VERSION ""

NS_ :

BS_:

BU_: WSM VT

BO_ 3221225472 VECTOR__INDEPENDENT_SIG_MSG: 0 Vector__XXX
 SG_ ArbitraryAddressCapable : 0|1@1+ (1,0) [0|1] "" Vector__XXX
 SG_ VehicleSystemInstance : 0|4@1+ (1,0) [0|15] "" Vector__XXX
 SG_ VehicleSystem : 0|7@1+ (1,0) [0|127] "" Vector__XXX
 SG_ VehicleSystem5 : 0|7@1+ (1,0) [0|127] "" Vector__XXX
 SG_ VehicleSystem4 : 0|7@1+ (1,0) [0|127] "" Vector__XXX
 SG_ VehicleSystem3 : 0|7@1+ (1,0) [0|127] "" Vector__XXX
 SG_ VehicleSystem2 : 0|7@1+ (1,0) [0|127] "" Vector__XXX
 SG_ VehicleSystem1 : 0|7@1+ (1,0) [0|127] "" Vector__XXX
 SG_ AreaPerTimeCapacity : 0|32@1- (1,0) [0|2147483647] "mm²/s" Vector__XXX
 SG_ Valve5ValveState : 0|4@1+ (1,0) [0|15] "" Vector__XXX
 SG_ Valve6LimitStatus : 0|3@1+ (1,0) [0|7] "" Vector__XXX
 SG_ Valve6ExtendedPortEstimatedFlow : 0|8@1+ (1,-125) [-125|125] "%" Vector__XXX
 SG_ Valve6RetractPortEstimatedFlow : 0|8@1+ (1,-125) [-125|125] "%" Vector__XXX
 SG_ Valve6ValveState : 0|4@1+ (1,0) [0|15] "" Vector__XXX
 SG_ Valve6FailSafeMode : 0|2@1+ (1,0) [0|3] "" Vector__XXX
 SG_ Valve7LimitStatus : 0|3@1+ (1,0) [0|7] "" Vector__XXX
 SG_ Valve7ExtendedPortEstimatedFlow : 0|8@1+ (1,-125) [-125|125] "%" Vector__XXX
 SG_ Valve7RetractPortEstimatedFlow : 0|8@1+ (1,-125) [-125|125] "%" Vector__XXX
 SG_ Valve7ValveState : 0|4@1+ (1,0) [0|15] "" Vector__XXX
 SG_ Valve7FailSafeMode : 0|2@1+ (1,0) [0|3] "" Vector__XXX
 SG_ Valve8LimitStatus : 0|3@1+ (1,0) [0|7] "" Vector__XXX
 SG_ Valve8ExtendedPortEstimatedFlow : 0|8@1+ (1,-125) [-125|125] "%" Vector__XXX
 SG_ Valve8RetractPortEstimatedFlow : 0|8@1+ (1,-125) [-125|125] "%" Vector__XXX
 SG_ Valve8ValveState : 0|4@1+ (1,0) [0|15] "" Vector__XXX
 SG_ Valve8FailSafeMode : 0|2@1+ (1,0) [0|3] "" Vector__XXX
 SG_ Valve9LimitStatus : 0|3@1+ (1,0) [0|7] "" Vector__XXX
 SG_ Valve9ExtendedPortEstimatedFlow : 0|8@1+ (1,-125) [-125|125] "%" Vector__XXX
 SG_ Valve9RetractPortEstimatedFlow : 0|8@1+ (1,-125) [-125|125] "%" Vector__XXX
 SG_ Valve9ValveState : 0|4@1+ (1,0) [0|15] "" Vector__XXX
 SG_ Valve9FailSafeMode : 0|2@1+ (1,0) [0|3] "" Vector__XXX
 SG_ Valve5ReturnPortPressure : 0|8@1+ (16,0) [0|4000] "kPa" Vector__XXX
 SG_ Valve6LimitStatus : 0|3@1+ (1,0) [0|7] "" Vector__XXX
 SG_ Valve6ExtendedPortMeasuredFlow : 0|8@1+ (1,-125) [-125|125] "%" Vector__XXX
 SG_ Valve6RetractPortMeasuredFlow : 0|8@1+ (1,-125) [-125|125] "%" Vector__XXX
 SG_ Valve6ExtendedPortPressure : 0|16@1+ (5,0) [0|321275] "kPa" Vector__XXX
 SG_ Valve6RetractPortPressure : 0|16@1+ (5,0) [0|321275] "kPa" Vector__XXX
 SG_ Valve6ReturnPortPressure : 0|8@1+ (16,0) [0|4000] "kPa" Vector__XXX
 SG_ Valve7LimitStatus : 0|3@1+ (1,0) [0|7] "" Vector__XXX
 SG_ Valve7ExtendedPortMeasuredFlow : 0|8@1+ (1,-125) [-125|125] "%" Vector__XXX
 SG_ Valve7RetractPortMeasuredFlow : 0|8@1+ (1,-125) [-125|125] "%" Vector__XXX
 SG_ Valve7ExtendedPortPressure : 0|16@1+ (5,0) [0|321275] "kPa" Vector__XXX
 SG_ Valve7RetractPortPressure : 0|16@1+ (5,0) [0|321275] "kPa" Vector__XXX
 SG_ Valve7ReturnPortPressure : 0|8@1+ (16,0) [0|4000] "kPa" Vector__XXX
 SG_ Valve8LimitStatus : 0|3@1+ (1,0) [0|7] "" Vector__XXX
 SG_ Valve8ExtendedPortMeasuredFlow : 0|8@1+ (1,-125) [-125|125] "%" Vector__XXX
 SG_ Valve8RetractPortMeasuredFlow : 0|8@1+ (1,-125) [-125|125] "%" Vector__XXX
 SG_ Valve8ExtendedPortPressure : 0|16@1+ (5,0) [0|321275] "kPa" Vector__XXX
 SG_ Valve8RetractPortPressure : 0|16@1+ (5,0) [0|321275] "kPa" Vector__XXX
 SG_ Valve8ReturnPortPressure : 0|8@1+ (16,0) [0|4000] "kPa" Vector__XXX
 SG_ Valve9LimitStatus : 0|3@1+ (1,0) [0|7] "" Vector__XXX
 SG_ Valve9ExtendedPortMeasuredFlow : 0|8@1+ (1,-125) [-125|125] "%" Vector__XXX
 SG_ Valve9RetractPortMeasuredFlow : 0|8@1+ (1,-125) [-125|125] "%" Vector__XXX
 SG_ Valve9ExtendedPortPressure : 0|16@1+ (5,0) [0|321275] "kPa" Vector__XXX
 SG_ Valve9RetractPortPressure : 0|16@1+ (5,0) [0|321275] "kPa" Vector__XXX
 SG_ Valve9ReturnPortPressure : 0|8@1+ (16,0) [0|4000] "kPa" Vector__XXX
 SG_ Valve5StateCmd : 0|4@1+ (1,0) [0|15] "" Vector__XXX
 SG_ Valve6PortFlowCmd : 0|8@1+ (0.4,0) [0|100] "%" Vector__XXX
 SG_ Valve6StateCmd : 0|4@1+ (1,0) [0|15] "" Vector__XXX
 SG_ Valve6FailSaveModeCmd : 0|2@1+ (1,0) [0|3] "" Vector__XXX
 SG_ Valve7PortFlowCmd : 0|8@1+ (0.4,0) [0|100] "%" Vector__XXX
 SG_ Valve7StateCmd : 0|4@1+ (1,0) [0|15] "" Vector__XXX
 SG_ Valve7FailSaveModeCmd : 0|2@1+ (1,0) [0|3] "" Vector__XXX
 SG_ Valve8PortFlowCmd : 0|8@1+ (0.4,0) [0|100] "%" Vector__XXX
 SG_ Valve8StateCmd : 0|4@1+ (1,0) [0|15] "" Vector__XXX
 SG_ Valve8FailSaveModeCmd : 0|2@1+ (1,0) [0|3] "" Vector__XXX
 SG_ Valve9PortFlowCmd : 0|8@1+ (0.4,0) [0|100] "%" Vector__XXX
 SG_ Valve9StateCmd : 0|4@1+ (1,0) [0|15] "" Vector__XXX
 SG_ Valve9FailSaveModeCmd : 0|2@1+ (1,0) [0|3] "" Vector__XXX
 SG_ ATTR_Archive : 0|1@1+ (1,0) [0|1] "" Vector__XXX
 SG_ ATTR_Directory : 0|1@1+ (1,0) [0|1] "" Vector__XXX
 SG_ ATTR_Hidden : 0|1@1+ (1,0) [0|1] "" Vector__XXX
 SG_ ATTR_Directory : 0|1@1+ (1,0) [0|1] "" Vector__XXX
 SG_ ATTR_Archive : 0|1@1+ (1,0) [0|1] "" Vector__XXX
 SG_ ValveState : 0|4@1+ (1,0) [0|15] "" Vector__XXX
 SG_ VTFunctionECUtoVT : 0|8@1+ (1,0) [0|255] "" Vector__XXX
 SG_ KeyActivationCode : 0|8@1+ (1,0) [0|2] "" Vector__XXX
 SG_ KeyObjectParentID : 0|16@1+ (1,0) [0|65535] "" Vector__XXX
 SG_ KeyObjectID : 0|16@1+ (1,0) [0|65535] "" Vector__XXX
 SG_ SoftKeyCode : 0|8@1+ (1,0) [0|255] "" Vector__XXX
 SG_ ButtonActivationCode : 0|8@1+ (1,0) [0|2] "" Vector__XXX
 SG_ ButtonObjectID : 0|16@1+ (1,0) [0|65535] "" Vector__XXX
 SG_ ButtonObjectParentID : 0|16@1+ (1,0) [0|65535] "" Vector__XXX
 SG_ ButtonKeyCode : 0|8@1+ (1,0) [0|255] "" Vector__XXX
 SG_ XPosition : 0|16@1+ (1,0) [0|65535] "" Vector__XXX
 SG_ YPosition : 0|16@1+ (1,0) [0|65535] "" Vector__XXX
 SG_ TouchState : 0|8@1+ (1,0) [0|255] "" Vector__XXX
 SG_ VTSelectInputObjectID : 0|16@1+ (1,0) [0|65535] "" Vector__XXX
 SG_ VTSelectInputObjectStatus : 0|8@1+ (1,0) [0|1] "" Vector__XXX
 SG_ VTEscObjectID : 0|16@1+ (1,0) [0|65535] "" Vector__XXX
 SG_ VTChangeNumericValueObjectID : 0|16@1+ (1,0) [0|65535] "" Vector__XXX
 SG_ VTChangeNumericValueValue : 0|32@1+ (1,0) [0|4294967295] "" Vector__XXX
 SG_ VTChangeActiveMaskObjectID : 0|16@1+ (1,0) [0|65535] "" Vector__XXX
 SG_ VTChangeSoftKeyMaskParentID : 0|16@1+ (1,0) [0|65535] "" Vector__XXX
 SG_ VTChangeSoftKeyMaskObjectID : 0|16@1+ (1,0) [0|65535] "" Vector__XXX
 SG_ ParentObjectID : 0|16@1+ (1,0) [0|65535] "" Vector__XXX
 SG_ ObjectToChangeStringValueID : 0|16@1+ (1,0) [0|65535] "" Vector__XXX
 SG_ DisplayActivationStatus1 : 0|1@1+ (1,0) [0|1] "" Vector__XXX
 SG_ VisibleDataAlarmMaskID : 0|16@1+ (1,0) [0|65535] "" Vector__XXX
 SG_ VisibleSoftKeyMaskID : 0|16@1+ (1,0) [0|65535] "" Vector__XXX
 SG_ ObjectPoolRecord : 0|56@1+ (1,0) [0|3338120000] "" Vector__XXX
 SG_ AuxiliaryFunctionObjectID : 0|16@1+ (1,0) [0|65535] "" Vector__XXX
 SG_ AssignmentErrorNotAccepted : 0|1@1+ (1,0) [0|1] "" Vector__XXX
 SG_ NumberOfInpuUnits : 0|8@1+ (1,0) [0|255] "" Vector__XXX
 SG_ IsEnabled : 0|8@1+ (1,0) [0|255] "" Vector__XXX
 SG_ AuxModelIdentification : 0|16@1+ (1,0) [0|65535] "" Vector__XXX
 SG_ InputStatusObjectId : 0|16@1+ (1,0) [0|255] "" Vector__XXX
 SG_ AuxInputEnable : 0|8@1+ (1,0) [0|1] "" Vector__XXX
 SG_ AuxErrorInvalidInputID : 0|1@1+ (1,0) [0|1] "" Vector__XXX
 SG_ AuxErrorAnyOther : 0|1@1+ (1,0) [0|1] "" Vector__XXX
 SG_ ObjectToShowHideID : 0|16@1+ (1,0) [0|65535] "" Vector__XXX
 SG_ ShowOrHide : 0|8@1+ (1,0) [0|1] "" Vector__XXX
 SG_ ObjectoEnableDisbaleID : 0|16@1+ (1,0) [0|65535] "" Vector__XXX
 SG_ EnableOrDisable : 0|8@1+ (1,0) [0|1] "" Vector__XXX
 SG_ SelectInputObjectID : 0|16@1+ (1,0) [0|65535] "" Vector__XXX
 SG_ SetFocusOpenForEditing : 0|8@1+ (1,0) [0|255] "" Vector__XXX
 SG_ NumberOfRepetitions_Audio : 0|8@1+ (1,0) [0|255] "" Vector__XXX
 SG_ Frequency_Audio : 0|16@1+ (1,0) [0|65535] "hz" Vector__XXX
 SG_ OnTimeDuration_Audio : 0|16@1+ (1,0) [0|65535] "ms" Vector__XXX
 SG_ OffTimeDuration_Audio : 0|16@1+ (1,0) [0|65535] "ms" Vector__XXX
 SG_ AudioVolume : 0|8@1+ (1,0) [0|100] "%" Vector__XXX
 SG_ ParentObjectID : 0|16@1+ (1,0) [0|65535] "" Vector__XXX
 SG_ ObjectToMoveID : 0|16@1+ (1,0) [0|65535] "" Vector__XXX
 SG_ XPosChangeTopLeft : 0|8@1+ (1,-127) [-127|128] "" Vector__XXX
 SG_ YPosChangeTopLeft : 0|8@1+ (1,-127) [-127|128] "" Vector__XXX
 SG_ ObjectToSizeID : 0|16@1+ (1,0) [0|65535] "" Vector__XXX
 SG_ NewWidth : 0|16@1+ (1,0) [0|65535] "" Vector__XXX
 SG_ NewHeight : 0|16@1+ (1,0) [0|65535] "" Vector__XXX
 SG_ ObjectToChangeColourID : 0|16@1+ (1,0) [0|65535] "" Vector__XXX
 SG_ NewBackgroundColour : 0|8@1+ (1,0) [0|255] "" Vector__XXX
 SG_ ObjectToChangeNumValueID : 0|16@1+ (1,0) [0|65535] "" Vector__XXX
 SG_ NewValue : 0|32@1+ (1,0) [0|65535] "" Vector__XXX
 SG_ ObjectToChangeEndPointID : 0|16@1+ (1,0) [0|65535] "" Vector__XXX
 SG_ Width : 0|16@1+ (1,0) [0|65535] "" Vector__XXX
 SG_ Height : 0|16@1+ (1,0) [0|65535] "" Vector__XXX
 SG_ LineDirection : 0|8@1+ (1,0) [0|1] "" Vector__XXX
 SG_ ObjectToChangeFontID : 0|16@1+ (1,0) [0|65535] "" Vector__XXX
 SG_ FontColour : 0|8@1+ (1,0) [0|255] "" Vector__XXX
 SG_ FontSize : 0|8@1+ (1,0) [0|255] "" Vector__XXX
 SG_ FontType : 0|8@1+ (1,0) [0|255] "" Vector__XXX
 SG_ FontStyle : 0|8@1+ (1,0) [0|255] "" Vector__XXX
 SG_ ObjectToChangeLineAttributesID : 0|16@1+ (1,0) [0|65535] "" Vector__XXX
 SG_ LineColour : 0|8@1+ (1,0) [0|255] "" Vector__XXX
 SG_ LineWidth : 0|8@1+ (1,0) [0|255] "" Vector__XXX
 SG_ LineArt : 0|16@1+ (1,0) [0|65535] "" Vector__XXX
 SG_ ObjectToChangeFillAttributesID : 0|16@1+ (1,0) [0|65535] "" Vector__XXX
 SG_ FillType : 0|8@1+ (1,0) [0|255] "" Vector__XXX
 SG_ FillColour : 0|8@1+ (1,0) [0|255] "" Vector__XXX
 SG_ FillPatternObjectID : 0|16@1+ (1,0) [0|65535] "" Vector__XXX
 SG_ WorkingSetObjectID : 0|16@1+ (1,0) [0|65535] "" Vector__XXX
 SG_ NewActiveMaskObjectID : 0|16@1+ (1,0) [0|65535] "" Vector__XXX
 SG_ MaskType : 0|8@1+ (1,0) [0|255] "" Vector__XXX
 SG_ DataOrAlarmMaskObjectID : 0|16@1+ (1,0) [0|65535] "" Vector__XXX
 SG_ NewSoftKeyMaskObjectID : 0|16@1+ (1,0) [0|65535] "" Vector__XXX
 SG_ ObjectToChangeAttributeID : 0|16@1+ (1,0) [0|65535] "" Vector__XXX
 SG_ AttributeID : 0|8@1+ (1,0) [0|16777200] "" Vector__XXX
 SG_ NewAttributeValue : 0|32@1+ (1,0) [0|0] "" Vector__XXX
 SG_ AlarmMaskObjectID : 0|16@1+ (1,0) [0|65535] "" Vector__XXX
 SG_ NewPriority : 0|8@1+ (1,0) [0|255] "" Vector__XXX
 SG_ ListInputObjectID : 0|16@1+ (1,0) [0|65535] "" Vector__XXX
 SG_ ListIndex : 0|8@1+ (1,0) [0|255] "" Vector__XXX
 SG_ NewObjectID : 0|16@1+ (1,0) [0|65535] "" Vector__XXX
 SG_ ObjectToChangeStringValueID : 0|16@1+ (1,0) [0|65535] "" Vector__XXX
 SG_ NewStringValue : 0|16@1+ (1,0) [0|65535] "" Vector__XXX
 SG_ ParentObjectID : 0|16@1+ (1,0) [0|65535] "" Vector__XXX
 SG_ ObjectToMoveID : 0|16@1+ (1,0) [0|65535] "" Vector__XXX
 SG_ XPosChangeTopLeftLong : 0|16@1- (1,0) [-32768|32767] "" Vector__XXX
 SG_ YPosChangeTopLeftLong : 0|16@1- (1,0) [-32768|32767] "" Vector__XXX
 SG_ ObjectToAssociateLabelWithID : 0|16@1+ (1,0) [0|65535] "" Vector__XXX
 SG_ StringVariableObjectID : 0|16@1+ (1,0) [0|65535] "" Vector__XXX
 SG_ GraphicRepresentationObjectID : 0|16@1+ (1,0) [0|255] "" Vector__XXX
 SG_ FontType : 0|8@1+ (1,0) [0|255] "" Vector__XXX
 SG_ PolygonObjectToChangeID : 0|16@1+ (1,0) [0|65535] "" Vector__XXX
 SG_ IndexOfThePointToReplace : 0|8@1+ (1,0) [0|255] "" Vector__XXX
 SG_ NewValueX : 0|16@1+ (1,0) [0|65535] "" Vector__XXX
 SG_ NewValueY : 0|16@1+ (1,0) [0|65535] "" Vector__XXX
 SG_ PolygonObjectToScaleID : 0|16@1+ (1,0) [0|65535] "" Vector__XXX
 SG_ NewWidthAttribute : 0|16@1+ (1,0) [0|65535] "" Vector__XXX
 SG_ NewHeigthAttribute : 0|16@1+ (1,0) [0|0] "" Vector__XXX
 SG_ GraphicsContextObjectID : 0|16@1+ (1,0) [0|65535] "" Vector__XXX
 SG_ SubCommandID : 0|8@1+ (1,0) [0|0] "" Vector__XXX
 SG_ ObjectToGetAttributeID : 0|16@1+ (1,0) [0|65535] "" Vector__XXX
 SG_ AttributeID : 0|8@1+ (1,0) [0|0] "" Vector__XXX
 SG_ ColourMapObjectID : 0|16@1+ (1,0) [0|65535] "" Vector__XXX
 SG_ LockUnlockCommand : 0|8@1+ (1,0) [0|1] "" Vector__XXX
 SG_ ObjectIDOfDataMaskToLock : 0|16@1+ (1,0) [0|65535] "" Vector__XXX
 SG_ LockTimeout : 0|16@1+ (1,0) [0|65535] "" Vector__XXX
 SG_ MacroObjecID : 0|8@1+ (1,0) [0|255] "" Vector__XXX
 SG_ MemoryRequired : 0|24@1+ (1,0) [0|16777200] "" Vector__XXX
 SG_ CodePlane : 0|8@1+ (1,0) [0|16] "" Vector__XXX
 SG_ FirstWideChar : 0|16@1+ (1,0) [0|65535] "" Vector__XXX
 SG_ LastWideChar : 0|16@1+ (1,0) [0|65535] "" Vector__XXX
 SG_ VersionLabelToStore : 0|56@1+ (1,0) [0|3338120000] "" Vector__XXX
 SG_ VersionLabelToLoad : 0|56@1+ (1,0) [0|3338120000] "" Vector__XXX
 SG_ VersionLabelToDelete : 0|56@1+ (1,0) [0|3338120000] "" Vector__XXX
 SG_ WSMaintenanceInitiating : 0|1@1+ (1,0) [0|1] "" Vector__XXX
 SG_ WSMaintenanceBitmask : 0|1@1+ (1,0) [0|1] "" Vector__XXX

BO_ 2565340673 VT21_WSM: 8 WSM
 SG_ VTFunctionECUtoVT M : 0|8@1+ (1,0) [0|255] "" Vector__XXX
 SG_ KeyActivationCode m0 : 8|8@1+ (1,0) [0|2] "" Vector__XXX
 SG_ KeyObjectParentID m0 : 32|16@1+ (1,0) [0|65535] "" Vector__XXX
 SG_ KeyObjectID m0 : 16|16@1+ (1,0) [0|65535] "" Vector__XXX
 SG_ SoftKeyCode m0 : 48|8@1+ (1,0) [0|255] "" Vector__XXX
 SG_ ButtonActivationCode m1 : 8|8@1+ (1,0) [0|2] "" Vector__XXX
 SG_ ButtonObjectID m1 : 16|16@1+ (1,0) [0|65535] "" Vector__XXX
 SG_ ButtonObjectParentID m1 : 32|16@1+ (1,0) [0|65535] "" Vector__XXX
 SG_ ButtonKeyCode m1 : 48|8@1+ (1,0) [0|255] "" Vector__XXX
 SG_ XPosition m2 : 8|16@1+ (1,0) [0|65535] "" Vector__XXX
 SG_ YPosition m2 : 24|16@1+ (1,0) [0|65535] "" Vector__XXX
 SG_ TouchState m2 : 40|8@1+ (1,0) [0|255] "" Vector__XXX
 SG_ VTSelectInputObjectID m3 : 8|16@1+ (1,0) [0|65535] "" Vector__XXX
 SG_ VTSelectInputObjectStatus m3 : 24|8@1+ (1,0) [0|1] "" Vector__XXX
 SG_ VTEscObjectID m4 : 8|16@1+ (1,0) [0|65535] "" Vector__XXX
 SG_ VTChangeNumericValueObjectID m5 : 8|16@1+ (1,0) [0|65535] "" Vector__XXX
 SG_ VTChangeNumericValueValue m5 : 32|32@1+ (1,0) [0|4294967295] "" Vector__XXX
 SG_ VTChangeActiveMaskObjectID m6 : 8|16@1+ (1,0) [0|65535] "" Vector__XXX
 SG_ VTChangeSoftKeyMaskParentID m7 : 8|16@1+ (1,0) [0|65535] "" Vector__XXX
 SG_ VTChangeSoftKeyMaskObjectID m7 : 24|16@1+ (1,0) [0|65535] "" Vector__XXX
 SG_ ParentObjectID m8 : 8|16@1+ (1,0) [0|65535] "" Vector__XXX
 SG_ ObjectToChangeStringValueID_Resp m8 : 24|16@1+ (1,0) [0|65535] "" Vector__XXX
 SG_ DisplayActivationStatus1 m9 : 8|1@1+ (1,0) [0|1] "" Vector__XXX
 SG_ VisibleDataAlarmMaskID m9 : 16|16@1+ (1,0) [0|65535] "" Vector__XXX
 SG_ VisibleSoftKeyMaskID m9 : 32|16@1+ (1,0) [0|65535] "" Vector__XXX
 SG_ ObjectPoolRecord m17 : 8|56@1+ (1,0) [0|3338120000] "" Vector__XXX
 SG_ AuxiliaryFunctionObjectID m32 : 8|16@1+ (1,0) [0|65535] "" Vector__XXX
 SG_ AssignmentErrorNotAccepted m32 : 24|1@1+ (1,0) [0|1] "" Vector__XXX
 SG_ NumberOfInpuUnits m34 : 8|8@1+ (1,0) [0|255] "" Vector__XXX
 SG_ IsEnabled m33 : 48|8@1+ (1,0) [0|255] "" Vector__XXX
 SG_ AuxModelIdentification m35 : 8|16@1+ (1,0) [0|65535] "" Vector__XXX
 SG_ InputStatusObjectId m37 : 8|16@1+ (1,0) [0|255] "" Vector__XXX
 SG_ AuxInputEnable m37 : 24|8@1+ (1,0) [0|1] "" Vector__XXX
 SG_ AuxErrorInvalidInputID m37 : 32|1@1+ (1,0) [0|1] "" Vector__XXX
 SG_ AuxErrorAnyOther m37 : 33|1@1+ (1,0) [0|1] "" Vector__XXX
 SG_ ObjectToShowHideID m160 : 8|16@1+ (1,0) [0|65535] "" Vector__XXX
 SG_ ShowOrHide m160 : 24|8@1+ (1,0) [0|1] "" Vector__XXX
 SG_ ObjectoEnableDisbaleID m161 : 8|16@1+ (1,0) [0|65535] "" Vector__XXX
 SG_ EnableOrDisable m161 : 24|8@1+ (1,0) [0|1] "" Vector__XXX
 SG_ SelectInputObjectID m162 : 8|16@1+ (1,0) [0|65535] "" Vector__XXX
 SG_ SetFocusOpenForEditing m162 : 24|8@1+ (1,0) [0|255] "" Vector__XXX
 SG_ NumberOfRepetitions_Audio m163 : 8|8@1+ (1,0) [0|255] "" Vector__XXX
 SG_ Frequency_Audio m163 : 16|16@1+ (1,0) [0|65535] "hz" Vector__XXX
 SG_ OnTimeDuration_Audio m163 : 32|16@1+ (1,0) [0|65535] "ms" Vector__XXX
 SG_ OffTimeDuration_Audio m163 : 48|16@1+ (1,0) [0|65535] "ms" Vector__XXX
 SG_ AudioVolume m164 : 8|8@1+ (1,0) [0|100] "%" Vector__XXX
 SG_ ParentObjectID_Location m165 : 8|16@1+ (1,0) [0|65535] "" Vector__XXX
 SG_ ObjectToMoveID_Location m165 : 24|16@1+ (1,0) [0|65535] "" Vector__XXX
 SG_ XPosChangeTopLeft m165 : 40|8@1+ (1,-127) [-127|128] "" Vector__XXX
 SG_ YPosChangeTopLeft m165 : 48|8@1+ (1,-127) [-127|128] "" Vector__XXX
 SG_ ObjectToSizeID m166 : 8|16@1+ (1,0) [0|65535] "" Vector__XXX
 SG_ NewWidth m166 : 24|16@1+ (1,0) [0|65535] "" Vector__XXX
 SG_ NewHeight m166 : 40|16@1+ (1,0) [0|65535] "" Vector__XXX
 SG_ ObjectToChangeColourID m167 : 8|16@1+ (1,0) [0|65535] "" Vector__XXX
 SG_ NewBackgroundColour m167 : 24|8@1+ (1,0) [0|255] "" Vector__XXX
 SG_ ObjectToChangeNumValueID m168 : 8|16@1+ (1,0) [0|65535] "" Vector__XXX
 SG_ NewValue m168 : 32|32@1+ (1,0) [0|65535] "" Vector__XXX
 SG_ ObjectToChangeEndPointID m169 : 8|16@1+ (1,0) [0|65535] "" Vector__XXX
 SG_ Width m169 : 24|16@1+ (1,0) [0|65535] "" Vector__XXX
 SG_ Height m169 : 40|16@1+ (1,0) [0|65535] "" Vector__XXX
 SG_ LineDirection m169 : 56|8@1+ (1,0) [0|1] "" Vector__XXX
 SG_ ObjectToChangeFontID m170 : 8|16@1+ (1,0) [0|65535] "" Vector__XXX
 SG_ FontColour m170 : 24|8@1+ (1,0) [0|255] "" Vector__XXX
 SG_ FontSize m170 : 32|8@1+ (1,0) [0|255] "" Vector__XXX
 SG_ FontType m170 : 40|8@1+ (1,0) [0|255] "" Vector__XXX
 SG_ FontStyle m170 : 48|8@1+ (1,0) [0|255] "" Vector__XXX
 SG_ ObjectToChangeLineAttributesID m171 : 8|16@1+ (1,0) [0|65535] "" Vector__XXX
 SG_ LineColour m171 : 24|8@1+ (1,0) [0|255] "" Vector__XXX
 SG_ LineWidth m171 : 32|8@1+ (1,0) [0|255] "" Vector__XXX
 SG_ LineArt m171 : 40|16@1+ (1,0) [0|65535] "" Vector__XXX
 SG_ ObjectToChangeFillAttributesID m172 : 8|16@1+ (1,0) [0|65535] "" Vector__XXX
 SG_ FillType m172 : 24|8@1+ (1,0) [0|255] "" Vector__XXX
 SG_ FillColour m172 : 32|8@1+ (1,0) [0|255] "" Vector__XXX
 SG_ FillPatternObjectID m172 : 40|16@1+ (1,0) [0|65535] "" Vector__XXX
 SG_ WorkingSetObjectID m173 : 8|16@1+ (1,0) [0|65535] "" Vector__XXX
 SG_ NewActiveMaskObjectID m173 : 24|16@1+ (1,0) [0|65535] "" Vector__XXX
 SG_ MaskType m174 : 8|8@1+ (1,0) [0|255] "" Vector__XXX
 SG_ DataOrAlarmMaskObjectID m174 : 16|16@1+ (1,0) [0|65535] "" Vector__XXX
 SG_ NewSoftKeyMaskObjectID m174 : 32|16@1+ (1,0) [0|65535] "" Vector__XXX
 SG_ ObjectToChangeAttributeID m175 : 8|16@1+ (1,0) [0|65535] "" Vector__XXX
 SG_ AttributeID_Change m175 : 24|8@1+ (1,0) [0|16777200] "" Vector__XXX
 SG_ NewAttributeValue m175 : 32|32@1+ (1,0) [0|0] "" Vector__XXX
 SG_ AlarmMaskObjectID m176 : 8|16@1+ (1,0) [0|65535] "" Vector__XXX
 SG_ NewPriority m176 : 24|8@1+ (1,0) [0|255] "" Vector__XXX
 SG_ ListInputObjectID m177 : 8|16@1+ (1,0) [0|65535] "" Vector__XXX
 SG_ ListIndex m177 : 24|8@1+ (1,0) [0|255] "" Vector__XXX
 SG_ NewObjectID m177 : 32|16@1+ (1,0) [0|65535] "" Vector__XXX
 SG_ ObjectToChangeStringValueID m179 : 8|16@1+ (1,0) [0|65535] "" Vector__XXX
 SG_ NewStringValue m179 : 24|16@1+ (1,0) [0|65535] "" Vector__XXX
 SG_ ParentObjectID_Position m180 : 8|16@1+ (1,0) [0|65535] "" Vector__XXX
 SG_ ObjectToMoveID_Position m180 : 24|16@1+ (1,0) [0|65535] "" Vector__XXX
 SG_ XPosChangeTopLeftLong m180 : 40|16@1- (1,0) [-32768|32767] "" Vector__XXX
 SG_ YPosChangeTopLeftLong m180 : 56|16@1- (1,0) [-32768|32767] "" Vector__XXX
 SG_ ObjectToAssociateLabelWithID m181 : 8|16@1+ (1,0) [0|65535] "" Vector__XXX
 SG_ StringVariableObjectID m181 : 24|16@1+ (1,0) [0|65535] "" Vector__XXX
 SG_ GraphicRepresentationObjectID m181 : 48|16@1+ (1,0) [0|255] "" Vector__XXX
 SG_ LabelFontType m181 : 40|8@1+ (1,0) [0|255] "" Vector__XXX
 SG_ PolygonObjectToChangeID m182 : 8|16@1+ (1,0) [0|65535] "" Vector__XXX
 SG_ IndexOfThePointToReplace m182 : 24|8@1+ (1,0) [0|255] "" Vector__XXX
 SG_ NewValueX m182 : 32|16@1+ (1,0) [0|65535] "" Vector__XXX
 SG_ NewValueY m182 : 48|16@1+ (1,0) [0|65535] "" Vector__XXX
 SG_ PolygonObjectToScaleID m183 : 8|16@1+ (1,0) [0|65535] "" Vector__XXX
 SG_ NewWidthAttribute m183 : 24|16@1+ (1,0) [0|65535] "" Vector__XXX
 SG_ NewHeigthAttribute m183 : 40|16@1+ (1,0) [0|0] "" Vector__XXX
 SG_ GraphicsContextObjectID m184 : 8|16@1+ (1,0) [0|65535] "" Vector__XXX
 SG_ SubCommandID m184 : 24|8@1+ (1,0) [0|0] "" Vector__XXX
 SG_ ObjectToGetAttributeID m185 : 8|16@1+ (1,0) [0|65535] "" Vector__XXX
 SG_ AttributeID m185 : 24|8@1+ (1,0) [0|0] "" Vector__XXX
 SG_ ColourMapObjectID m186 : 8|16@1+ (1,0) [0|65535] "" Vector__XXX
 SG_ LockUnlockCommand m189 : 8|8@1+ (1,0) [0|1] "" Vector__XXX
 SG_ ObjectIDOfDataMaskToLock m189 : 16|16@1+ (1,0) [0|65535] "" Vector__XXX
 SG_ LockTimeout m189 : 32|16@1+ (1,0) [0|65535] "" Vector__XXX
 SG_ MacroObjecID m190 : 8|8@1+ (1,0) [0|255] "" Vector__XXX
 SG_ MemoryRequired m192 : 16|24@1+ (1,0) [0|16777200] "" Vector__XXX
 SG_ CodePlane m193 : 8|8@1+ (1,0) [0|16] "" Vector__XXX
 SG_ FirstWideChar m193 : 16|16@1+ (1,0) [0|65535] "" Vector__XXX
 SG_ LastWideChar m193 : 32|16@1+ (1,0) [0|65535] "" Vector__XXX
 SG_ VersionLabelToStore m208 : 8|56@1+ (1,0) [0|3338120000] "" Vector__XXX
 SG_ VersionLabelToLoad m209 : 8|56@1+ (1,0) [0|3338120000] "" Vector__XXX
 SG_ VersionLabelToDelete m210 : 8|56@1+ (1,0) [0|3338120000] "" Vector__XXX
 SG_ WSMaintenanceInitiating m255 : 8|1@1+ (1,0) [0|1] "" Vector__XXX
 SG_ WSMaintenanceBitmask m255 : 15|1@1+ (1,0) [0|1] "" Vector__XXX

BO_ 2633895169 WSMSTR_WSM: 8 WSM
 SG_ NumberOfMembersInWorkingSet : 0|8@1+ (1,0) [1|250] "" Vector__XXX

BO_ 2565799425 ACL_WSM: 8 WSM
 SG_ ArbitraryAddressCapable : 63|1@1+ (1,0) [0|1] "" Vector__XXX
 SG_ IndustryGroup M : 60|3@1+ (1,0) [0|7] "" Vector__XXX
 SG_ VehicleSystemInstance : 56|4@1+ (1,0) [0|15] "" Vector__XXX
 SG_ Function : 40|8@1+ (1,0) [0|255] "" Vector__XXX
 SG_ FunctionInstance : 35|5@1+ (1,0) [0|31] "" Vector__XXX
 SG_ ECUInstance : 32|3@1+ (1,0) [0|7] "" Vector__XXX
 SG_ ManufacturerCode : 21|11@1+ (1,0) [0|2047] "" Vector__XXX
 SG_ IdentityNumber : 0|21@1+ (1,0) [0|2097150] "" Vector__XXX
 SG_ VehicleSystem m0 : 49|7@1+ (1,0) [0|127] "" Vector__XXX
 SG_ VehicleSystem5 m5 : 49|7@1+ (1,0) [0|127] "" Vector__XXX
 SG_ VehicleSystem4 m4 : 49|7@1+ (1,0) [0|127] "" Vector__XXX
 SG_ VehicleSystem3 m3 : 49|7@1+ (1,0) [0|127] "" Vector__XXX
 SG_ VehicleSystem2 m2 : 49|7@1+ (1,0) [0|127] "" Vector__XXX
 SG_ VehicleSystem1 m1 : 49|7@1+ (1,0) [0|127] "" Vector__XXX

BO_ 2565799678 ACL: 8 Vector__XXX
 SG_ ArbitraryAddressCapable : 63|1@1+ (1,0) [0|1] "" Vector__XXX
 SG_ IndustryGroup M : 60|3@1+ (1,0) [0|7] "" Vector__XXX
 SG_ VehicleSystemInstance : 56|4@1+ (1,0) [0|15] "" Vector__XXX
 SG_ Function : 40|8@1+ (1,0) [0|255] "" Vector__XXX
 SG_ FunctionInstance : 35|5@1+ (1,0) [0|31] "" Vector__XXX
 SG_ ECUInstance : 32|3@1+ (1,0) [0|7] "" Vector__XXX
 SG_ ManufacturerCode : 21|11@1+ (1,0) [0|2047] "" Vector__XXX
 SG_ IdentityNumber : 0|21@1+ (1,0) [0|2097150] "" Vector__XXX
 SG_ VehicleSystem m0 : 49|7@1+ (1,0) [0|127] "" Vector__XXX
 SG_ VehicleSystem5 m5 : 49|7@1+ (1,0) [0|127] "" Vector__XXX
 SG_ VehicleSystem4 m4 : 49|7@1+ (1,0) [0|127] "" Vector__XXX
 SG_ VehicleSystem3 m3 : 49|7@1+ (1,0) [0|127] "" Vector__XXX
 SG_ VehicleSystem2 m2 : 49|7@1+ (1,0) [0|127] "" Vector__XXX
 SG_ VehicleSystem1 m1 : 49|7@1+ (1,0) [0|127] "" Vector__XXX

BO_ 2632384254 VT12: 14 Vector__XXX
 SG_ AttributeID m185 : 24|8@1+ (1,0) [0|0] "" Vector__XXX
 SG_ VTFunctionVTtoECU M : 0|8@1+ (1,0) [0|255] "" Vector__XXX
 SG_ KeyActivationCode m0 : 8|8@1+ (1,0) [0|2] "" Vector__XXX
 SG_ KeyObjectID m0 : 16|16@1+ (1,0) [0|65535] "" Vector__XXX
 SG_ KeyObjectParentID m0 : 32|16@1+ (1,0) [0|65535] "" Vector__XXX
 SG_ SoftKeyCode m0 : 48|8@1+ (1,0) [0|255] "" Vector__XXX
 SG_ ButtonActivationCode m1 : 8|8@1+ (1,0) [0|2] "" Vector__XXX
 SG_ ButtonObjectID m1 : 16|16@1+ (1,0) [0|65535] "" Vector__XXX
 SG_ ButtonObjectParentID m1 : 32|16@1+ (1,0) [0|65535] "" Vector__XXX
 SG_ ButtonKeyCode m1 : 48|8@1+ (1,0) [0|255] "" Vector__XXX
 SG_ XPosition m2 : 8|16@1+ (1,0) [0|65535] "" Vector__XXX
 SG_ YPosition m2 : 24|16@1+ (1,0) [0|65535] "" Vector__XXX
 SG_ TouchState m2 : 40|8@1+ (1,0) [0|255] "" Vector__XXX
 SG_ VTSelectInputObjectID m3 : 8|16@1+ (1,0) [0|65535] "" Vector__XXX
 SG_ VTSelectInputObjectStatus m3 : 24|8@1+ (1,0) [0|1] "" Vector__XXX
 SG_ VTSelectInputObjectIsEdited m3 : 32|1@1+ (1,0) [0|1] "" Vector__XXX
 SG_ VTEscObjectID m4 : 8|16@1+ (1,0) [0|65535] "" Vector__XXX
 SG_ ErrorCodeVTEsc1 m4 : 24|1@1+ (1,0) [0|1] "" Vector__XXX
 SG_ ErrorCodeVTEsc2 m4 : 28|1@1+ (1,0) [0|1] "" Vector__XXX
 SG_ VTChangeNumericValueObjectID m5 : 8|16@1+ (1,0) [0|65535] "" Vector__XXX
 SG_ VTChangeNumericValueValue m5 : 32|32@1+ (1,0) [0|4294967295] "" Vector__XXX
 SG_ VTChangeActiveMaskObjectID m6 : 8|16@1+ (1,0) [0|65535] "" Vector__XXX
 SG_ ErrorCodeMissingObjects m6 : 26|1@1+ (1,0) [0|1] "" Vector__XXX
 SG_ ErrorCodeMaskOrChildObjectError m6 : 27|1@1+ (1,0) [0|1] "" Vector__XXX
 SG_ ErrorCodeAnyOtherError m6 : 28|1@1+ (1,0) [0|1] "" Vector__XXX
 SG_ ErrorCodePoolDeleted m6 : 29|1@1+ (1,0) [0|1] "" Vector__XXX
 SG_ VTChangeActiveMaskErrorID m6 : 32|16@1+ (1,0) [0|65535] "" Vector__XXX
 SG_ VTChangeActiveMaskParentID m6 : 48|16@1+ (1,0) [0|65535] "" Vector__XXX
 SG_ VTChangeSoftKeyMaskParentID m7 : 8|16@1+ (1,0) [0|65535] "" Vector__XXX
 SG_ VTChangeSoftKeyMaskObjectID m7 : 24|16@1+ (1,0) [0|65535] "" Vector__XXX
 SG_ ErrorCodeVTChangeSoftKeyMask1 m7 : 40|1@1+ (1,0) [0|1] "" Vector__XXX
 SG_ ErrorCodeVTChangeSoftKeyMask2 m7 : 41|1@1+ (1,0) [0|1] "" Vector__XXX
 SG_ ErrorCodeVTChangeSoftKeyMask3 m7 : 42|1@1+ (1,0) [0|1] "" Vector__XXX
 SG_ ErrorCodeVTChangeSoftKeyMask4 m7 : 43|1@1+ (1,0) [0|1] "" Vector__XXX
 SG_ ErrorCodeVTChangeSoftKeyMask5 m7 : 44|1@1+ (1,0) [0|1] "" Vector__XXX
 SG_ ObjectToChangeStringID m8 : 8|16@1+ (1,0) [0|65535] "" Vector__XXX
 SG_ EnteredStringValue m8 : 24|8@1+ (1,0) [0|255] "" Vector__XXX
 SG_ DisplayActivationStatus1 m9 : 8|1@1+ (1,0) [0|1] "" Vector__XXX
 SG_ VisibleDataAlarmMaskID m9 : 16|16@1+ (1,0) [0|65535] "" Vector__XXX
 SG_ VisibleSoftKeyMaskID m9 : 32|16@1+ (1,0) [0|65535] "" Vector__XXX
 SG_ ErrorCodeEndOfObjectPool1 m18 : 8|1@1+ (1,0) [0|1] "" Vector__XXX
 SG_ ErrorCodeEndOfObjectPool2 m18 : 9|1@1+ (1,0) [0|1] "" Vector__XXX
 SG_ ErrorCodeEndOfObjectPool3 m18 : 12|1@1+ (1,0) [0|1] "" Vector__XXX
 SG_ ParentObjectIdOfFaultyObject m18 : 16|16@1+ (1,0) [0|65535] "" Vector__XXX
 SG_ ObjectIdOfFaultyObject m18 : 32|16@1+ (1,0) [0|65535] "" Vector__XXX
 SG_ ErrorCodeObjectPool1 m18 : 48|1@1+ (1,0) [0|1] "" Vector__XXX
 SG_ ErrorCodeObjectPool2 m18 : 49|1@1+ (1,0) [0|1] "" Vector__XXX
 SG_ ErrorCodeObjectPool3 m18 : 50|1@1+ (1,0) [0|1] "" Vector__XXX
 SG_ ErrorCodeObjectPool4 m18 : 51|1@1+ (1,0) [0|1] "" Vector__XXX
 SG_ IdentityNumber m32 : 8|21@1+ (1,0) [0|2097150] "" Vector__XXX
 SG_ ManufacturerCode m32 : 29|11@1+ (1,0) [0|2047] "" Vector__XXX
 SG_ ECUInstance m32 : 40|3@1+ (1,0) [0|7] "" Vector__XXX
 SG_ FunctionInstance m32 : 43|5@1+ (1,0) [0|31] "" Vector__XXX
 SG_ AuxiliaryInputObjectID m32 : 80|16@1+ (1,0) [0|65535] "" Vector__XXX
 SG_ InputObjectId m33 : 8|16@1+ (1,0) [0|255] "" Vector__XXX
 SG_ Value1 m33 : 24|16@1+ (1,0) [0|65535] "" Vector__XXX
 SG_ Function m32 : 48|8@1+ (1,0) [0|255] "" Vector__XXX
 SG_ DeviceClass m32 : 57|7@1+ (1,0) [0|127] "" Vector__XXX
 SG_ IndustryGroup m32 : 64|3@1+ (1,0) [0|7] "" Vector__XXX
 SG_ DeviceClassInstance m32 : 67|4@1+ (1,0) [0|15] "" Vector__XXX
 SG_ SelfConfigurableAddress m32 : 71|1@1+ (1,0) [0|1] "" Vector__XXX
 SG_ AuxiliaryFunctionType m32 : 72|4@1+ (1,0) [0|15] "" Vector__XXX
 SG_ AuxiliaryFunctionObjectID m32 : 96|16@1+ (1,0) [0|65535] "" Vector__XXX
 SG_ Value2 m33 : 40|16@1+ (1,0) [0|65535] "" Vector__XXX
 SG_ AuxPreferredAssignmentRespError1 m34 : 8|1@1+ (1,0) [0|1] "" Vector__XXX
 SG_ AuxPreferredAssignmentRespError2 m34 : 9|1@1+ (1,0) [0|1] "" Vector__XXX
 SG_ AuxPreferredAssignmentRespError3 m34 : 10|1@1+ (1,0) [0|1] "" Vector__XXX
 SG_ AuxPreferredAssignmentRespError4 m34 : 11|1@1+ (1,0) [0|1] "" Vector__XXX
 SG_ InputStatusObjectId m37 : 8|16@1+ (1,0) [0|255] "" Vector__XXX
 SG_ AuxInputEnable m37 : 24|8@1+ (1,0) [0|1] "" Vector__XXX
 SG_ ObjectEscapeID m146 : 8|16@1+ (1,0) [0|65535] "" Vector__XXX
 SG_ ErrorCodeEscapeObj1 m146 : 24|1@1+ (1,0) [0|1] "" Vector__XXX
 SG_ ErrorCodeEscapeObj2 m146 : 28|1@1+ (1,0) [0|1] "" Vector__XXX
 SG_ ObjectToHideShowID m160 : 8|16@1+ (1,0) [0|65535] "" Vector__XXX
 SG_ ObjectShowStatus m160 : 24|8@1+ (1,0) [0|1] "" Vector__XXX
 SG_ ErrorCodeHideShowObj1 m160 : 32|1@1+ (1,0) [0|1] "" Vector__XXX
 SG_ ErrorCodeHideShowObj2 m160 : 33|1@1+ (1,0) [0|1] "" Vector__XXX
 SG_ ErrorCodeHideShowObj3 m160 : 35|1@1+ (1,0) [0|1] "" Vector__XXX
 SG_ ObjectToEnableDisableID m161 : 8|16@1+ (1,0) [0|65535] "" Vector__XXX
 SG_ ObjectEnableStatus m161 : 24|8@1+ (1,0) [0|1] "" Vector__XXX
 SG_ ErrorCodeEnableDisableObj1 m161 : 33|1@1+ (1,0) [0|1] "" Vector__XXX
 SG_ ErrorCodeEnableDisableObj2 m161 : 34|1@1+ (1,0) [0|1] "" Vector__XXX
 SG_ ErrorCodeEnableDisableObj3 m161 : 35|1@1+ (1,0) [0|1] "" Vector__XXX
 SG_ ErrorCodeEnableDisableObj4 m161 : 36|1@1+ (1,0) [0|1] "" Vector__XXX
 SG_ SelectInputObjectID m162 : 8|16@1+ (1,0) [0|65535] "" Vector__XXX
 SG_ ObjectSelectStatus m162 : 24|8@1+ (1,0) [0|2] "" Vector__XXX
 SG_ ErrorCodeSelectObject1 m162 : 32|1@1+ (1,0) [0|1] "" Vector__XXX
 SG_ ErrorCodeSelectObject2 m162 : 33|1@1+ (1,0) [0|1] "" Vector__XXX
 SG_ ErrorCodeSelectObject3 m162 : 34|1@1+ (1,0) [0|1] "" Vector__XXX
 SG_ ErrorCodeSelectObject4 m162 : 35|1@1+ (1,0) [0|1] "" Vector__XXX
 SG_ ErrorCodeSelectObject5 m162 : 36|1@1+ (1,0) [0|1] "" Vector__XXX
 SG_ ErrorCodeControlAudioDevice1 m163 : 8|1@1+ (1,0) [0|1] "" Vector__XXX
 SG_ ErrorCodeControlAudioDevice2 m163 : 12|1@1+ (1,0) [0|1] "" Vector__XXX
 SG_ ErrorCodeAudioVolume1 m164 : 8|1@1+ (1,0) [0|1] "" Vector__XXX
 SG_ ErrorCodeAudioVolume2 m164 : 12|1@1+ (1,0) [0|1] "" Vector__XXX
 SG_ ParentObjectID_ChildLoc m165 : 8|16@1+ (1,0) [0|65535] "" Vector__XXX
 SG_ ObjectToMoveID_Location m165 : 24|16@1+ (1,0) [0|65535] "" Vector__XXX
 SG_ ErrorCodeChangeChildLocation1 m165 : 40|1@1+ (1,0) [0|1] "" Vector__XXX
 SG_ ErrorCodeChangeChildLocation2 m165 : 41|1@1+ (1,0) [0|1] "" Vector__XXX
 SG_ ErrorCodeChangeChildLocation5 m165 : 44|1@1+ (1,0) [0|1] "" Vector__XXX
 SG_ ObjectToSizeID m166 : 8|16@1+ (1,0) [0|65535] "" Vector__XXX
 SG_ ErrorCodeObjToSize1 m166 : 24|1@1+ (1,0) [0|1] "" Vector__XXX
 SG_ ErrorCodeObjToSize2 m166 : 25|1@1+ (1,0) [0|1] "" Vector__XXX
 SG_ ErrorCodeObjToSize3 m166 : 26|1@1+ (1,0) [0|1] "" Vector__XXX
 SG_ ErrorCodeObjToSize4 m166 : 28|1@1+ (1,0) [0|1] "" Vector__XXX
 SG_ ObjectToChangeColourID m167 : 8|16@1+ (1,0) [0|65535] "" Vector__XXX
 SG_ NewBackgroundColour m167 : 24|8@1+ (1,0) [0|255] "" Vector__XXX
 SG_ ErrorCodeChangeColour1 m167 : 32|1@1+ (1,0) [0|1] "" Vector__XXX
 SG_ ErrorCodeChangeColour2 m167 : 33|1@1+ (1,0) [0|1] "" Vector__XXX
 SG_ ErrorCodeChangeColour3 m167 : 36|1@1+ (1,0) [0|1] "" Vector__XXX
 SG_ ObjectToChangeNumValueID m168 : 8|16@1+ (1,0) [0|65535] "" Vector__XXX
 SG_ ErrorCodeChangeNumValue1 m168 : 24|1@1+ (1,0) [0|1] "" Vector__XXX
 SG_ ErrorCodeChangeNumValue2 m168 : 25|1@1+ (1,0) [0|1] "" Vector__XXX
 SG_ ErrorCodeChangeNumValue3 m168 : 28|1@1+ (1,0) [0|1] "" Vector__XXX
 SG_ ValueOfTheObject m168 : 32|32@1+ (1,0) [0|2704] "" Vector__XXX
 SG_ ObjectToChangeEndPointID m169 : 8|16@1+ (1,0) [0|65535] "" Vector__XXX
 SG_ ErrorCodeChangeEditPoint1 m169 : 24|1@1+ (1,0) [0|1] "" Vector__XXX
 SG_ ErrorCodeChangeEditPoint2 m169 : 25|1@1+ (1,0) [0|1] "" Vector__XXX
 SG_ ErrorCodeChangeEditPoint3 m169 : 28|1@1+ (1,0) [0|1] "" Vector__XXX
 SG_ ObjectToChangeFontID m170 : 8|16@1+ (1,0) [0|65535] "" Vector__XXX
 SG_ ErrorCodeChangeFont1 m170 : 24|1@1+ (1,0) [0|1] "" Vector__XXX
 SG_ ErrorCodeChangeFont2 m170 : 25|1@1+ (1,0) [0|1] "" Vector__XXX
 SG_ ErrorCodeChangeFont4 m170 : 27|1@1+ (1,0) [0|1] "" Vector__XXX
 SG_ ErrorCodeChangeFont3 m170 : 26|1@1+ (1,0) [0|1] "" Vector__XXX
 SG_ ErrorCodeChangeFont5 m170 : 28|1@1+ (1,0) [0|1] "" Vector__XXX
 SG_ ErrorCodeChangeFont6 m170 : 29|1@1+ (1,0) [0|1] "" Vector__XXX
 SG_ ObjectToChangeLineAttributeID m171 : 8|16@1+ (1,0) [0|65535] "" Vector__XXX
 SG_ ErrorCodeChangeLineAttribute1 m171 : 24|1@1+ (1,0) [0|1] "" Vector__XXX
 SG_ ErrorCodeChangeLineAttribute2 m171 : 25|1@1+ (1,0) [0|1] "" Vector__XXX
 SG_ ErrorCodeChangeLineAttribute3 m171 : 26|1@1+ (1,0) [0|1] "" Vector__XXX
 SG_ ErrorCodeChangeLineAttribute4 m171 : 28|1@1+ (1,0) [0|1] "" Vector__XXX
 SG_ ObjectToChangeFillAttributesID m172 : 8|16@1+ (1,0) [0|65535] "" Vector__XXX
 SG_ ErrorCodeChangeFillAttributes1 m172 : 24|1@1+ (1,0) [0|1] "" Vector__XXX
 SG_ ErrorCodeChangeFillAttributes2 m172 : 25|1@1+ (1,0) [0|1] "" Vector__XXX
 SG_ ErrorCodeChangeFillAttributes3 m172 : 26|1@1+ (1,0) [0|1] "" Vector__XXX
 SG_ ErrorCodeChangeFillAttributes4 m172 : 27|1@1+ (1,0) [0|1] "" Vector__XXX
 SG_ ErrorCodeChangeFillAttributes5 m172 : 28|1@1+ (1,0) [0|1] "" Vector__XXX
 SG_ ActiveMaskObjectID m173 : 8|16@1+ (1,0) [0|0] "" Vector__XXX
 SG_ ErrorCodeChangeActiveMask1 m173 : 24|1@1+ (1,0) [0|1] "" Vector__XXX
 SG_ ErrorCodeChangeActiveMask2 m173 : 25|1@1+ (1,0) [0|1] "" Vector__XXX
 SG_ ErrorCodeChangeActiveMask3 m173 : 26|1@1+ (1,0) [0|1] "" Vector__XXX
 SG_ ErrorCodeChangeActiveMask4 m173 : 27|1@1+ (1,0) [0|1] "" Vector__XXX
 SG_ ErrorCodeChangeActiveMask5 m173 : 28|1@1+ (1,0) [0|1] "" Vector__XXX
 SG_ DataOrAlarmMaskObjectID m174 : 8|16@1+ (1,0) [0|65535] "" Vector__XXX
 SG_ SoftKeyMaskObjectID m174 : 24|16@1+ (1,0) [0|65535] "" Vector__XXX
 SG_ ErrorCodeChangeSoftKeyMask1 m174 : 40|1@1+ (1,0) [0|1] "" Vector__XXX
 SG_ ErrorCodeChangeSoftKeyMask2 m174 : 41|1@1+ (1,0) [0|1] "" Vector__XXX
 SG_ ErrorCodeChangeSoftKeyMask3 m174 : 42|1@1+ (1,0) [0|1] "" Vector__XXX
 SG_ ErrorCodeChangeSoftKeyMask4 m174 : 43|1@1+ (1,0) [0|1] "" Vector__XXX
 SG_ ErrorCodeChangeSoftKeyMask5 m174 : 44|1@1+ (1,0) [0|1] "" Vector__XXX
 SG_ ObjectToChangeAttributeID m175 : 8|16@1+ (1,0) [0|65535] "" Vector__XXX
 SG_ AttributeID_Change m175 : 24|8@1+ (1,0) [0|65535] "" Vector__XXX
 SG_ ErrorCodeChangeAttribute1 m175 : 32|1@1+ (1,0) [0|1] "" Vector__XXX
 SG_ ErrorCodeChangeAttribute2 m175 : 33|1@1+ (1,0) [0|1] "" Vector__XXX
 SG_ ErrorCodeChangeAttribute3 m175 : 34|1@1+ (1,0) [0|1] "" Vector__XXX
 SG_ ErrorCodeChangeAttribute4 m175 : 36|1@1+ (1,0) [0|1] "" Vector__XXX
 SG_ AlarmMaskObjectID m176 : 8|16@1+ (1,0) [0|65535] "" Vector__XXX
 SG_ NewPriority m176 : 24|8@1+ (1,0) [0|255] "" Vector__XXX
 SG_ ErrorCodeChangePriority1 m176 : 32|1@1+ (1,0) [0|1] "" Vector__XXX
 SG_ ErrorCodeChangePriority2 m176 : 33|1@1+ (1,0) [0|1] "" Vector__XXX
 SG_ ErrorCodeChangePriority3 m176 : 36|1@1+ (1,0) [0|1] "" Vector__XXX
 SG_ ListInputObjectID m177 : 8|16@1+ (1,0) [0|65535] "" Vector__XXX
 SG_ ListIndex m177 : 24|8@1+ (1,0) [0|255] "" Vector__XXX
 SG_ NewObjectID m177 : 32|16@1+ (1,0) [0|65535] "" Vector__XXX
 SG_ ErrorCodeChangeListItem1 m177 : 48|1@1+ (1,0) [0|1] "" Vector__XXX
 SG_ ErrorCodeChangeListItem2 m177 : 49|1@1+ (1,0) [0|1] "" Vector__XXX
 SG_ ErrorCodeChangeListItem3 m177 : 50|1@1+ (1,0) [0|1] "" Vector__XXX
 SG_ ErrorCodeChangeListItem4 m177 : 52|1@1+ (1,0) [0|1] "" Vector__XXX
 SG_ ErrorCodeDeleteObjectPool1 m178 : 8|1@1+ (1,0) [0|1] "" Vector__XXX
 SG_ ErrorCodeDeleteObjectPool2 m178 : 12|1@1+ (1,0) [0|1] "" Vector__XXX
 SG_ ParentObjectID_String m179 : 8|16@1+ (1,0) [0|65535] "" Vector__XXX
 SG_ ObjectToChangeStringValueID m179 : 24|16@1+ (1,0) [0|65535] "" Vector__XXX
 SG_ ErrorCodeChangeStrObjectID m179 : 41|1@1+ (1,0) [0|1] "" Vector__XXX
 SG_ ErrorCodeChangeStrTooLong m179 : 42|1@1+ (1,0) [0|1] "" Vector__XXX
 SG_ ErrorCodeChangeStrError m179 : 43|1@1+ (1,0) [0|1] "" Vector__XXX
 SG_ ParentObjectID_ChildPos m180 : 8|16@1+ (1,0) [0|65535] "" Vector__XXX
 SG_ ObjectToMoveID_Position m180 : 24|16@1+ (1,0) [0|65535] "" Vector__XXX
 SG_ ErrorCodeChangePosInvalidParent m180 : 40|1@1+ (1,0) [0|1] "" Vector__XXX
 SG_ ErrorCodeChangePosInvalidObject m180 : 41|1@1+ (1,0) [0|1] "" Vector__XXX
 SG_ ErrorCodeChangePosInvalidError m180 : 44|1@1+ (1,0) [0|1] "" Vector__XXX
 SG_ ErrorCodeSetObjectLabel1 m181 : 8|1@1+ (1,0) [0|1] "" Vector__XXX
 SG_ ErrorCodeSetObjectLabel2 m181 : 9|1@1+ (1,0) [0|1] "" Vector__XXX
 SG_ ErrorCodeSetObjectLabel3 m181 : 10|1@1+ (1,0) [0|1] "" Vector__XXX
 SG_ ErrorCodeSetObjectLabel4 m181 : 11|1@1+ (1,0) [0|1] "" Vector__XXX
 SG_ ErrorCodeSetObjectLabel5 m181 : 12|1@1+ (1,0) [0|1] "" Vector__XXX
 SG_ ErrorCodeSetObjectLabel6 m181 : 13|1@1+ (1,0) [0|1] "" Vector__XXX
 SG_ PolygonObjectToChangeID m182 : 8|16@1+ (1,0) [0|65535] "" Vector__XXX
 SG_ ErrorCodeChangePoygonPoint1 m182 : 24|1@1+ (1,0) [0|1] "" Vector__XXX
 SG_ ErrorCodeChangePoygonPoint2 m182 : 25|1@1+ (1,0) [0|1] "" Vector__XXX
 SG_ ErrorCodeChangePoygonPoint3 m182 : 26|1@1+ (1,0) [0|1] "" Vector__XXX
 SG_ PolygonObjectToScaleID m183 : 8|16@1+ (1,0) [0|65535] "" Vector__XXX
 SG_ NewWidthAttribute m183 : 24|16@1+ (1,0) [0|65535] "" Vector__XXX
 SG_ NewHeigthAttribute m183 : 40|16@1+ (1,0) [0|0] "" Vector__XXX
 SG_ ErrorCodeChangePolygonScale1 m183 : 56|1@1+ (1,0) [0|1] "" Vector__XXX
 SG_ ErrorCodeChangePolygonScale5 m183 : 60|1@1+ (1,0) [0|1] "" Vector__XXX
 SG_ GraphicsContextObjectID m184 : 8|16@1+ (1,0) [0|65535] "" Vector__XXX
 SG_ SubCommandID m184 : 24|8@1+ (1,0) [0|0] "" Vector__XXX
 SG_ ErrorCodeGraphicsContextCmd1 m184 : 32|1@1+ (1,0) [0|1] "" Vector__XXX
 SG_ ErrorCodeGraphicsContextCmd2 m184 : 33|1@1+ (1,0) [0|1] "" Vector__XXX
 SG_ ErrorCodeGraphicsContextCmd3 m184 : 34|1@1+ (1,0) [0|1] "" Vector__XXX
 SG_ ErrorCodeGraphicsContextCmd4 m184 : 35|1@1+ (1,0) [0|1] "" Vector__XXX
 SG_ ErrorCodeGraphicsContextCmd5 m184 : 36|1@1+ (1,0) [0|1] "" Vector__XXX
 SG_ ObjectToGetAttributeID_Resp m185 : 8|16@1+ (1,0) [0|65535] "" Vector__XXX
 SG_ ColourMapObjectID m186 : 8|16@1+ (1,0) [0|65535] "" Vector__XXX
 SG_ ErrorCodeSelectColourMap2 m186 : 25|1@1+ (1,0) [0|1] "" Vector__XXX
 SG_ ErrorCodeSelectColourMap1 m186 : 24|1@1+ (1,0) [0|1] "" Vector__XXX
 SG_ ErrorCodeLockUnlockMask9 m189 : 24|1@1+ (1,0) [0|1] "" Vector__XXX
 SG_ ErrorCodeLockUnlockMask8 m189 : 23|1@1+ (1,0) [0|1] "" Vector__XXX
 SG_ ErrorCodeLockUnlockMask7 m189 : 22|1@1+ (1,0) [0|1] "" Vector__XXX
 SG_ ErrorCodeLockUnlockMask6 m189 : 21|1@1+ (1,0) [0|1] "" Vector__XXX
 SG_ ErrorCodeLockUnlockMask5 m189 : 20|1@1+ (1,0) [0|1] "" Vector__XXX
 SG_ ErrorCodeLockUnlockMask4 m189 : 19|1@1+ (1,0) [0|1] "" Vector__XXX
 SG_ ErrorCodeLockUnlockMask3 m189 : 18|1@1+ (1,0) [0|1] "" Vector__XXX
 SG_ ErrorCodeLockUnlockMask2 m189 : 17|1@1+ (1,0) [0|1] "" Vector__XXX
 SG_ ErrorCodeLockUnlockMask1 m189 : 16|1@1+ (1,0) [0|1] "" Vector__XXX
 SG_ LockUnlockCommand m189 : 8|8@1+ (1,0) [0|1] "" Vector__XXX
 SG_ MacroObjecID m190 : 8|8@1+ (1,0) [0|255] "" Vector__XXX
 SG_ ErrorCodeExecuteMacro1 m190 : 16|1@1+ (1,0) [0|1] "" Vector__XXX
 SG_ ErrorCodeExecuteMacro2 m190 : 17|1@1+ (1,0) [0|1] "" Vector__XXX
 SG_ ErrorCodeExecuteMacro3 m190 : 18|1@1+ (1,0) [0|1] "" Vector__XXX
 SG_ VersionNumberISO11783Part6 m192 : 8|8@1+ (1,0) [0|255] "" Vector__XXX
 SG_ MemoryStatus m192 : 16|8@1+ (1,0) [0|1] "" Vector__XXX
 SG_ FirstWideChar m193 : 16|16@1+ (1,0) [0|65535] "" Vector__XXX
 SG_ LastWideChar m193 : 32|16@1+ (1,0) [0|65535] "" Vector__XXX
 SG_ ErrorCodeGetSupportedWideChars2 m193 : 52|1@1+ (1,0) [0|1] "" Vector__XXX
 SG_ ErrorCodeGetSupportedWideChars1 m193 : 48|1@1+ (1,0) [0|1] "" Vector__XXX
 SG_ CodePlane m193 : 8|8@1+ (1,0) [0|16] "" Vector__XXX
 SG_ NumberOfRanges m193 : 56|8@1+ (1,0) [0|255] "" Vector__XXX
 SG_ NavigationSoftKeys m194 : 8|8@1+ (1,0) [0|254] "" Vector__XXX
 SG_ XDotsForSoftKeyDescriptor m194 : 32|8@1+ (1,0) [0|255] "" Vector__XXX
 SG_ YDotsForSoftKeyDescriptor m194 : 40|8@1+ (1,0) [0|255] "" Vector__XXX
 SG_ NumberOfPossibleVirtualSoftKeys m194 : 48|8@1+ (1,0) [0|255] "" Vector__XXX
 SG_ NumberOfPhysicalSoftKeys m194 : 56|8@1+ (1,0) [0|255] "" Vector__XXX
 SG_ FontSize_8x8 m195 : 40|1@1+ (1,0) [0|1] "" Vector__XXX
 SG_ FontSize_8x12 m195 : 41|1@1+ (1,0) [0|1] "" Vector__XXX
 SG_ FontSize_12x16 m195 : 42|1@1+ (1,0) [0|1] "" Vector__XXX
 SG_ FontSize_16x16 m195 : 43|1@1+ (1,0) [0|1] "" Vector__XXX
 SG_ FontSize_16x24 m195 : 44|1@1+ (1,0) [0|1] "" Vector__XXX
 SG_ FontSize_24x32 m195 : 45|1@1+ (1,0) [0|1] "" Vector__XXX
 SG_ FontSize_32x32 m195 : 46|1@1+ (1,0) [0|1] "" Vector__XXX
 SG_ FontSize_32x48 m195 : 48|1@1+ (1,0) [0|1] "" Vector__XXX
 SG_ FontSize_48x64 m195 : 49|1@1+ (1,0) [0|1] "" Vector__XXX
 SG_ FontSize_64x64 m195 : 50|1@1+ (1,0) [0|1] "" Vector__XXX
 SG_ FontSize_64x96 m195 : 51|1@1+ (1,0) [0|1] "" Vector__XXX
 SG_ FontSize_96x128 m195 : 52|1@1+ (1,0) [0|1] "" Vector__XXX
 SG_ FontSize_128x128 m195 : 53|1@1+ (1,0) [0|1] "" Vector__XXX
 SG_ FontSize_128x192 m195 : 54|1@1+ (1,0) [0|1] "" Vector__XXX
 SG_ FontType_BoldText m195 : 56|1@1+ (1,0) [0|1] "" Vector__XXX
 SG_ FontType_CrossedOutText m195 : 57|1@1+ (1,0) [0|1] "" Vector__XXX
 SG_ FontType_UnderlinedText m195 : 58|1@1+ (1,0) [0|1] "" Vector__XXX
 SG_ FontType_ItalicsText m195 : 59|1@1+ (1,0) [0|1] "" Vector__XXX
 SG_ FontType_InvertedText m195 : 60|1@1+ (1,0) [0|1] "" Vector__XXX
 SG_ FontType_FlashInverted m195 : 61|1@1+ (1,0) [0|1] "" Vector__XXX
 SG_ FontType_FlashHidden m195 : 62|1@1+ (1,0) [0|1] "" Vector__XXX
 SG_ FontType_ProportionalFont m195 : 63|1@1+ (1,0) [0|1] "" Vector__XXX
 SG_ MaxLineWidth m196 : 8|8@1+ (1,0) [0|255] "" Vector__XXX
 SG_ LineArts m196 : 16|8@1+ (1,0) [0|1] "" Vector__XXX
 SG_ FillTypes m196 : 24|8@1+ (1,0) [0|1] "" Vector__XXX
 SG_ ShapeFillTypes m196 : 32|8@1+ (1,0) [0|3] "" Vector__XXX
 SG_ SupportedGrapicMode m199 : 16|8@1+ (1,0) [0|2] "" Vector__XXX
 SG_ Hardware1 m199 : 24|1@1+ (1,0) [0|1] "" Vector__XXX
 SG_ Hardware2 m199 : 25|1@1+ (1,0) [0|1] "" Vector__XXX
 SG_ Hardware3 m199 : 26|1@1+ (1,0) [0|1] "" Vector__XXX
 SG_ Hardware4 m199 : 27|1@1+ (1,0) [0|1] "" Vector__XXX
 SG_ Hardware5 m199 : 28|1@1+ (1,0) [0|1] "" Vector__XXX
 SG_ Hardware6 m199 : 29|1@1+ (1,0) [0|1] "" Vector__XXX
 SG_ NrOfXPixelsInDataAreaMask m199 : 32|16@1+ (1,0) [0|65535] "" Vector__XXX
 SG_ NrOfYPixelsInDataAreaMask m199 : 48|16@1+ (1,0) [0|65535] "" Vector__XXX
 SG_ AcknowledgmentStoreVersion m208 : 40|4@1+ (1,0) [0|8] "" Vector__XXX
 SG_ AcknowledgmentLoadVersion m209 : 40|4@1+ (1,0) [0|8] "" Vector__XXX
 SG_ AcknowledgmentDeleteVersion m210 : 40|4@1+ (1,0) [0|8] "" Vector__XXX
 SG_ NrOfVersionStrings m224 : 8|8@1+ (1,0) [0|255] "" Vector__XXX
 SG_ VersionLables m224 : 16|56@1+ (1,0) [0|0] "" Vector__XXX
 SG_ VTParentObjectID m240 : 8|16@1+ (1,0) [0|65535] "" Vector__XXX
 SG_ ObjectIDOfFaultyObject m240 : 24|16@1+ (1,0) [0|65535] "" Vector__XXX
 SG_ ErrorCodeVtObjPoolError1 m240 : 40|1@1+ (1,0) [0|1] "" Vector__XXX
 SG_ ErrorCodeVtObjPoolError2 m240 : 41|1@1+ (1,0) [0|1] "" Vector__XXX
 SG_ ErrorCodeVtObjPoolError3 m240 : 42|1@1+ (1,0) [0|1] "" Vector__XXX
 SG_ ErrorCodeVtObjPoolError4 m240 : 43|1@1+ (1,0) [0|1] "" Vector__XXX
 SG_ SourceAdressOfActiveWSM m254 : 8|8@1+ (1,0) [0|255] "" Vector__XXX
 SG_ VisibleDataOrAlarmMaskObjectID m254 : 16|16@1+ (1,0) [0|65535] "" Vector__XXX
 SG_ VisibleSoftKeyMaskObjectID m254 : 32|16@1+ (1,0) [0|65535] "" Vector__XXX
 SG_ VTBusyCode1 m254 : 48|1@1+ (1,0) [0|1] "" Vector__XXX
 SG_ VTBusyCode2 m254 : 49|1@1+ (1,0) [0|1] "" Vector__XXX
 SG_ VTBusyCode3 m254 : 50|1@1+ (1,0) [0|1] "" Vector__XXX
 SG_ VTBusyCode4 m254 : 51|1@1+ (1,0) [0|1] "" Vector__XXX
 SG_ VTBusyCode5 m254 : 52|1@1+ (1,0) [0|1] "" Vector__XXX
 SG_ VTBusyCode8 m254 : 55|1@1+ (1,0) [0|1] "" Vector__XXX
 SG_ VTFunctionCode m254 : 56|8@1+ (1,0) [0|255] "" Vector__XXX

BO_ 2565340926 VT21: 8 Vector__XXX
 SG_ VTFunctionECUtoVT M : 0|8@1+ (1,0) [0|255] "" Vector__XXX
 SG_ KeyActivationCode m0 : 8|8@1+ (1,0) [0|2] "" Vector__XXX
 SG_ KeyObjectParentID m0 : 32|16@1+ (1,0) [0|65535] "" Vector__XXX
 SG_ KeyObjectID m0 : 16|16@1+ (1,0) [0|65535] "" Vector__XXX
 SG_ SoftKeyCode m0 : 48|8@1+ (1,0) [0|255] "" Vector__XXX
 SG_ ButtonActivationCode m1 : 8|8@1+ (1,0) [0|2] "" Vector__XXX
 SG_ ButtonObjectID m1 : 16|16@1+ (1,0) [0|65535] "" Vector__XXX
 SG_ ButtonObjectParentID m1 : 32|16@1+ (1,0) [0|65535] "" Vector__XXX
 SG_ ButtonKeyCode m1 : 48|8@1+ (1,0) [0|255] "" Vector__XXX
 SG_ XPosition m2 : 8|16@1+ (1,0) [0|65535] "" Vector__XXX
 SG_ YPosition m2 : 24|16@1+ (1,0) [0|65535] "" Vector__XXX
 SG_ TouchState m2 : 40|8@1+ (1,0) [0|255] "" Vector__XXX
 SG_ VTSelectInputObjectID m3 : 8|16@1+ (1,0) [0|65535] "" Vector__XXX
 SG_ VTSelectInputObjectStatus m3 : 24|8@1+ (1,0) [0|1] "" Vector__XXX
 SG_ VTEscObjectID m4 : 8|16@1+ (1,0) [0|65535] "" Vector__XXX
 SG_ VTChangeNumericValueObjectID m5 : 8|16@1+ (1,0) [0|65535] "" Vector__XXX
 SG_ VTChangeNumericValueValue m5 : 32|32@1+ (1,0) [0|4294967295] "" Vector__XXX
 SG_ VTChangeActiveMaskObjectID m6 : 8|16@1+ (1,0) [0|65535] "" Vector__XXX
 SG_ VTChangeSoftKeyMaskParentID m7 : 8|16@1+ (1,0) [0|65535] "" Vector__XXX
 SG_ VTChangeSoftKeyMaskObjectID m7 : 24|16@1+ (1,0) [0|65535] "" Vector__XXX
 SG_ ParentObjectID m8 : 8|16@1+ (1,0) [0|65535] "" Vector__XXX
 SG_ ObjectToChangeStringValueID_Resp m8 : 24|16@1+ (1,0) [0|65535] "" Vector__XXX
 SG_ DisplayActivationStatus1 m9 : 8|1@1+ (1,0) [0|1] "" Vector__XXX
 SG_ VisibleDataAlarmMaskID m9 : 16|16@1+ (1,0) [0|65535] "" Vector__XXX
 SG_ VisibleSoftKeyMaskID m9 : 32|16@1+ (1,0) [0|65535] "" Vector__XXX
 SG_ ObjectPoolRecord m17 : 8|56@1+ (1,0) [0|3338120000] "" Vector__XXX
 SG_ AuxiliaryFunctionObjectID m32 : 8|16@1+ (1,0) [0|65535] "" Vector__XXX
 SG_ AssignmentErrorNotAccepted m32 : 24|1@1+ (1,0) [0|1] "" Vector__XXX
 SG_ NumberOfInpuUnits m34 : 8|8@1+ (1,0) [0|255] "" Vector__XXX
 SG_ IsEnabled m33 : 48|8@1+ (1,0) [0|255] "" Vector__XXX
 SG_ AuxModelIdentification m35 : 8|16@1+ (1,0) [0|65535] "" Vector__XXX
 SG_ InputStatusObjectId m37 : 8|16@1+ (1,0) [0|255] "" Vector__XXX
 SG_ AuxInputEnable m37 : 24|8@1+ (1,0) [0|1] "" Vector__XXX
 SG_ AuxErrorInvalidInputID m37 : 32|1@1+ (1,0) [0|1] "" Vector__XXX
 SG_ AuxErrorAnyOther m37 : 33|1@1+ (1,0) [0|1] "" Vector__XXX
 SG_ ObjectToShowHideID m160 : 8|16@1+ (1,0) [0|65535] "" Vector__XXX
 SG_ ShowOrHide m160 : 24|8@1+ (1,0) [0|1] "" Vector__XXX
 SG_ ObjectoEnableDisbaleID m161 : 8|16@1+ (1,0) [0|65535] "" Vector__XXX
 SG_ EnableOrDisable m161 : 24|8@1+ (1,0) [0|1] "" Vector__XXX
 SG_ SelectInputObjectID m162 : 8|16@1+ (1,0) [0|65535] "" Vector__XXX
 SG_ SetFocusOpenForEditing m162 : 24|8@1+ (1,0) [0|255] "" Vector__XXX
 SG_ NumberOfRepetitions_Audio m163 : 8|8@1+ (1,0) [0|255] "" Vector__XXX
 SG_ Frequency_Audio m163 : 16|16@1+ (1,0) [0|65535] "hz" Vector__XXX
 SG_ OnTimeDuration_Audio m163 : 32|16@1+ (1,0) [0|65535] "ms" Vector__XXX
 SG_ OffTimeDuration_Audio m163 : 48|16@1+ (1,0) [0|65535] "ms" Vector__XXX
 SG_ AudioVolume m164 : 8|8@1+ (1,0) [0|100] "%" Vector__XXX
 SG_ ParentObjectID_Location m165 : 8|16@1+ (1,0) [0|65535] "" Vector__XXX
 SG_ ObjectToMoveID_Location m165 : 24|16@1+ (1,0) [0|65535] "" Vector__XXX
 SG_ XPosChangeTopLeft m165 : 40|8@1+ (1,-127) [-127|128] "" Vector__XXX
 SG_ YPosChangeTopLeft m165 : 48|8@1+ (1,-127) [-127|128] "" Vector__XXX
 SG_ ObjectToSizeID m166 : 8|16@1+ (1,0) [0|65535] "" Vector__XXX
 SG_ NewWidth m166 : 24|16@1+ (1,0) [0|65535] "" Vector__XXX
 SG_ NewHeight m166 : 40|16@1+ (1,0) [0|65535] "" Vector__XXX
 SG_ ObjectToChangeColourID m167 : 8|16@1+ (1,0) [0|65535] "" Vector__XXX
 SG_ NewBackgroundColour m167 : 24|8@1+ (1,0) [0|255] "" Vector__XXX
 SG_ ObjectToChangeNumValueID m168 : 8|16@1+ (1,0) [0|65535] "" Vector__XXX
 SG_ NewValue m168 : 32|32@1+ (1,0) [0|65535] "" Vector__XXX
 SG_ ObjectToChangeEndPointID m169 : 8|16@1+ (1,0) [0|65535] "" Vector__XXX
 SG_ Width m169 : 24|16@1+ (1,0) [0|65535] "" Vector__XXX
 SG_ Height m169 : 40|16@1+ (1,0) [0|65535] "" Vector__XXX
 SG_ LineDirection m169 : 56|8@1+ (1,0) [0|1] "" Vector__XXX
 SG_ ObjectToChangeFontID m170 : 8|16@1+ (1,0) [0|65535] "" Vector__XXX
 SG_ FontColour m170 : 24|8@1+ (1,0) [0|255] "" Vector__XXX
 SG_ FontSize m170 : 32|8@1+ (1,0) [0|255] "" Vector__XXX
 SG_ FontType m170 : 40|8@1+ (1,0) [0|255] "" Vector__XXX
 SG_ FontStyle m170 : 48|8@1+ (1,0) [0|255] "" Vector__XXX
 SG_ ObjectToChangeLineAttributesID m171 : 8|16@1+ (1,0) [0|65535] "" Vector__XXX
 SG_ LineColour m171 : 24|8@1+ (1,0) [0|255] "" Vector__XXX
 SG_ LineWidth m171 : 32|8@1+ (1,0) [0|255] "" Vector__XXX
 SG_ LineArt m171 : 40|16@1+ (1,0) [0|65535] "" Vector__XXX
 SG_ ObjectToChangeFillAttributesID m172 : 8|16@1+ (1,0) [0|65535] "" Vector__XXX
 SG_ FillType m172 : 24|8@1+ (1,0) [0|255] "" Vector__XXX
 SG_ FillColour m172 : 32|8@1+ (1,0) [0|255] "" Vector__XXX
 SG_ FillPatternObjectID m172 : 40|16@1+ (1,0) [0|65535] "" Vector__XXX
 SG_ WorkingSetObjectID m173 : 8|16@1+ (1,0) [0|65535] "" Vector__XXX
 SG_ NewActiveMaskObjectID m173 : 24|16@1+ (1,0) [0|65535] "" Vector__XXX
 SG_ MaskType m174 : 8|8@1+ (1,0) [0|255] "" Vector__XXX
 SG_ DataOrAlarmMaskObjectID m174 : 16|16@1+ (1,0) [0|65535] "" Vector__XXX
 SG_ NewSoftKeyMaskObjectID m174 : 32|16@1+ (1,0) [0|65535] "" Vector__XXX
 SG_ ObjectToChangeAttributeID m175 : 8|16@1+ (1,0) [0|65535] "" Vector__XXX
 SG_ AttributeID_Change m175 : 24|8@1+ (1,0) [0|16777200] "" Vector__XXX
 SG_ NewAttributeValue m175 : 32|32@1+ (1,0) [0|0] "" Vector__XXX
 SG_ AlarmMaskObjectID m176 : 8|16@1+ (1,0) [0|65535] "" Vector__XXX
 SG_ NewPriority m176 : 24|8@1+ (1,0) [0|255] "" Vector__XXX
 SG_ ListInputObjectID m177 : 8|16@1+ (1,0) [0|65535] "" Vector__XXX
 SG_ ListIndex m177 : 24|8@1+ (1,0) [0|255] "" Vector__XXX
 SG_ NewObjectID m177 : 32|16@1+ (1,0) [0|65535] "" Vector__XXX
 SG_ ObjectToChangeStringValueID m179 : 8|16@1+ (1,0) [0|65535] "" Vector__XXX
 SG_ NewStringValue m179 : 24|16@1+ (1,0) [0|65535] "" Vector__XXX
 SG_ ParentObjectID_Position m180 : 8|16@1+ (1,0) [0|65535] "" Vector__XXX
 SG_ ObjectToMoveID_Position m180 : 24|16@1+ (1,0) [0|65535] "" Vector__XXX
 SG_ XPosChangeTopLeftLong m180 : 40|16@1- (1,0) [-32768|32767] "" Vector__XXX
 SG_ YPosChangeTopLeftLong m180 : 56|16@1- (1,0) [-32768|32767] "" Vector__XXX
 SG_ ObjectToAssociateLabelWithID m181 : 8|16@1+ (1,0) [0|65535] "" Vector__XXX
 SG_ StringVariableObjectID m181 : 24|16@1+ (1,0) [0|65535] "" Vector__XXX
 SG_ GraphicRepresentationObjectID m181 : 48|16@1+ (1,0) [0|255] "" Vector__XXX
 SG_ LabelFontType m181 : 40|8@1+ (1,0) [0|255] "" Vector__XXX
 SG_ PolygonObjectToChangeID m182 : 8|16@1+ (1,0) [0|65535] "" Vector__XXX
 SG_ IndexOfThePointToReplace m182 : 24|8@1+ (1,0) [0|255] "" Vector__XXX
 SG_ NewValueX m182 : 32|16@1+ (1,0) [0|65535] "" Vector__XXX
 SG_ NewValueY m182 : 48|16@1+ (1,0) [0|65535] "" Vector__XXX
 SG_ PolygonObjectToScaleID m183 : 8|16@1+ (1,0) [0|65535] "" Vector__XXX
 SG_ NewWidthAttribute m183 : 24|16@1+ (1,0) [0|65535] "" Vector__XXX
 SG_ NewHeigthAttribute m183 : 40|16@1+ (1,0) [0|0] "" Vector__XXX
 SG_ GraphicsContextObjectID m184 : 8|16@1+ (1,0) [0|65535] "" Vector__XXX
 SG_ SubCommandID m184 : 24|8@1+ (1,0) [0|0] "" Vector__XXX
 SG_ ObjectToGetAttributeID m185 : 8|16@1+ (1,0) [0|65535] "" Vector__XXX
 SG_ AttributeID m185 : 24|8@1+ (1,0) [0|0] "" Vector__XXX
 SG_ ColourMapObjectID m186 : 8|16@1+ (1,0) [0|65535] "" Vector__XXX
 SG_ LockUnlockCommand m189 : 8|8@1+ (1,0) [0|1] "" Vector__XXX
 SG_ ObjectIDOfDataMaskToLock m189 : 16|16@1+ (1,0) [0|65535] "" Vector__XXX
 SG_ LockTimeout m189 : 32|16@1+ (1,0) [0|65535] "" Vector__XXX
 SG_ MacroObjecID m190 : 8|8@1+ (1,0) [0|255] "" Vector__XXX
 SG_ MemoryRequired m192 : 16|24@1+ (1,0) [0|16777200] "" Vector__XXX
 SG_ CodePlane m193 : 8|8@1+ (1,0) [0|16] "" Vector__XXX
 SG_ FirstWideChar m193 : 16|16@1+ (1,0) [0|65535] "" Vector__XXX
 SG_ LastWideChar m193 : 32|16@1+ (1,0) [0|65535] "" Vector__XXX
 SG_ VersionLabelToStore m208 : 8|56@1+ (1,0) [0|3338120000] "" Vector__XXX
 SG_ VersionLabelToLoad m209 : 8|56@1+ (1,0) [0|3338120000] "" Vector__XXX
 SG_ VersionLabelToDelete m210 : 8|56@1+ (1,0) [0|3338120000] "" Vector__XXX
 SG_ WSMaintenanceInitiating m255 : 8|1@1+ (1,0) [0|1] "" Vector__XXX
 SG_ WSMaintenanceBitmask m255 : 15|1@1+ (1,0) [0|1] "" Vector__XXX

BO_ 2565537534 RQST: 3 Vector__XXX
 SG_ RqstedPGN : 0|24@1+ (1,0) [0|16777200] "" Vector__XXX

BO_ 2633895422 WSMSTR: 8 Vector__XXX
 SG_ NumberOfMembersInWorkingSet : 0|8@1+ (1,0) [1|250] "" Vector__XXX

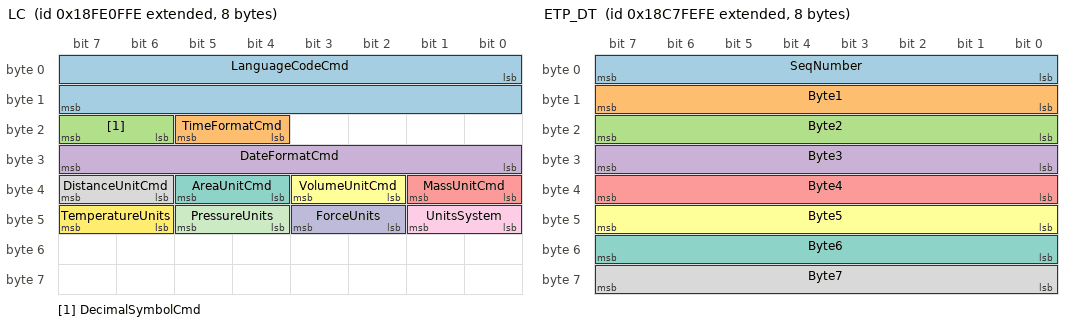
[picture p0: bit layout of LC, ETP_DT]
BO_ 2566787070 LC: 8 Vector__XXX
 SG_ LanguageCodeCmd : 0|16@1+ (1,0) [0|16383] "" Vector__XXX
 SG_ TimeFormatCmd : 20|2@1+ (1,0) [0|3] "" Vector__XXX
 SG_ DecimalSymbolCmd : 22|2@1+ (1,0) [0|3] "" Vector__XXX
 SG_ DateFormatCmd : 24|8@1+ (1,0) [0|255] "" Vector__XXX
 SG_ MassUnitCmd : 32|2@1+ (1,0) [0|3] "" Vector__XXX
 SG_ VolumeUnitCmd : 34|2@1+ (1,0) [0|3] "" Vector__XXX
 SG_ AreaUnitCmd : 36|2@1+ (1,0) [0|3] "" Vector__XXX
 SG_ DistanceUnitCmd : 38|2@1+ (1,0) [0|3] "" Vector__XXX
 SG_ UnitsSystem : 40|2@1+ (1,0) [0|3] "" Vector__XXX
 SG_ ForceUnits : 42|2@1+ (1,0) [0|3] "" Vector__XXX
 SG_ PressureUnits : 44|2@1+ (1,0) [0|3] "" Vector__XXX
 SG_ TemperatureUnits : 46|2@1+ (1,0) [0|3] "" Vector__XXX

BO_ 2563309310 ETP_CM: 8 Vector__XXX
 SG_ ConnectionAbortReason m255 : 8|8@1+ (1,0) [0|255] "" Vector__XXX
 SG_ ControlByte M : 0|8@1+ (1,0) [0|255] "" Vector__XXX
 SG_ ERtsMsgSize m20 : 8|32@1+ (1,0) [1786|117440505] "" Vector__XXX
 SG_ ECtsNoPackets m21 : 8|8@1+ (1,0) [1|255] "" Vector__XXX
 SG_ EDpoNoPackets m22 : 8|8@1+ (1,0) [1|255] "" Vector__XXX
 SG_ EAckMsgSize m23 : 8|32@1+ (1,0) [1786|117440505] "" Vector__XXX
 SG_ ECtsNextPacket m21 : 16|24@1+ (1,0) [1|16777215] "" Vector__XXX
 SG_ EDpoOffset m22 : 16|24@1+ (1,0) [0|16777215] "" Vector__XXX
 SG_ PGNumber : 40|24@1+ (1,0) [0|16777200] "" Vector__XXX

BO_ 2563243774 ETP_DT: 8 Vector__XXX
 SG_ SeqNumber : 0|8@1+ (1,0) [1|255] "" Vector__XXX
 SG_ Byte1 : 8|8@1+ (1,0) [0|255] "" Vector__XXX
 SG_ Byte2 : 16|8@1+ (1,0) [0|255] "" Vector__XXX
 SG_ Byte3 : 24|8@1+ (1,0) [0|255] "" Vector__XXX
 SG_ Byte4 : 32|8@1+ (1,0) [0|255] "" Vector__XXX
 SG_ Byte5 : 40|8@1+ (1,0) [0|255] "" Vector__XXX
 SG_ Byte6 : 48|8@1+ (1,0) [0|255] "" Vector__XXX
 SG_ Byte7 : 56|8@1+ (1,0) [0|255] "" Vector__XXX

CM_ BO_ 3221225472 "This is a message for not used signals, created by Vector CANdb++ DBC OLE DB Provider.";
CM_ SG_ 3221225472 AreaPerTimeCapacity "Area per time capacity";
CM_ SG_ 3221225472 Valve6LimitStatus "Parameter used to report the tractor ECUs present limit status associated with a parameter whose commands are persistentParameter used to report the tractor ECUs present limit status associated with a parameter whose commands are persistent";
CM_ SG_ 3221225472 Valve7LimitStatus "Parameter used to report the tractor ECUs present limit status associated with a parameter whose commands are persistentParameter used to report the tractor ECUs present limit status associated with a parameter whose commands are persistent";
CM_ SG_ 3221225472 Valve8LimitStatus "Parameter used to report the tractor ECUs present limit status associated with a parameter whose commands are persistentParameter used to report the tractor ECUs present limit status associated with a parameter whose commands are persistent";
CM_ SG_ 3221225472 Valve9LimitStatus "Parameter used to report the tractor ECUs present limit status associated with a parameter whose commands are persistentParameter used to report the tractor ECUs present limit status associated with a parameter whose commands are persistent";
CM_ SG_ 3221225472 ATTR_Archive "File Attribute ArchiveFile Attribute Archive";
CM_ SG_ 3221225472 ATTR_Directory "File Attribute DirectoryFile Attribute Directory";
CM_ SG_ 3221225472 AuxModelIdentification "Model Identification Code of the Auxiliary Input Unit";
CM_ SG_ 3221225472 AuxInputEnable "Auxiliary Input Enable";
CM_ SG_ 3221225472 AuxErrorInvalidInputID "Invalid Auxiliary Input Object ID";
CM_ SG_ 3221225472 AuxErrorAnyOther "Any other error";
CM_ BO_ 2565340673 "ECU to VT";
CM_ SG_ 2565340673 AuxModelIdentification "Model Identification Code of the Auxiliary Input Unit";
CM_ SG_ 2565340673 AuxInputEnable "Auxiliary Input Enable";
CM_ SG_ 2565340673 AuxErrorInvalidInputID "Invalid Auxiliary Input Object ID";
CM_ SG_ 2565340673 AuxErrorAnyOther "Any other error";
CM_ BO_ 2633895169 "Working Set Master";
CM_ BO_ 2565799425 "Address Claimed";
CM_ BO_ 2565799678 "Address Claimed";
CM_ BO_ 2632384254 "VT to ECU";
CM_ SG_ 2632384254 ErrorCodeAnyOtherError "VT change mask error code: Any other error";
CM_ SG_ 2632384254 ErrorCodePoolDeleted "VT change mask error code: Pool being deleted";
CM_ SG_ 2632384254 VTChangeActiveMaskErrorID "Object ID containing error";
CM_ SG_ 2632384254 VTChangeActiveMaskParentID "Parent object ID of error object ID";
CM_ SG_ 2632384254 AuxiliaryFunctionType "Auxiliary function type of assigned auxiliary input";
CM_ SG_ 2632384254 AuxInputEnable "Auxiliary Input Enable";
CM_ SG_ 2632384254 MaxLineWidth "Maximum pen and line thickness in pixels.
Any larger values inside attributes are automatically reduced to this value by the VT.";
CM_ BO_ 2565340926 "ECU to VT";
CM_ SG_ 2565340926 AuxModelIdentification "Model Identification Code of the Auxiliary Input Unit";
CM_ SG_ 2565340926 AuxInputEnable "Auxiliary Input Enable";
CM_ SG_ 2565340926 AuxErrorInvalidInputID "Invalid Auxiliary Input Object ID";
CM_ SG_ 2565340926 AuxErrorAnyOther "Any other error";
CM_ BO_ 2565537534 "Request PGN";
CM_ BO_ 2633895422 "Working Set Master";
CM_ BO_ 2566787070 "Language Command";
CM_ BO_ 2563309310 "Extended TP (Command)";
CM_ BO_ 2563243774 "Extended TP (Data)";
BA_DEF_  "ISO11783_12_SpecVersion" STRING ;
BA_DEF_ SG_  "SigType" ENUM  "Default","Range","RangeSigned","ASCII","Discrete","Control","ReferencePGN","DTC","StringDelimiter","StringLength","StringLengthControl";
BA_DEF_  "DatabaseVersion" STRING ;
BA_DEF_ BO_  "GenMsgRequestable" INT 0 1;
BA_DEF_ BO_  "GenMsgCycleTime" INT 0 3600000;
BA_DEF_ BO_  "GenMsgSendType" ENUM  "cyclic","reserved","cyclicIfActive","reserved","reserved","reserved","reserved","reserved","noMsgSendType","vector_leerstring";
BA_DEF_ BO_  "VFrameFormat" ENUM  "StandardCAN","ExtendedCAN","reserved","J1939PG","vector_leerstring";
BA_DEF_ BU_  "ECU" STRING ;
BA_DEF_ BU_  "NmJ1939IdentityNumber" INT 0 2097151;
BA_DEF_ BU_  "NmJ1939ManufacturerCode" INT 0 2047;
BA_DEF_ BU_  "NmJ1939ECUInstance" INT 0 7;
BA_DEF_ BU_  "NmJ1939FunctionInstance" INT 0 7;
BA_DEF_ BU_  "NmJ1939Function" INT 0 255;
BA_DEF_ BU_  "NmJ1939SystemInstance" INT 0 15;
BA_DEF_ BU_  "NmJ1939System" INT 0 127;
BA_DEF_ BU_  "NmJ1939IndustryGroup" INT 0 7;
BA_DEF_ BU_  "NmJ1939AAC" INT 0 1;
BA_DEF_ BU_  "NmStationAddress" INT 0 255;
BA_DEF_  "BusType" STRING ;
BA_DEF_  "ProtocolType" STRING ;
BA_DEF_ BU_  "NodeLayerModules" STRING ;
BA_DEF_ BO_  "SingleFrame" INT 0 1;
BA_DEF_ SG_  "DDI" INT 0 65535;
BA_DEF_  "ISO11783_6_SpecVersion" STRING ;
BA_DEF_  "ISO11783_7_SpecVersion" STRING ;
BA_DEF_  "ISO11783_11_SpecVersion" STRING ;
BA_DEF_DEF_  "ISO11783_12_SpecVersion" "";
BA_DEF_DEF_  "SigType" "Default";
BA_DEF_DEF_  "DatabaseVersion" "";
BA_DEF_DEF_  "GenMsgRequestable" 1;
BA_DEF_DEF_  "GenMsgCycleTime" 0;
BA_DEF_DEF_  "GenMsgSendType" "noMsgSendType";
BA_DEF_DEF_  "VFrameFormat" "J1939PG";
BA_DEF_DEF_  "ECU" "";
BA_DEF_DEF_  "NmJ1939IdentityNumber" 0;
BA_DEF_DEF_  "NmJ1939ManufacturerCode" 0;
BA_DEF_DEF_  "NmJ1939ECUInstance" 0;
BA_DEF_DEF_  "NmJ1939FunctionInstance" 0;
BA_DEF_DEF_  "NmJ1939Function" 0;
BA_DEF_DEF_  "NmJ1939SystemInstance" 0;
BA_DEF_DEF_  "NmJ1939System" 0;
BA_DEF_DEF_  "NmJ1939IndustryGroup" 0;
BA_DEF_DEF_  "NmJ1939AAC" 0;
BA_DEF_DEF_  "NmStationAddress" 254;
BA_DEF_DEF_  "BusType" "";
BA_DEF_DEF_  "ProtocolType" "";
BA_DEF_DEF_  "NodeLayerModules" "";
BA_DEF_DEF_  "SingleFrame" 1;
BA_DEF_DEF_  "DDI" 0;
BA_DEF_DEF_  "ISO11783_6_SpecVersion" "";
BA_DEF_DEF_  "ISO11783_7_SpecVersion" "";
BA_DEF_DEF_  "ISO11783_11_SpecVersion" "";
BA_ "ISO11783_12_SpecVersion" "2006-10-24 DIS";
BA_ "DatabaseVersion" "4.1";
BA_ "ProtocolType" "ISO11783";
BA_ "ISO11783_6_SpecVersion" "2007-02-26 DIS";
BA_ "ISO11783_7_SpecVersion" "2007-03-17 DIS";
BA_ "ISO11783_11_SpecVersion" "2007-01-15 DIS";
BA_ "BusType" "CAN";
BA_ "NmStationAddress" BU_ WSM 1;
BA_ "ECU" BU_ WSM "WSM";
BA_ "NmJ1939IdentityNumber" BU_ WSM 4568;
BA_ "NmJ1939ManufacturerCode" BU_ WSM 1861;
BA_ "NmJ1939Function" BU_ WSM 255;
BA_ "NmJ1939IndustryGroup" BU_ WSM 2;
BA_ "NmJ1939AAC" BU_ WSM 1;
BA_ "NodeLayerModules" BU_ WSM "ISO11783_IL.vmodule";
BA_ "NmStationAddress" BU_ VT 38;
BA_ "NmJ1939AAC" BU_ VT 1;
BA_ "NmJ1939IndustryGroup" BU_ VT 2;
BA_ "NmJ1939Function" BU_ VT 29;
BA_ "NmJ1939ManufacturerCode" BU_ VT 1861;
BA_ "GenMsgCycleTime" BO_ 2565340673 1000;
BA_ "GenMsgSendType" BO_ 2565340673 2;
BA_ "GenMsgCycleTime" BO_ 2632384254 100;
BA_ "GenMsgSendType" BO_ 2565340926 2;
BA_ "GenMsgCycleTime" BO_ 2565340926 1000;
BA_ "GenMsgCycleTime" BO_ 2566787070 100;
BA_ "DDI" SG_ 3221225472 AreaPerTimeCapacity 151;
BA_ "SigType" SG_ 3221225472 Valve5ValveState 4;
BA_ "SigType" SG_ 3221225472 Valve6LimitStatus 4;
BA_ "SigType" SG_ 3221225472 Valve6ExtendedPortEstimatedFlow 1;
BA_ "SigType" SG_ 3221225472 Valve6RetractPortEstimatedFlow 1;
BA_ "SigType" SG_ 3221225472 Valve6ValveState 4;
BA_ "SigType" SG_ 3221225472 Valve6FailSafeMode 4;
BA_ "SigType" SG_ 3221225472 Valve7LimitStatus 4;
BA_ "SigType" SG_ 3221225472 Valve7ExtendedPortEstimatedFlow 1;
BA_ "SigType" SG_ 3221225472 Valve7RetractPortEstimatedFlow 1;
BA_ "SigType" SG_ 3221225472 Valve7ValveState 4;
BA_ "SigType" SG_ 3221225472 Valve7FailSafeMode 4;
BA_ "SigType" SG_ 3221225472 Valve8LimitStatus 4;
BA_ "SigType" SG_ 3221225472 Valve8ExtendedPortEstimatedFlow 1;
BA_ "SigType" SG_ 3221225472 Valve8RetractPortEstimatedFlow 1;
BA_ "SigType" SG_ 3221225472 Valve8ValveState 4;
BA_ "SigType" SG_ 3221225472 Valve8FailSafeMode 4;
BA_ "SigType" SG_ 3221225472 Valve9LimitStatus 4;
BA_ "SigType" SG_ 3221225472 Valve9ExtendedPortEstimatedFlow 1;
BA_ "SigType" SG_ 3221225472 Valve9RetractPortEstimatedFlow 1;
BA_ "SigType" SG_ 3221225472 Valve9ValveState 4;
BA_ "SigType" SG_ 3221225472 Valve9FailSafeMode 4;
BA_ "SigType" SG_ 3221225472 Valve5ReturnPortPressure 1;
BA_ "SigType" SG_ 3221225472 Valve6ExtendedPortMeasuredFlow 1;
BA_ "SigType" SG_ 3221225472 Valve6RetractPortMeasuredFlow 1;
BA_ "SigType" SG_ 3221225472 Valve6ExtendedPortPressure 1;
BA_ "SigType" SG_ 3221225472 Valve6RetractPortPressure 1;
BA_ "SigType" SG_ 3221225472 Valve6ReturnPortPressure 1;
BA_ "SigType" SG_ 3221225472 Valve7ExtendedPortMeasuredFlow 1;
BA_ "SigType" SG_ 3221225472 Valve7RetractPortMeasuredFlow 1;
BA_ "SigType" SG_ 3221225472 Valve7ExtendedPortPressure 1;
BA_ "SigType" SG_ 3221225472 Valve7RetractPortPressure 1;
BA_ "SigType" SG_ 3221225472 Valve7ReturnPortPressure 1;
BA_ "SigType" SG_ 3221225472 Valve8ExtendedPortMeasuredFlow 1;
BA_ "SigType" SG_ 3221225472 Valve8RetractPortMeasuredFlow 1;
BA_ "SigType" SG_ 3221225472 Valve8ExtendedPortPressure 1;
BA_ "SigType" SG_ 3221225472 Valve8RetractPortPressure 1;
BA_ "SigType" SG_ 3221225472 Valve8ReturnPortPressure 1;
BA_ "SigType" SG_ 3221225472 Valve9ExtendedPortMeasuredFlow 1;
BA_ "SigType" SG_ 3221225472 Valve9RetractPortMeasuredFlow 1;
BA_ "SigType" SG_ 3221225472 Valve9ExtendedPortPressure 1;
BA_ "SigType" SG_ 3221225472 Valve9RetractPortPressure 1;
BA_ "SigType" SG_ 3221225472 Valve9ReturnPortPressure 1;
BA_ "SigType" SG_ 3221225472 Valve5StateCmd 4;
BA_ "SigType" SG_ 3221225472 Valve6PortFlowCmd 1;
BA_ "SigType" SG_ 3221225472 Valve6StateCmd 4;
BA_ "SigType" SG_ 3221225472 Valve6FailSaveModeCmd 4;
BA_ "SigType" SG_ 3221225472 Valve7PortFlowCmd 1;
BA_ "SigType" SG_ 3221225472 Valve7StateCmd 4;
BA_ "SigType" SG_ 3221225472 Valve7FailSaveModeCmd 4;
BA_ "SigType" SG_ 3221225472 Valve8PortFlowCmd 1;
BA_ "SigType" SG_ 3221225472 Valve8StateCmd 4;
BA_ "SigType" SG_ 3221225472 Valve8FailSaveModeCmd 4;
BA_ "SigType" SG_ 3221225472 Valve9PortFlowCmd 1;
BA_ "SigType" SG_ 3221225472 Valve9StateCmd 4;
BA_ "SigType" SG_ 3221225472 Valve9FailSaveModeCmd 4;
BA_ "SigType" SG_ 3221225472 ATTR_Archive 4;
BA_ "SigType" SG_ 3221225472 ATTR_Directory 4;
BA_ "SigType" SG_ 3221225472 ValveState 4;
BA_ "SigType" SG_ 3221225472 VTFunctionECUtoVT 1;
BA_ "SigType" SG_ 3221225472 KeyActivationCode 1;
BA_ "SigType" SG_ 3221225472 KeyObjectParentID 1;
BA_ "SigType" SG_ 3221225472 KeyObjectID 1;
BA_ "SigType" SG_ 3221225472 SoftKeyCode 1;
BA_ "SigType" SG_ 3221225472 ButtonActivationCode 1;
BA_ "SigType" SG_ 3221225472 ButtonObjectID 1;
BA_ "SigType" SG_ 3221225472 ButtonObjectParentID 1;
BA_ "SigType" SG_ 3221225472 ButtonKeyCode 1;
BA_ "SigType" SG_ 3221225472 XPosition 1;
BA_ "SigType" SG_ 3221225472 YPosition 1;
BA_ "SigType" SG_ 3221225472 VTSelectInputObjectID 1;
BA_ "SigType" SG_ 3221225472 VTSelectInputObjectStatus 1;
BA_ "SigType" SG_ 3221225472 VTEscObjectID 1;
BA_ "SigType" SG_ 3221225472 VTChangeNumericValueObjectID 1;
BA_ "SigType" SG_ 3221225472 VTChangeNumericValueValue 1;
BA_ "SigType" SG_ 3221225472 VTChangeActiveMaskObjectID 1;
BA_ "SigType" SG_ 3221225472 VTChangeSoftKeyMaskParentID 1;
BA_ "SigType" SG_ 3221225472 VTChangeSoftKeyMaskObjectID 1;
BA_ "SigType" SG_ 3221225472 ParentObjectID 1;
BA_ "SigType" SG_ 3221225472 ObjectToChangeStringValueID 1;
BA_ "SigType" SG_ 3221225472 ObjectPoolRecord 1;
BA_ "SigType" SG_ 3221225472 AuxiliaryFunctionObjectID 1;
BA_ "SigType" SG_ 3221225472 AssignmentErrorNotAccepted 4;
BA_ "SigType" SG_ 3221225472 IsEnabled 1;
BA_ "SigType" SG_ 3221225472 InputStatusObjectId 1;
BA_ "SigType" SG_ 3221225472 ObjectToShowHideID 1;
BA_ "SigType" SG_ 3221225472 ShowOrHide 1;
BA_ "SigType" SG_ 3221225472 ObjectoEnableDisbaleID 1;
BA_ "SigType" SG_ 3221225472 EnableOrDisable 1;
BA_ "SigType" SG_ 3221225472 SelectInputObjectID 1;
BA_ "SigType" SG_ 3221225472 NumberOfRepetitions_Audio 1;
BA_ "SigType" SG_ 3221225472 Frequency_Audio 1;
BA_ "SigType" SG_ 3221225472 OnTimeDuration_Audio 1;
BA_ "SigType" SG_ 3221225472 OffTimeDuration_Audio 1;
BA_ "SigType" SG_ 3221225472 AudioVolume 1;
BA_ "SigType" SG_ 3221225472 ObjectToMoveID 1;
BA_ "SigType" SG_ 3221225472 XPosChangeTopLeft 1;
BA_ "SigType" SG_ 3221225472 YPosChangeTopLeft 1;
BA_ "SigType" SG_ 3221225472 ObjectToSizeID 1;
BA_ "SigType" SG_ 3221225472 NewWidth 1;
BA_ "SigType" SG_ 3221225472 NewHeight 1;
BA_ "SigType" SG_ 3221225472 ObjectToChangeColourID 1;
BA_ "SigType" SG_ 3221225472 NewBackgroundColour 1;
BA_ "SigType" SG_ 3221225472 ObjectToChangeNumValueID 1;
BA_ "SigType" SG_ 3221225472 NewValue 1;
BA_ "SigType" SG_ 3221225472 ObjectToChangeEndPointID 1;
BA_ "SigType" SG_ 3221225472 Width 1;
BA_ "SigType" SG_ 3221225472 Height 1;
BA_ "SigType" SG_ 3221225472 LineDirection 1;
BA_ "SigType" SG_ 3221225472 ObjectToChangeFontID 1;
BA_ "SigType" SG_ 3221225472 FontColour 1;
BA_ "SigType" SG_ 3221225472 FontSize 1;
BA_ "SigType" SG_ 3221225472 FontType 1;
BA_ "SigType" SG_ 3221225472 FontStyle 1;
BA_ "SigType" SG_ 3221225472 ObjectToChangeLineAttributesID 1;
BA_ "SigType" SG_ 3221225472 LineColour 1;
BA_ "SigType" SG_ 3221225472 LineWidth 1;
BA_ "SigType" SG_ 3221225472 LineArt 1;
BA_ "SigType" SG_ 3221225472 ObjectToChangeFillAttributesID 1;
BA_ "SigType" SG_ 3221225472 FillType 1;
BA_ "SigType" SG_ 3221225472 FillColour 1;
BA_ "SigType" SG_ 3221225472 FillPatternObjectID 1;
BA_ "SigType" SG_ 3221225472 WorkingSetObjectID 1;
BA_ "SigType" SG_ 3221225472 NewActiveMaskObjectID 1;
BA_ "SigType" SG_ 3221225472 MaskType 1;
BA_ "SigType" SG_ 3221225472 DataOrAlarmMaskObjectID 1;
BA_ "SigType" SG_ 3221225472 NewSoftKeyMaskObjectID 1;
BA_ "SigType" SG_ 3221225472 ObjectToChangeAttributeID 1;
BA_ "SigType" SG_ 3221225472 AttributeID 1;
BA_ "SigType" SG_ 3221225472 NewAttributeValue 1;
BA_ "SigType" SG_ 3221225472 AlarmMaskObjectID 1;
BA_ "SigType" SG_ 3221225472 NewPriority 1;
BA_ "SigType" SG_ 3221225472 ListInputObjectID 1;
BA_ "SigType" SG_ 3221225472 ListIndex 1;
BA_ "SigType" SG_ 3221225472 NewObjectID 1;
BA_ "SigType" SG_ 3221225472 NewStringValue 9;
BA_ "SigType" SG_ 3221225472 MemoryRequired 1;
BA_ "SigType" SG_ 3221225472 VersionLabelToStore 3;
BA_ "SigType" SG_ 3221225472 VersionLabelToLoad 3;
BA_ "SigType" SG_ 3221225472 VersionLabelToDelete 3;
BA_ "SigType" SG_ 2565340673 VTFunctionECUtoVT 1;
BA_ "SigType" SG_ 2565340673 KeyActivationCode 1;
BA_ "SigType" SG_ 2565340673 KeyObjectParentID 1;
BA_ "SigType" SG_ 2565340673 KeyObjectID 1;
BA_ "SigType" SG_ 2565340673 SoftKeyCode 1;
BA_ "SigType" SG_ 2565340673 ButtonActivationCode 1;
BA_ "SigType" SG_ 2565340673 ButtonObjectID 1;
BA_ "SigType" SG_ 2565340673 ButtonObjectParentID 1;
BA_ "SigType" SG_ 2565340673 ButtonKeyCode 1;
BA_ "SigType" SG_ 2565340673 XPosition 1;
BA_ "SigType" SG_ 2565340673 YPosition 1;
BA_ "SigType" SG_ 2565340673 VTSelectInputObjectID 1;
BA_ "SigType" SG_ 2565340673 VTSelectInputObjectStatus 1;
BA_ "SigType" SG_ 2565340673 VTEscObjectID 1;
BA_ "SigType" SG_ 2565340673 VTChangeNumericValueObjectID 1;
BA_ "SigType" SG_ 2565340673 VTChangeNumericValueValue 1;
BA_ "SigType" SG_ 2565340673 VTChangeActiveMaskObjectID 1;
BA_ "SigType" SG_ 2565340673 VTChangeSoftKeyMaskParentID 1;
BA_ "SigType" SG_ 2565340673 VTChangeSoftKeyMaskObjectID 1;
BA_ "SigType" SG_ 2565340673 ParentObjectID 1;
BA_ "SigType" SG_ 2565340673 ObjectToChangeStringValueID_Resp 1;
BA_ "SigType" SG_ 2565340673 ObjectPoolRecord 1;
BA_ "SigType" SG_ 2565340673 AuxiliaryFunctionObjectID 1;
BA_ "SigType" SG_ 2565340673 AssignmentErrorNotAccepted 4;
BA_ "SigType" SG_ 2565340673 IsEnabled 1;
BA_ "SigType" SG_ 2565340673 InputStatusObjectId 1;
BA_ "SigType" SG_ 2565340673 ObjectToShowHideID 1;
BA_ "SigType" SG_ 2565340673 ShowOrHide 1;
BA_ "SigType" SG_ 2565340673 ObjectoEnableDisbaleID 1;
BA_ "SigType" SG_ 2565340673 EnableOrDisable 1;
BA_ "SigType" SG_ 2565340673 SelectInputObjectID 1;
BA_ "SigType" SG_ 2565340673 NumberOfRepetitions_Audio 1;
BA_ "SigType" SG_ 2565340673 Frequency_Audio 1;
BA_ "SigType" SG_ 2565340673 OnTimeDuration_Audio 1;
BA_ "SigType" SG_ 2565340673 OffTimeDuration_Audio 1;
BA_ "SigType" SG_ 2565340673 AudioVolume 1;
BA_ "SigType" SG_ 2565340673 ObjectToMoveID_Location 1;
BA_ "SigType" SG_ 2565340673 XPosChangeTopLeft 1;
BA_ "SigType" SG_ 2565340673 YPosChangeTopLeft 1;
BA_ "SigType" SG_ 2565340673 ObjectToSizeID 1;
BA_ "SigType" SG_ 2565340673 NewWidth 1;
BA_ "SigType" SG_ 2565340673 NewHeight 1;
BA_ "SigType" SG_ 2565340673 ObjectToChangeColourID 1;
BA_ "SigType" SG_ 2565340673 NewBackgroundColour 1;
BA_ "SigType" SG_ 2565340673 ObjectToChangeNumValueID 1;
BA_ "SigType" SG_ 2565340673 NewValue 1;
BA_ "SigType" SG_ 2565340673 ObjectToChangeEndPointID 1;
BA_ "SigType" SG_ 2565340673 Width 1;
BA_ "SigType" SG_ 2565340673 Height 1;
BA_ "SigType" SG_ 2565340673 LineDirection 1;
BA_ "SigType" SG_ 2565340673 ObjectToChangeFontID 1;
BA_ "SigType" SG_ 2565340673 FontColour 1;
BA_ "SigType" SG_ 2565340673 FontSize 1;
BA_ "SigType" SG_ 2565340673 FontType 1;
BA_ "SigType" SG_ 2565340673 FontStyle 1;
BA_ "SigType" SG_ 2565340673 ObjectToChangeLineAttributesID 1;
BA_ "SigType" SG_ 2565340673 LineColour 1;
BA_ "SigType" SG_ 2565340673 LineWidth 1;
BA_ "SigType" SG_ 2565340673 LineArt 1;
BA_ "SigType" SG_ 2565340673 ObjectToChangeFillAttributesID 1;
BA_ "SigType" SG_ 2565340673 FillType 1;
BA_ "SigType" SG_ 2565340673 FillColour 1;
BA_ "SigType" SG_ 2565340673 FillPatternObjectID 1;
BA_ "SigType" SG_ 2565340673 WorkingSetObjectID 1;
BA_ "SigType" SG_ 2565340673 NewActiveMaskObjectID 1;
BA_ "SigType" SG_ 2565340673 MaskType 1;
BA_ "SigType" SG_ 2565340673 DataOrAlarmMaskObjectID 1;
BA_ "SigType" SG_ 2565340673 NewSoftKeyMaskObjectID 1;
BA_ "SigType" SG_ 2565340673 ObjectToChangeAttributeID 1;
BA_ "SigType" SG_ 2565340673 AttributeID_Change 1;
BA_ "SigType" SG_ 2565340673 NewAttributeValue 1;
BA_ "SigType" SG_ 2565340673 AlarmMaskObjectID 1;
BA_ "SigType" SG_ 2565340673 NewPriority 1;
BA_ "SigType" SG_ 2565340673 ListInputObjectID 1;
BA_ "SigType" SG_ 2565340673 ListIndex 1;
BA_ "SigType" SG_ 2565340673 NewObjectID 1;
BA_ "SigType" SG_ 2565340673 NewStringValue 9;
BA_ "SigType" SG_ 2565340673 MemoryRequired 1;
BA_ "SigType" SG_ 2565340673 VersionLabelToStore 3;
BA_ "SigType" SG_ 2565340673 VersionLabelToLoad 3;
BA_ "SigType" SG_ 2565340673 VersionLabelToDelete 3;
BA_ "SigType" SG_ 2633895169 NumberOfMembersInWorkingSet 1;
BA_ "SigType" SG_ 2565799425 IndustryGroup 4;
BA_ "SigType" SG_ 2565799425 Function 1;
BA_ "SigType" SG_ 2565799425 FunctionInstance 1;
BA_ "SigType" SG_ 2565799425 ECUInstance 4;
BA_ "SigType" SG_ 2565799425 ManufacturerCode 1;
BA_ "SigType" SG_ 2565799425 IdentityNumber 1;
BA_ "SigType" SG_ 2565799678 IndustryGroup 4;
BA_ "SigType" SG_ 2565799678 Function 1;
BA_ "SigType" SG_ 2565799678 FunctionInstance 1;
BA_ "SigType" SG_ 2565799678 ECUInstance 4;
BA_ "SigType" SG_ 2565799678 ManufacturerCode 1;
BA_ "SigType" SG_ 2565799678 IdentityNumber 1;
BA_ "SigType" SG_ 2632384254 AttributeID 1;
BA_ "SigType" SG_ 2632384254 VTFunctionVTtoECU 1;
BA_ "SigType" SG_ 2632384254 KeyActivationCode 1;
BA_ "SigType" SG_ 2632384254 KeyObjectID 1;
BA_ "SigType" SG_ 2632384254 KeyObjectParentID 1;
BA_ "SigType" SG_ 2632384254 SoftKeyCode 1;
BA_ "SigType" SG_ 2632384254 ButtonActivationCode 1;
BA_ "SigType" SG_ 2632384254 ButtonObjectID 1;
BA_ "SigType" SG_ 2632384254 ButtonObjectParentID 1;
BA_ "SigType" SG_ 2632384254 ButtonKeyCode 1;
BA_ "SigType" SG_ 2632384254 XPosition 1;
BA_ "SigType" SG_ 2632384254 YPosition 1;
BA_ "SigType" SG_ 2632384254 VTSelectInputObjectID 1;
BA_ "SigType" SG_ 2632384254 VTSelectInputObjectStatus 1;
BA_ "SigType" SG_ 2632384254 VTSelectInputObjectIsEdited 1;
BA_ "SigType" SG_ 2632384254 VTEscObjectID 1;
BA_ "SigType" SG_ 2632384254 ErrorCodeVTEsc1 4;
BA_ "SigType" SG_ 2632384254 ErrorCodeVTEsc2 4;
BA_ "SigType" SG_ 2632384254 VTChangeNumericValueObjectID 1;
BA_ "SigType" SG_ 2632384254 VTChangeNumericValueValue 1;
BA_ "SigType" SG_ 2632384254 VTChangeActiveMaskObjectID 1;
BA_ "SigType" SG_ 2632384254 ErrorCodeMissingObjects 4;
BA_ "SigType" SG_ 2632384254 ErrorCodeMaskOrChildObjectError 4;
BA_ "SigType" SG_ 2632384254 ErrorCodeAnyOtherError 4;
BA_ "SigType" SG_ 2632384254 ErrorCodePoolDeleted 4;
BA_ "SigType" SG_ 2632384254 VTChangeActiveMaskErrorID 1;
BA_ "SigType" SG_ 2632384254 VTChangeActiveMaskParentID 1;
BA_ "SigType" SG_ 2632384254 VTChangeSoftKeyMaskParentID 1;
BA_ "SigType" SG_ 2632384254 VTChangeSoftKeyMaskObjectID 1;
BA_ "SigType" SG_ 2632384254 ErrorCodeVTChangeSoftKeyMask1 4;
BA_ "SigType" SG_ 2632384254 ErrorCodeVTChangeSoftKeyMask2 4;
BA_ "SigType" SG_ 2632384254 ErrorCodeVTChangeSoftKeyMask3 4;
BA_ "SigType" SG_ 2632384254 ErrorCodeVTChangeSoftKeyMask4 4;
BA_ "SigType" SG_ 2632384254 ErrorCodeVTChangeSoftKeyMask5 4;
BA_ "SigType" SG_ 2632384254 ObjectToChangeStringID 1;
BA_ "SigType" SG_ 2632384254 EnteredStringValue 9;
BA_ "SigType" SG_ 2632384254 ErrorCodeEndOfObjectPool1 4;
BA_ "SigType" SG_ 2632384254 ErrorCodeEndOfObjectPool2 4;
BA_ "SigType" SG_ 2632384254 ErrorCodeEndOfObjectPool3 4;
BA_ "SigType" SG_ 2632384254 ParentObjectIdOfFaultyObject 1;
BA_ "SigType" SG_ 2632384254 ObjectIdOfFaultyObject 1;
BA_ "SigType" SG_ 2632384254 ErrorCodeObjectPool1 4;
BA_ "SigType" SG_ 2632384254 ErrorCodeObjectPool2 4;
BA_ "SigType" SG_ 2632384254 ErrorCodeObjectPool3 4;
BA_ "SigType" SG_ 2632384254 ErrorCodeObjectPool4 4;
BA_ "SigType" SG_ 2632384254 IdentityNumber 1;
BA_ "SigType" SG_ 2632384254 ManufacturerCode 1;
BA_ "SigType" SG_ 2632384254 ECUInstance 4;
BA_ "SigType" SG_ 2632384254 FunctionInstance 1;
BA_ "SigType" SG_ 2632384254 AuxiliaryInputObjectID 1;
BA_ "SigType" SG_ 2632384254 InputObjectId 1;
BA_ "SigType" SG_ 2632384254 Value1 1;
BA_ "SigType" SG_ 2632384254 Function 1;
BA_ "SigType" SG_ 2632384254 DeviceClass 1;
BA_ "SigType" SG_ 2632384254 IndustryGroup 4;
BA_ "SigType" SG_ 2632384254 DeviceClassInstance 4;
BA_ "SigType" SG_ 2632384254 SelfConfigurableAddress 4;
BA_ "SigType" SG_ 2632384254 AuxiliaryFunctionObjectID 1;
BA_ "SigType" SG_ 2632384254 Value2 1;
BA_ "SigType" SG_ 2632384254 InputStatusObjectId 1;
BA_ "SigType" SG_ 2632384254 ObjectEscapeID 1;
BA_ "SigType" SG_ 2632384254 ErrorCodeEscapeObj1 4;
BA_ "SigType" SG_ 2632384254 ErrorCodeEscapeObj2 4;
BA_ "SigType" SG_ 2632384254 ObjectToHideShowID 1;
BA_ "SigType" SG_ 2632384254 ObjectShowStatus 1;
BA_ "SigType" SG_ 2632384254 ErrorCodeHideShowObj1 4;
BA_ "SigType" SG_ 2632384254 ErrorCodeHideShowObj2 4;
BA_ "SigType" SG_ 2632384254 ErrorCodeHideShowObj3 4;
BA_ "SigType" SG_ 2632384254 ObjectToEnableDisableID 1;
BA_ "SigType" SG_ 2632384254 ObjectEnableStatus 1;
BA_ "SigType" SG_ 2632384254 ErrorCodeEnableDisableObj1 4;
BA_ "SigType" SG_ 2632384254 ErrorCodeEnableDisableObj2 4;
BA_ "SigType" SG_ 2632384254 ErrorCodeEnableDisableObj3 4;
BA_ "SigType" SG_ 2632384254 ErrorCodeEnableDisableObj4 4;
BA_ "SigType" SG_ 2632384254 SelectInputObjectID 1;
BA_ "SigType" SG_ 2632384254 ObjectSelectStatus 1;
BA_ "SigType" SG_ 2632384254 ErrorCodeSelectObject1 4;
BA_ "SigType" SG_ 2632384254 ErrorCodeSelectObject2 4;
BA_ "SigType" SG_ 2632384254 ErrorCodeSelectObject3 4;
BA_ "SigType" SG_ 2632384254 ErrorCodeSelectObject4 4;
BA_ "SigType" SG_ 2632384254 ErrorCodeSelectObject5 4;
BA_ "SigType" SG_ 2632384254 ErrorCodeControlAudioDevice1 4;
BA_ "SigType" SG_ 2632384254 ErrorCodeControlAudioDevice2 4;
BA_ "SigType" SG_ 2632384254 ErrorCodeAudioVolume1 4;
BA_ "SigType" SG_ 2632384254 ErrorCodeAudioVolume2 4;
BA_ "SigType" SG_ 2632384254 ParentObjectID_ChildLoc 1;
BA_ "SigType" SG_ 2632384254 ObjectToMoveID_Location 1;
BA_ "SigType" SG_ 2632384254 ErrorCodeChangeChildLocation1 4;
BA_ "SigType" SG_ 2632384254 ErrorCodeChangeChildLocation2 4;
BA_ "SigType" SG_ 2632384254 ErrorCodeChangeChildLocation5 4;
BA_ "SigType" SG_ 2632384254 ObjectToSizeID 1;
BA_ "SigType" SG_ 2632384254 ErrorCodeObjToSize1 4;
BA_ "SigType" SG_ 2632384254 ErrorCodeObjToSize2 4;
BA_ "SigType" SG_ 2632384254 ErrorCodeObjToSize3 4;
BA_ "SigType" SG_ 2632384254 ErrorCodeObjToSize4 4;
BA_ "SigType" SG_ 2632384254 ObjectToChangeColourID 1;
BA_ "SigType" SG_ 2632384254 NewBackgroundColour 1;
BA_ "SigType" SG_ 2632384254 ErrorCodeChangeColour1 4;
BA_ "SigType" SG_ 2632384254 ErrorCodeChangeColour2 4;
BA_ "SigType" SG_ 2632384254 ErrorCodeChangeColour3 4;
BA_ "SigType" SG_ 2632384254 ObjectToChangeNumValueID 1;
BA_ "SigType" SG_ 2632384254 ErrorCodeChangeNumValue1 4;
BA_ "SigType" SG_ 2632384254 ErrorCodeChangeNumValue2 4;
BA_ "SigType" SG_ 2632384254 ErrorCodeChangeNumValue3 4;
BA_ "SigType" SG_ 2632384254 ValueOfTheObject 1;
BA_ "SigType" SG_ 2632384254 ObjectToChangeEndPointID 1;
BA_ "SigType" SG_ 2632384254 ErrorCodeChangeEditPoint1 4;
BA_ "SigType" SG_ 2632384254 ErrorCodeChangeEditPoint2 4;
BA_ "SigType" SG_ 2632384254 ErrorCodeChangeEditPoint3 4;
BA_ "SigType" SG_ 2632384254 ObjectToChangeFontID 1;
BA_ "SigType" SG_ 2632384254 ErrorCodeChangeFont1 4;
BA_ "SigType" SG_ 2632384254 ErrorCodeChangeFont2 4;
BA_ "SigType" SG_ 2632384254 ErrorCodeChangeFont4 4;
BA_ "SigType" SG_ 2632384254 ErrorCodeChangeFont3 4;
BA_ "SigType" SG_ 2632384254 ErrorCodeChangeFont5 4;
BA_ "SigType" SG_ 2632384254 ErrorCodeChangeFont6 4;
BA_ "SigType" SG_ 2632384254 ObjectToChangeLineAttributeID 1;
BA_ "SigType" SG_ 2632384254 ErrorCodeChangeLineAttribute1 4;
BA_ "SigType" SG_ 2632384254 ErrorCodeChangeLineAttribute2 4;
BA_ "SigType" SG_ 2632384254 ErrorCodeChangeLineAttribute3 4;
BA_ "SigType" SG_ 2632384254 ErrorCodeChangeLineAttribute4 4;
BA_ "SigType" SG_ 2632384254 ObjectToChangeFillAttributesID 1;
BA_ "SigType" SG_ 2632384254 ErrorCodeChangeFillAttributes1 4;
BA_ "SigType" SG_ 2632384254 ErrorCodeChangeFillAttributes2 4;
BA_ "SigType" SG_ 2632384254 ErrorCodeChangeFillAttributes3 4;
BA_ "SigType" SG_ 2632384254 ErrorCodeChangeFillAttributes4 4;
BA_ "SigType" SG_ 2632384254 ErrorCodeChangeFillAttributes5 4;
BA_ "SigType" SG_ 2632384254 ActiveMaskObjectID 1;
BA_ "SigType" SG_ 2632384254 ErrorCodeChangeActiveMask1 4;
BA_ "SigType" SG_ 2632384254 ErrorCodeChangeActiveMask2 4;
BA_ "SigType" SG_ 2632384254 ErrorCodeChangeActiveMask3 4;
BA_ "SigType" SG_ 2632384254 ErrorCodeChangeActiveMask4 4;
BA_ "SigType" SG_ 2632384254 ErrorCodeChangeActiveMask5 4;
BA_ "SigType" SG_ 2632384254 DataOrAlarmMaskObjectID 1;
BA_ "SigType" SG_ 2632384254 SoftKeyMaskObjectID 1;
BA_ "SigType" SG_ 2632384254 ErrorCodeChangeSoftKeyMask1 4;
BA_ "SigType" SG_ 2632384254 ErrorCodeChangeSoftKeyMask2 4;
BA_ "SigType" SG_ 2632384254 ErrorCodeChangeSoftKeyMask3 4;
BA_ "SigType" SG_ 2632384254 ErrorCodeChangeSoftKeyMask4 4;
BA_ "SigType" SG_ 2632384254 ErrorCodeChangeSoftKeyMask5 4;
BA_ "SigType" SG_ 2632384254 ObjectToChangeAttributeID 1;
BA_ "SigType" SG_ 2632384254 ErrorCodeChangeAttribute1 4;
BA_ "SigType" SG_ 2632384254 ErrorCodeChangeAttribute2 4;
BA_ "SigType" SG_ 2632384254 ErrorCodeChangeAttribute3 4;
BA_ "SigType" SG_ 2632384254 ErrorCodeChangeAttribute4 4;
BA_ "SigType" SG_ 2632384254 AlarmMaskObjectID 1;
BA_ "SigType" SG_ 2632384254 NewPriority 1;
BA_ "SigType" SG_ 2632384254 ErrorCodeChangePriority1 4;
BA_ "SigType" SG_ 2632384254 ErrorCodeChangePriority2 4;
BA_ "SigType" SG_ 2632384254 ErrorCodeChangePriority3 4;
BA_ "SigType" SG_ 2632384254 ListInputObjectID 1;
BA_ "SigType" SG_ 2632384254 ListIndex 1;
BA_ "SigType" SG_ 2632384254 NewObjectID 1;
BA_ "SigType" SG_ 2632384254 ErrorCodeChangeListItem1 4;
BA_ "SigType" SG_ 2632384254 ErrorCodeChangeListItem2 4;
BA_ "SigType" SG_ 2632384254 ErrorCodeChangeListItem3 4;
BA_ "SigType" SG_ 2632384254 ErrorCodeChangeListItem4 4;
BA_ "SigType" SG_ 2632384254 ErrorCodeDeleteObjectPool1 4;
BA_ "SigType" SG_ 2632384254 ErrorCodeDeleteObjectPool2 4;
BA_ "SigType" SG_ 2632384254 ObjectToChangeStringValueID 1;
BA_ "SigType" SG_ 2632384254 ErrorCodeChangeStrObjectID 4;
BA_ "SigType" SG_ 2632384254 ErrorCodeChangeStrTooLong 4;
BA_ "SigType" SG_ 2632384254 ErrorCodeChangeStrError 4;
BA_ "SigType" SG_ 2632384254 ErrorCodeChangePosInvalidParent 4;
BA_ "SigType" SG_ 2632384254 ErrorCodeChangePosInvalidObject 4;
BA_ "SigType" SG_ 2632384254 ErrorCodeChangePosInvalidError 4;
BA_ "SigType" SG_ 2632384254 VersionNumberISO11783Part6 1;
BA_ "SigType" SG_ 2632384254 MemoryStatus 1;
BA_ "SigType" SG_ 2632384254 XDotsForSoftKeyDescriptor 1;
BA_ "SigType" SG_ 2632384254 YDotsForSoftKeyDescriptor 1;
BA_ "SigType" SG_ 2632384254 NumberOfPossibleVirtualSoftKeys 1;
BA_ "SigType" SG_ 2632384254 NumberOfPhysicalSoftKeys 1;
BA_ "SigType" SG_ 2632384254 FontSize_8x8 4;
BA_ "SigType" SG_ 2632384254 FontSize_8x12 4;
BA_ "SigType" SG_ 2632384254 FontSize_12x16 4;
BA_ "SigType" SG_ 2632384254 FontSize_16x16 4;
BA_ "SigType" SG_ 2632384254 FontSize_16x24 4;
BA_ "SigType" SG_ 2632384254 FontSize_24x32 4;
BA_ "SigType" SG_ 2632384254 FontSize_32x32 4;
BA_ "SigType" SG_ 2632384254 FontSize_32x48 4;
BA_ "SigType" SG_ 2632384254 FontSize_48x64 4;
BA_ "SigType" SG_ 2632384254 FontSize_64x64 4;
BA_ "SigType" SG_ 2632384254 FontSize_64x96 4;
BA_ "SigType" SG_ 2632384254 FontSize_96x128 4;
BA_ "SigType" SG_ 2632384254 FontSize_128x128 4;
BA_ "SigType" SG_ 2632384254 FontSize_128x192 4;
BA_ "SigType" SG_ 2632384254 FontType_BoldText 4;
BA_ "SigType" SG_ 2632384254 FontType_CrossedOutText 4;
BA_ "SigType" SG_ 2632384254 FontType_UnderlinedText 4;
BA_ "SigType" SG_ 2632384254 FontType_ItalicsText 4;
BA_ "SigType" SG_ 2632384254 FontType_InvertedText 4;
BA_ "SigType" SG_ 2632384254 FontType_FlashInverted 4;
BA_ "SigType" SG_ 2632384254 FontType_FlashHidden 4;
BA_ "SigType" SG_ 2632384254 FontType_ProportionalFont 4;
BA_ "SigType" SG_ 2632384254 MaxLineWidth 1;
BA_ "SigType" SG_ 2632384254 LineArts 1;
BA_ "SigType" SG_ 2632384254 FillTypes 1;
BA_ "SigType" SG_ 2632384254 ShapeFillTypes 1;
BA_ "SigType" SG_ 2632384254 SupportedGrapicMode 1;
BA_ "SigType" SG_ 2632384254 Hardware1 4;
BA_ "SigType" SG_ 2632384254 Hardware2 4;
BA_ "SigType" SG_ 2632384254 Hardware3 4;
BA_ "SigType" SG_ 2632384254 Hardware4 4;
BA_ "SigType" SG_ 2632384254 NrOfXPixelsInDataAreaMask 1;
BA_ "SigType" SG_ 2632384254 NrOfYPixelsInDataAreaMask 1;
BA_ "SigType" SG_ 2632384254 AcknowledgmentStoreVersion 4;
BA_ "SigType" SG_ 2632384254 AcknowledgmentLoadVersion 4;
BA_ "SigType" SG_ 2632384254 AcknowledgmentDeleteVersion 4;
BA_ "SigType" SG_ 2632384254 NrOfVersionStrings 1;
BA_ "SigType" SG_ 2632384254 VersionLables 3;
BA_ "SigType" SG_ 2632384254 ObjectIDOfFaultyObject 1;
BA_ "SigType" SG_ 2632384254 ErrorCodeVtObjPoolError1 4;
BA_ "SigType" SG_ 2632384254 ErrorCodeVtObjPoolError2 4;
BA_ "SigType" SG_ 2632384254 ErrorCodeVtObjPoolError3 4;
BA_ "SigType" SG_ 2632384254 ErrorCodeVtObjPoolError4 4;
BA_ "SigType" SG_ 2632384254 SourceAdressOfActiveWSM 1;
BA_ "SigType" SG_ 2632384254 VisibleDataOrAlarmMaskObjectID 1;
BA_ "SigType" SG_ 2632384254 VisibleSoftKeyMaskObjectID 1;
BA_ "SigType" SG_ 2632384254 VTBusyCode1 4;
BA_ "SigType" SG_ 2632384254 VTBusyCode2 4;
BA_ "SigType" SG_ 2632384254 VTBusyCode3 4;
BA_ "SigType" SG_ 2632384254 VTBusyCode4 4;
BA_ "SigType" SG_ 2632384254 VTBusyCode5 4;
BA_ "SigType" SG_ 2632384254 VTBusyCode8 4;
BA_ "SigType" SG_ 2632384254 VTFunctionCode 1;
BA_ "SigType" SG_ 2565340926 VTFunctionECUtoVT 1;
BA_ "SigType" SG_ 2565340926 KeyActivationCode 1;
BA_ "SigType" SG_ 2565340926 KeyObjectParentID 1;
BA_ "SigType" SG_ 2565340926 KeyObjectID 1;
BA_ "SigType" SG_ 2565340926 SoftKeyCode 1;
BA_ "SigType" SG_ 2565340926 ButtonActivationCode 1;
BA_ "SigType" SG_ 2565340926 ButtonObjectID 1;
BA_ "SigType" SG_ 2565340926 ButtonObjectParentID 1;
BA_ "SigType" SG_ 2565340926 ButtonKeyCode 1;
BA_ "SigType" SG_ 2565340926 XPosition 1;
BA_ "SigType" SG_ 2565340926 YPosition 1;
BA_ "SigType" SG_ 2565340926 VTSelectInputObjectID 1;
BA_ "SigType" SG_ 2565340926 VTSelectInputObjectStatus 1;
BA_ "SigType" SG_ 2565340926 VTEscObjectID 1;
BA_ "SigType" SG_ 2565340926 VTChangeNumericValueObjectID 1;
BA_ "SigType" SG_ 2565340926 VTChangeNumericValueValue 1;
BA_ "SigType" SG_ 2565340926 VTChangeActiveMaskObjectID 1;
BA_ "SigType" SG_ 2565340926 VTChangeSoftKeyMaskParentID 1;
BA_ "SigType" SG_ 2565340926 VTChangeSoftKeyMaskObjectID 1;
BA_ "SigType" SG_ 2565340926 ParentObjectID 1;
BA_ "SigType" SG_ 2565340926 ObjectToChangeStringValueID_Resp 1;
BA_ "SigType" SG_ 2565340926 ObjectPoolRecord 1;
BA_ "SigType" SG_ 2565340926 AuxiliaryFunctionObjectID 1;
BA_ "SigType" SG_ 2565340926 AssignmentErrorNotAccepted 4;
BA_ "SigType" SG_ 2565340926 IsEnabled 1;
BA_ "SigType" SG_ 2565340926 InputStatusObjectId 1;
BA_ "SigType" SG_ 2565340926 ObjectToShowHideID 1;
BA_ "SigType" SG_ 2565340926 ShowOrHide 1;
BA_ "SigType" SG_ 2565340926 ObjectoEnableDisbaleID 1;
BA_ "SigType" SG_ 2565340926 EnableOrDisable 1;
BA_ "SigType" SG_ 2565340926 SelectInputObjectID 1;
BA_ "SigType" SG_ 2565340926 NumberOfRepetitions_Audio 1;
BA_ "SigType" SG_ 2565340926 Frequency_Audio 1;
BA_ "SigType" SG_ 2565340926 OnTimeDuration_Audio 1;
BA_ "SigType" SG_ 2565340926 OffTimeDuration_Audio 1;
BA_ "SigType" SG_ 2565340926 AudioVolume 1;
BA_ "SigType" SG_ 2565340926 ObjectToMoveID_Location 1;
BA_ "SigType" SG_ 2565340926 XPosChangeTopLeft 1;
BA_ "SigType" SG_ 2565340926 YPosChangeTopLeft 1;
BA_ "SigType" SG_ 2565340926 ObjectToSizeID 1;
BA_ "SigType" SG_ 2565340926 NewWidth 1;
BA_ "SigType" SG_ 2565340926 NewHeight 1;
BA_ "SigType" SG_ 2565340926 ObjectToChangeColourID 1;
BA_ "SigType" SG_ 2565340926 NewBackgroundColour 1;
BA_ "SigType" SG_ 2565340926 ObjectToChangeNumValueID 1;
BA_ "SigType" SG_ 2565340926 NewValue 1;
BA_ "SigType" SG_ 2565340926 ObjectToChangeEndPointID 1;
BA_ "SigType" SG_ 2565340926 Width 1;
BA_ "SigType" SG_ 2565340926 Height 1;
BA_ "SigType" SG_ 2565340926 LineDirection 1;
BA_ "SigType" SG_ 2565340926 ObjectToChangeFontID 1;
BA_ "SigType" SG_ 2565340926 FontColour 1;
BA_ "SigType" SG_ 2565340926 FontSize 1;
BA_ "SigType" SG_ 2565340926 FontType 1;
BA_ "SigType" SG_ 2565340926 FontStyle 1;
BA_ "SigType" SG_ 2565340926 ObjectToChangeLineAttributesID 1;
BA_ "SigType" SG_ 2565340926 LineColour 1;
BA_ "SigType" SG_ 2565340926 LineWidth 1;
BA_ "SigType" SG_ 2565340926 LineArt 1;
BA_ "SigType" SG_ 2565340926 ObjectToChangeFillAttributesID 1;
BA_ "SigType" SG_ 2565340926 FillType 1;
BA_ "SigType" SG_ 2565340926 FillColour 1;
BA_ "SigType" SG_ 2565340926 FillPatternObjectID 1;
BA_ "SigType" SG_ 2565340926 WorkingSetObjectID 1;
BA_ "SigType" SG_ 2565340926 NewActiveMaskObjectID 1;
BA_ "SigType" SG_ 2565340926 MaskType 1;
BA_ "SigType" SG_ 2565340926 DataOrAlarmMaskObjectID 1;
BA_ "SigType" SG_ 2565340926 NewSoftKeyMaskObjectID 1;
BA_ "SigType" SG_ 2565340926 ObjectToChangeAttributeID 1;
BA_ "SigType" SG_ 2565340926 AttributeID_Change 1;
BA_ "SigType" SG_ 2565340926 NewAttributeValue 1;
BA_ "SigType" SG_ 2565340926 AlarmMaskObjectID 1;
BA_ "SigType" SG_ 2565340926 NewPriority 1;
BA_ "SigType" SG_ 2565340926 ListInputObjectID 1;
BA_ "SigType" SG_ 2565340926 ListIndex 1;
BA_ "SigType" SG_ 2565340926 NewObjectID 1;
BA_ "SigType" SG_ 2565340926 NewStringValue 9;
BA_ "SigType" SG_ 2565340926 MemoryRequired 1;
BA_ "SigType" SG_ 2565340926 VersionLabelToStore 3;
BA_ "SigType" SG_ 2565340926 VersionLabelToLoad 3;
BA_ "SigType" SG_ 2565340926 VersionLabelToDelete 3;
BA_ "SigType" SG_ 2565537534 RqstedPGN 1;
BA_ "SigType" SG_ 2633895422 NumberOfMembersInWorkingSet 1;
BA_ "SigType" SG_ 2566787070 LanguageCodeCmd 3;
BA_ "SigType" SG_ 2566787070 TimeFormatCmd 4;
BA_ "SigType" SG_ 2566787070 DecimalSymbolCmd 4;
BA_ "SigType" SG_ 2566787070 DateFormatCmd 1;
BA_ "SigType" SG_ 2566787070 MassUnitCmd 4;
BA_ "SigType" SG_ 2566787070 VolumeUnitCmd 4;
BA_ "SigType" SG_ 2566787070 AreaUnitCmd 4;
BA_ "SigType" SG_ 2566787070 DistanceUnitCmd 4;
BA_ "SigType" SG_ 2566787070 UnitsSystem 4;
BA_ "SigType" SG_ 2566787070 ForceUnits 4;
BA_ "SigType" SG_ 2566787070 PressureUnits 4;
BA_ "SigType" SG_ 2566787070 TemperatureUnits 4;
BA_ "SigType" SG_ 2563309310 ControlByte 1;
BA_ "SigType" SG_ 2563309310 ERtsMsgSize 1;
BA_ "SigType" SG_ 2563309310 ECtsNoPackets 1;
BA_ "SigType" SG_ 2563309310 EDpoNoPackets 1;
BA_ "SigType" SG_ 2563309310 EAckMsgSize 1;
BA_ "SigType" SG_ 2563309310 ECtsNextPacket 1;
BA_ "SigType" SG_ 2563309310 EDpoOffset 1;
BA_ "SigType" SG_ 2563309310 PGNumber 1;
BA_ "SigType" SG_ 2563243774 SeqNumber 1;
BA_ "SigType" SG_ 2563243774 Byte1 1;
BA_ "SigType" SG_ 2563243774 Byte2 1;
BA_ "SigType" SG_ 2563243774 Byte3 1;
BA_ "SigType" SG_ 2563243774 Byte4 1;
BA_ "SigType" SG_ 2563243774 Byte5 1;
BA_ "SigType" SG_ 2563243774 Byte6 1;
BA_ "SigType" SG_ 2563243774 Byte7 1;
VAL_ 3221225472 VehicleSystem 0 "Non-specific System" 127 "Not Available" ;
VAL_ 3221225472 VehicleSystem5 127 "Not Available" 0 "Ind. Process Control Stationary" ;
VAL_ 3221225472 VehicleSystem4 100 "Deck/Cargo/Fishing equip. sys" 90 "Environmental (HVAC) Systems" 80 "Instrumentation/General Systems" 70 "Communications Systems" 60 "Navigation Systems" 50 "Propulsion Systems" 40 "Steering Systems" 30 "Power Mgmt and lighting systems" 25 "Gateway" 20 "Safety Systems" 10 "System Tools" 127 "Not Available" 0 "Non-specific System" ;
VAL_ 3221225472 VehicleSystem3 8 "Grader" 7 "Four Wheel Drive Loader" 6 "Forklift" 5 "Excavator" 4 "Crawler" 3 "Backhoe" 2 "Articulated Dump Truck" 1 "Skid Steer Loader" 127 "Not Available" 0 "Non-specific System" ;
VAL_ 3221225472 VehicleSystem2 16 "Skidder" 15 "Earth Work" 14 "Special Crops" 13 "Powered Auxiliary Device" 12 "Farm Yard Operations" 11 "Transport/Trailer" 10 "Irrigation" 9 "Forage" 8 "Root Harvesters" 7 "Harvesters" 6 "Sprayers" 5 "Fertilizers" 4 "Planters/Seeders" 3 "Secondary Tillage" 2 "Tillage" 1 "Tractor" 127 "Not Available" 0 "Non-specific System" ;
VAL_ 3221225472 VehicleSystem1 2 "Trailer" 1 "Tractor" 127 "Not Available" 0 "Non-specific System" ;
VAL_ 3221225472 Valve5ValveState 0 "Blocked" 1 "Extend" 2 "Retract" 3 "Floating" 14 "ErrorIndication" 15 "DoNotCare" ;
VAL_ 3221225472 Valve6LimitStatus 7 "Not available" 6 "Non-recoverable Fault" 5 "Reserver" 4 "Reserved" 3 "Limited Low" 2 "Limited High" 1 "Operator Limited" 0 "Not limited" ;
VAL_ 3221225472 Valve6ValveState 0 "Blocked" 1 "Extend" 2 "Retract" 3 "Floating" 14 "ErrorIndication" 15 "DoNotCare" ;
VAL_ 3221225472 Valve6FailSafeMode 0 "Block" 1 "Float" 2 "ErrorIndication" 3 "NotAvailable" ;
VAL_ 3221225472 Valve7LimitStatus 7 "Not available" 6 "Non-recoverable Fault" 5 "Reserver" 4 "Reserved" 3 "Limited Low" 2 "Limited High" 1 "Operator Limited" 0 "Not limited" ;
VAL_ 3221225472 Valve7ValveState 0 "Blocked" 1 "Extend" 2 "Retract" 3 "Floating" 14 "ErrorIndication" 15 "DoNotCare" ;
VAL_ 3221225472 Valve7FailSafeMode 0 "Block" 1 "Float" 2 "ErrorIndication" 3 "NotAvailable" ;
VAL_ 3221225472 Valve8LimitStatus 7 "Not available" 6 "Non-recoverable Fault" 5 "Reserver" 4 "Reserved" 3 "Limited Low" 2 "Limited High" 1 "Operator Limited" 0 "Not limited" ;
VAL_ 3221225472 Valve8ValveState 0 "Blocked" 1 "Extend" 2 "Retract" 3 "Floating" 14 "ErrorIndication" 15 "DoNotCare" ;
VAL_ 3221225472 Valve8FailSafeMode 0 "Block" 1 "Float" 2 "ErrorIndication" 3 "NotAvailable" ;
VAL_ 3221225472 Valve9LimitStatus 7 "Not available" 6 "Non-recoverable Fault" 5 "Reserver" 4 "Reserved" 3 "Limited Low" 2 "Limited High" 1 "Operator Limited" 0 "Not limited" ;
VAL_ 3221225472 Valve9ValveState 0 "Blocked" 1 "Extend" 2 "Retract" 3 "Floating" 14 "ErrorIndication" 15 "DoNotCare" ;
VAL_ 3221225472 Valve9FailSafeMode 0 "Block" 1 "Float" 2 "ErrorIndication" 3 "NotAvailable" ;
VAL_ 3221225472 Valve5StateCmd 0 "Block" 1 "Extend" 2 "Retract" 3 "Float" 15 "Reserved" ;
VAL_ 3221225472 Valve6StateCmd 0 "Block" 1 "Extend" 2 "Retract" 3 "Float" 15 "Reserved" ;
VAL_ 3221225472 Valve6FailSaveModeCmd 0 "Block" 1 "Float" 3 "DoNotCare" ;
VAL_ 3221225472 Valve7StateCmd 0 "Block" 1 "Extend" 2 "Retract" 3 "Float" 15 "Reserved" ;
VAL_ 3221225472 Valve7FailSaveModeCmd 0 "Block" 1 "Float" 3 "DoNotCare" ;
VAL_ 3221225472 Valve8StateCmd 0 "Block" 1 "Extend" 2 "Retract" 3 "Float" 15 "Reserved" ;
VAL_ 3221225472 Valve8FailSaveModeCmd 0 "Block" 1 "Float" 3 "DoNotCare" ;
VAL_ 3221225472 Valve9StateCmd 0 "Block" 1 "Extend" 2 "Retract" 3 "Float" 15 "Reserved" ;
VAL_ 3221225472 Valve9FailSaveModeCmd 0 "Block" 1 "Float" 3 "DoNotCare" ;
VAL_ 3221225472 ATTR_Archive 1 "‘archive’ attribute is set" 0 "‘archive’ attribute is not set" ;
VAL_ 3221225472 ATTR_Directory 1 "handle specifies a directory" 0 "handle does not specify a dir" ;
VAL_ 3221225472 ValveState 0 "Blocked" 1 "Extend" 2 "Retract" 3 "Floating" 14 "ErrorIndication" 15 "DoNotCare" ;
VAL_ 3221225472 VTFunctionECUtoVT 193 "GetSupported WideChars" 37 "AuxiliaryInputStatusEnableCommandResponse" 35 "AuxiliaryInputMaintenance" 190 "ExecuteMacro" 189 "LockUnlockMask" 34 "AuxiliaryPreferredAssignment" 9 "DisplayActivationResponse" 186 "SelectColourMap" 185 "GetAttribute" 184 "GraphicsContextCommand" 183 "ChangePolygonScale" 182 "ChangePolygonPoint" 181 "SetObjectLabel" 0 "SoftKeyActivationResponse" 1 "ButtonActivationResponse" 2 "PointingEventResponse" 18 "EndOfObjectPool" 32 "AuxiliaryAssignmentResponse" 146 "ESC" 160 "ShowHideObject" 161 "EnableDisableObject" 162 "SelectInputObject" 163 "ControlAudioDevice" 164 "SetAudioVolume" 165 "ChangeChildLocation" 166 "ChangeSize" 167 "ChangeBackgroundColour" 168 "ChangeNumericValue" 169 "ChangeEndPoint" 170 "ChangeFontAttributes" 171 "ChangeLineAttributes" 172 "ChangeFillAttributes" 173 "ChangeActiveMask" 174 "ChangeSoftKeyMask" 175 "ChangeAttribute" 176 "ChangePriority" 177 "ChangeListItem" 178 "DeleteObjectPool" 192 "GetMemory" 194 "GetNumberOfSoftKeys" 195 "GetTextFontData" 199 "GetHardware" 208 "StoreVersion" 209 "LoadVersion" 210 "DeleteVersion" 223 "GetVersions" 255 "WorkingSetMaintenance" 179 "ChangeStringValue" 3 "VTSelectInputObjectResponse" 4 "VTESCResponse" 5 "VTChangeNumericValueResponse" 6 "VTChangeActiveMaskResponse" 7 "VTChangeSoftKeyMaskResponse" 196 "GetFillAndLineData" 17 "ObjectPoolTransfer" 180 "ChangeChildPosition" 8 "InputStringValueResponse" ;
VAL_ 3221225472 KeyActivationCode 3 "KeyPressAborted" 0 "KeyHasBeenReleased" 1 "KeyHasBeenPressed" 2 "KeyIsStillHeld" ;
VAL_ 3221225472 KeyObjectParentID 0 "KeyHasBeenReleased" 1 "KeyHasBeenPressed" 2 "KeyIsStillHeld" ;
VAL_ 3221225472 KeyObjectID 0 "KeyHasBeenReleased" 1 "KeyHasBeenPressed" 2 "KeyIsStillHeld" ;
VAL_ 3221225472 ButtonActivationCode 3 "ButtonPressAborted" 0 "ButtonHasBeenUnlatched" 1 "ButtonHasBeenLatched" 2 "ButtonsStillHeld" ;
VAL_ 3221225472 AssignmentErrorNotAccepted 0 "AssignmentAccepted" 1 "Rejected_InputAlreadyAssigned" ;
VAL_ 3221225472 IsEnabled 0 "Disabled" 1 "Enabled" 255 "InputTypeIsAnalog" ;
VAL_ 3221225472 ShowOrHide 0 "Hide" 1 "Show" ;
VAL_ 3221225472 EnableOrDisable 0 "Disable" 1 "Enable" ;
VAL_ 3221225472 MaskType 1 "Data" 2 "Alarm" ;
VAL_ 2565340673 VTFunctionECUtoVT 193 "GetSupported WideChars" 37 "AuxiliaryInputStatusEnableCommandResponse" 35 "AuxiliaryInputMaintenance" 190 "ExecuteMacro" 189 "LockUnlockMask" 34 "AuxiliaryPreferredAssignment" 9 "DisplayActivationResponse" 186 "SelectColourMap" 185 "GetAttribute" 184 "GraphicsContextCommand" 183 "ChangePolygonScale" 182 "ChangePolygonPoint" 181 "SetObjectLabel" 0 "SoftKeyActivationResponse" 1 "ButtonActivationResponse" 2 "PointingEventResponse" 18 "EndOfObjectPool" 32 "AuxiliaryAssignmentResponse" 146 "ESC" 160 "ShowHideObject" 161 "EnableDisableObject" 162 "SelectInputObject" 163 "ControlAudioDevice" 164 "SetAudioVolume" 165 "ChangeChildLocation" 166 "ChangeSize" 167 "ChangeBackgroundColour" 168 "ChangeNumericValue" 169 "ChangeEndPoint" 170 "ChangeFontAttributes" 171 "ChangeLineAttributes" 172 "ChangeFillAttributes" 173 "ChangeActiveMask" 174 "ChangeSoftKeyMask" 175 "ChangeAttribute" 176 "ChangePriority" 177 "ChangeListItem" 178 "DeleteObjectPool" 192 "GetMemory" 194 "GetNumberOfSoftKeys" 195 "GetTextFontData" 199 "GetHardware" 208 "StoreVersion" 209 "LoadVersion" 210 "DeleteVersion" 223 "GetVersions" 255 "WorkingSetMaintenance" 179 "ChangeStringValue" 3 "VTSelectInputObjectResponse" 4 "VTESCResponse" 5 "VTChangeNumericValueResponse" 6 "VTChangeActiveMaskResponse" 7 "VTChangeSoftKeyMaskResponse" 196 "GetFillAndLineData" 17 "ObjectPoolTransfer" 180 "ChangeChildPosition" 8 "InputStringValueResponse" ;
VAL_ 2565340673 KeyActivationCode 3 "KeyPressAborted" 0 "KeyHasBeenReleased" 1 "KeyHasBeenPressed" 2 "KeyIsStillHeld" ;
VAL_ 2565340673 KeyObjectParentID 0 "KeyHasBeenReleased" 1 "KeyHasBeenPressed" 2 "KeyIsStillHeld" ;
VAL_ 2565340673 KeyObjectID 0 "KeyHasBeenReleased" 1 "KeyHasBeenPressed" 2 "KeyIsStillHeld" ;
VAL_ 2565340673 ButtonActivationCode 3 "ButtonPressAborted" 0 "ButtonHasBeenUnlatched" 1 "ButtonHasBeenLatched" 2 "ButtonsStillHeld" ;
VAL_ 2565340673 AssignmentErrorNotAccepted 0 "AssignmentAccepted" 1 "Rejected_InputAlreadyAssigned" ;
VAL_ 2565340673 IsEnabled 0 "Disabled" 1 "Enabled" 255 "InputTypeIsAnalog" ;
VAL_ 2565340673 ShowOrHide 0 "Hide" 1 "Show" ;
VAL_ 2565340673 EnableOrDisable 0 "Disable" 1 "Enable" ;
VAL_ 2565340673 MaskType 1 "Data" 2 "Alarm" ;
VAL_ 2565799425 IndustryGroup 0 "Global" 1 "OnHighway" 2 "AgriculturalAndForestry" 3 "Construction" 4 "Marine" 5 "Reserved" 7 "NotAvailable" ;
VAL_ 2565799425 Function 127 "Reserved" 126 "Reserved" 125 "Reserved" 124 "Reserved" 123 "Reserved" 122 "Reserved" 121 "Reserved" 120 "Reserved" 119 "Reserved" 118 "Reserved" 117 "Reserved" 116 "Reserved" 115 "Reserved" 114 "Reserved" 113 "Reserved" 112 "Reserved" 111 "Reserved" 110 "Reserved" 109 "Reserved" 108 "Reserved" 107 "Reserved" 106 "Reserved" 105 "Reserved" 104 "Reserved" 103 "Reserved" 102 "Reserved" 101 "Reserved" 42 "Water Pump Control" 41 "Lighting - Operator Controls" 40 "Seat Control" 39 "Ignition Control Module" 38 "Tire Pressure Control" 37 "Cab Controller" 36 "Pneumatic - System Controller" 35 "Suspension - System Controller" 34 "Hydraulic Pump Controller" 33 "System Monitor" 32 "Headway Controller" 31 "Propulsion Battery Charger" 30 "Management Computer" 29 "Virtual Terminal (In Cab)" 28 "Off Vehicle Gateway" 27 "Power TakeOff (Secondary or Front)" 26 "Body Controller" 25 "Network Interconnect ECU" 24 "Vehicle Security" 23 "Vehicle Navigation" 22 "Aerodynamic Control" 21 "Cab Climate Control" 20 "Trip Recorder" 19 "Instrument Cluster" 18 "Suspension - Drive Axle" 17 "Suspension - Steer Axle" 16 "Steeting Controller" 15 "Fuel System" 14 "Cruise Control" 13 "Retarder - Driveline" 12 "Retarder - Engine" 11 "Brakes - Drive Axle" 10 "Brakes - Steer Axle" 9 "Brakes - System Controller" 8 "Axle - Drive" 7 "Axle - Steering" 6 "Power TakeOff - (Main or Rear)" 5 "Shift Control/Console" 4 "Battery Pack Monitor" 3 "Transmission" 2 "Electric Propulsion Control" 1 "Auxiliary Power Unit (APU)" 0 "Engine" 100 "Reserved" 99 "Reserved" 98 "Reserved" 97 "Reserved" 96 "Reserved" 95 "Reserved" 94 "Reserved" 93 "Reserved" 92 "Reserved" 91 "Reserved" 90 "Reserved" 89 "Reserved" 88 "Reserved" 87 "Reserved" 86 "Reserved" 85 "Reserved" 84 "Reserved" 83 "Reserved" 82 "Reserved" 81 "Reserved" 80 "Reserved" 79 "Reserved" 78 "Reserved" 77 "Reserved" 76 "Reserved" 75 "Reserved" 74 "Reserved" 73 "Reserved" 72 "Coolant Valve Controller" 71 "Transfer Case Control" 70 "Auxiliary Regeneration Device" 69 "Engine Emission Aftertreatement System" 68 "Aftertreatment system gas measurement" 67 "Electrical System Controller" 66 "I/O Controller" 65 "Gas Flow Measurement" 64 "Endurance Braking" 63 "Engine Valve Controller" 62 "On-Board Diagnostic Unit" 61 "File Server/Printer" 60 "Cab Display" 59 "Starter" 58 "Fan Drive Control" 57 "Steering Column Unit" 56 "Communications Unit, Radio" 55 "Communications Unit, Satellite" 54 "Communications Unit, Cellular" 53 "Alternator/Charging System" 52 "Chassis Controller" 51 "Forward-Looking Collision Warning System" 50 "Auxiliary Heater" 49 "Clutch/Converter Control" 48 "Ramp Control" 47 "Information System Controller" 46 "Oil Sensor Unit" 45 "Vehicle Dynamic Stability Control" 44 "Exhaust Emission Control" 43 "Transmission Display" ;
VAL_ 2565799425 ManufacturerCode 1863 "Thomas G. Faria Co." 1862 "Sanshin" 1861 "Vector North America" 1860 "MMP" 1859 "Kvasar AB" 1858 "Litton" 1857 "Simrad" 1856 "Trimble" 1855 "Furuno USA" 1854 "Northstar Technologies" 1853 "Japan Radio Co." 1852 "Navionics" 1851 "Raymarine" 1850 "Teleflex" 222 "Generac Power Systems, Inc." 221 "SiE" 220 "Beede Electrical Instrument Company, Inc." 219 "Cat OEM Solutions" 218 "Gits Manufacturing Company" 217 "RM Michaelides Software & Elektronik GmbH" 216 "Paneltronics Inc." 215 "Aetna Engineering/Fireboy-Xintex" 214 "MC elettronica Srl" 213 "CNH Belgium N.V." 212 "Sure Power Industries, Inc." 211 "DNA Group" 210 "Iteris, Inc." 209 "Bell Equip. Co. SA (PTY) LTD" 208 "Drew Technologies, Inc." 207 "Otto Engineering" 206 "port GmbH" 205 "SmarTire Systems Inc" 204 "The Morey Corporation" 203 "MILtronik GmbH" 202 "Curtis Instruments, Inc." 201 "Disenos y Tecnologia S.A." 200 "MGM Brakes" 199 "Actia Corp." 198 "Mystic Valley Communications" 197 "Mechron Power Systems" 196 "LEMKEN GmbH & Co. KG" 195 "General Engine Products" 194 "TriMark Corporation" 193 "Jeppesen Marine" 192 "Floscan" 191 "XATA Corporation" 190 "Hella KGaA Hueck & Co." 189 "QUALCOMM" 188 "EMP Corp." 187 "Air-Weigh" 186 "Altronic, Inc." 185 "Beede Electrical Instrument Company" 184 "EIA Electronics" 183 "KDS Controls, Inc." 182 "Vehicle Systems Engineering B.V." 181 "Coretronics, Inc." 180 "Smart Power Systems" 179 "Midwest Technologies Illinois, LLC" 178 "Siemens VDO Automotive AG" 177 "Diagnostic System Associates" 176 "Moritz Aerospace" 175 "Veris Technologies, Inc." 174 "AB Volvo Penta" 173 "Ryeso, Inc." 172 "Yanmar Marine USA" 171 "Wachendorff Elektronik GmbH & Co. KG" 170 "Computronics Corporation Ltd." 169 "Marlin Technologies Inc." 168 "Xantrex" 167 "JLG Industries Inc." 166 "Phoenix International" 165 "CPAC Systems AB" 164 "DaimlerChrysler Off-Highway" 163 "BRP Inc." 162 "Axiomatic Technologies" 161 "Offshore Systems (UK) Limited" 160 "Nido" 159 "NTech Industries Inc." 158 "Firestone Industrial Products Company" 157 "ISSPRO Inc." 156 "ITT Industries - Cannon" 155 "Vetronix Corporation" 154 "Westerbeke Corporation" 153 "Woodward, Industrial Controls Division" 152 "Elobau Elektrobauelemente GmbH & Co. KG" 151 "Raven Industries Inc. - Flow Controls Division" 150 "Fleetguard" 149 "Holset" 148 "Blue Water Data, Inc." 147 "Nautibus Electronic GmbH" 146 "Maxima Technologies" 145 "MurCal Controls" 144 "Mercury Marine" 143 "W. Gmeiner GmbH & Co." 142 "TRW Automotive (Commercial Steering Systems)" 141 "Thales Navigation Ltd." 140 "Lowrance Electronics, Inc." 139 "Caterpillar Trimble Control Technologies (CTCT), LLC" 138 "Georg Fritzmeier GmbH & Co. KG" 137 "Maretron" 136 "Komatsu Ltd." 135 "Airmar Technology Corporation" 134 "Iris Technology Ltd." 133 "Bucher Schoerling GmbH" 132 "Mulag-Fahrzeugwerk" 131 "ITT Industries" 130 "Nido - Universal Machines B.V." 129 "OMNEX Control Systems, Inc." 128 "Gerhard Duecker GmbH & Co. KG" 127 "Holland USA" 126 "Driver Tech" 125 "Nevada Automotive Test Center" 124 "Hydac Electronic" 123 "Basler Electric" 122 "FG Wilson (Engineering) Limited" 121 "HED (Hydro Electronic Devices, Inc.)" 120 "RDS Technology Ltd." 119 "IntegriNautics" 118 "Intron GmbH" 117 "HUSCO International" 116 "BEELINE Technologies" 115 "NACCO Materials Handling Group, Inc." 114 "EControls, Inc." 113 "Stress-Tek, Inc." 112 "MECALAC" 111 "Maschinenfabrik Bernhard Krone GmbH" 110 "EPIQ Sensor-Nite" 109 "LH Technologies ApS" 108 "WTK-Elecktronik GmbH" 107 "Grimme Landmaschinen GmbH & Co. KG" 106 "BAE Systems Controls, Inc." 105 "Kiepe Elektrik GmbH & Co. KG" 104 "Claas Selbstfahrende Erntemaschinen GmbH" 103 "Agrocom GmbH & Co. Agrarsystem KG" 102 "AGCO GmbH & Co." 101 "Sensoria" 100 "VDO Technik AG" 99 "International Transmissions Ltd (ITL)" 98 "Mueller-Elektronik GmbH & Co." 97 "Ag Leader Technology, Inc." 96 "Mech@tronic IT GmbH" 95 "Pacific Insight Electronics Corp." 94 "CNH Global N.V." 93 "Perkins Engines Company Ltd." 92 "Ag-Chem Equipment Co., Inc." 91 "BSG Bodensee Steuergeraete GmbH" 90 "Knorr-Bremse SfN GmbH" 89 "Kverneland Group, Electronics Division" 88 "Satloc Precision GPS" 87 "J.C. Bamford Excavators Ltd (JCB)" 86 "C.E. Niehoff & Company" 85 "Kohler Co." 84 "New Holland UK Limited" 83 "Eaton VORAD Technologies" 82 "Bobcat/Ingersoll-Rand" 81 "Fire Research Corp" 80 "Twin Disc, Inc." 79 "Daimler Benz AG - Engine Division (PBM)" 78 "Frank W. Murphy Manufacturing, Inc." 77 "Deere Power Systems Group" 76 "unused" 75 "Deere & Co. Agricultural Division" 74 "Eaton Axle-Brake Division" 73 "LeTourneau, Inc." 72 "Sisu Corporation" 71 "Vansco Electronics Ltd." 70 "Flex-Coil Limited" 69 "Trimble Navigation" 68 "Scania" 67 "Funk Manufacturing Company" 66 "John Deere Construction Equipment Division" 65 "MAN Nutzfahrzeuge AG" 64 "unused" 63 "ZF Industries Inc." 62 "Wabco" 61 "Volvo Truck Corp." 60 "Volvo Trucks North America Inc." 59 "VES Inc." 58 "SPX Corporation, OTC Division" 57 "Sauer-Danfoss Co." 56 "SAIC" 55 "Ryder System Inc." 54 "Meritor Wabco" 53 "Rockwell Land Transportation" 52 "Meritor Automotive, Inc." 51 "Robert Bosch GmbH" 50 "Robert Bosch Corp" 49 "RE America Inc." 48 "Pollak Alphabet" 47 "Phillips Semiconductor" 46 "Parasoft Computing Solutions" 45 "PACCAR" 44 "Nippondenso Co. Ltd." 43 "International Truck and Engine Corp. Vehicle Electronics" 42 "International Truck and Engine Corp. Engine Electronics" 41 "Motorola Inc." 40 "Motorola AIEG Inc." 39 "Microfirm Inc." 38 "Micro Processor Systems Inc." 37 "Mack Trucks Inc." 36 "Lucas Ltd." 35 "Kenworth Truck Co." 34 "Kelsey Hayes Co." 33 "John Deere" 32 "Jacobs Vehicle Systems" 31 "J Pollak Corp." 30 "Isuzu Motors Ltd." 29 "Hino Motors Ltd." 28 "Grote Ind. Inc." 27 "GMC" 26 "General Motors Corp., Service Technology Group" 25 "Freightliner LLC" 24 "Ford Motor Co., Vehicle Controls" 23 "Ford Motor Co., Heavy Truck" 22 "Ford Motor Co., Electronic Concepts $ Systems" 21 "Echilin Inc., Midland Brake Inc." 20 "Eaton Ltd" 19 "Eaton Corp. Trucking Info Services" 18 "Eaton Corp, Transmission Division" 17 "Eaton Corp. Res & Dev" 16 "Eaton Corp." 15 "Dickey-John Corp." 14 "Detroit Diesel Corporation" 13 "Delco Electronics" 12 "Deere & Company, Precision Farming" 11 "Dearborn Group Inc." 10 "Cummins Engine Co." 9 "Chrysler Corp." 8 "Caterpillar Inc." 7 "Case Corp." 6 "Berifors Electronics AB" 5 "AMP Inc." 4 "Ametek-Dixson" 3 "Ametek, US Gauge Division" 2 "Allison Transmission, GMC" 1 "Allied Signal Inc." 0 "Reserved" ;
VAL_ 2565799425 VehicleSystem 0 "Non-specific System" 127 "Not Available" ;
VAL_ 2565799425 VehicleSystem5 127 "Not Available" 0 "Ind. Process Control Stationary" ;
VAL_ 2565799425 VehicleSystem4 100 "Deck/Cargo/Fishing equip. sys" 90 "Environmental (HVAC) Systems" 80 "Instrumentation/General Systems" 70 "Communications Systems" 60 "Navigation Systems" 50 "Propulsion Systems" 40 "Steering Systems" 30 "Power Mgmt and lighting systems" 25 "Gateway" 20 "Safety Systems" 10 "System Tools" 127 "Not Available" 0 "Non-specific System" ;
VAL_ 2565799425 VehicleSystem3 8 "Grader" 7 "Four Wheel Drive Loader" 6 "Forklift" 5 "Excavator" 4 "Crawler" 3 "Backhoe" 2 "Articulated Dump Truck" 1 "Skid Steer Loader" 127 "Not Available" 0 "Non-specific System" ;
VAL_ 2565799425 VehicleSystem2 16 "Skidder" 15 "Earth Work" 14 "Special Crops" 13 "Powered Auxiliary Device" 12 "Farm Yard Operations" 11 "Transport/Trailer" 10 "Irrigation" 9 "Forage" 8 "Root Harvesters" 7 "Harvesters" 6 "Sprayers" 5 "Fertilizers" 4 "Planters/Seeders" 3 "Secondary Tillage" 2 "Tillage" 1 "Tractor" 127 "Not Available" 0 "Non-specific System" ;
VAL_ 2565799425 VehicleSystem1 2 "Trailer" 1 "Tractor" 127 "Not Available" 0 "Non-specific System" ;
VAL_ 2565799678 IndustryGroup 0 "Global" 1 "OnHighway" 2 "AgriculturalAndForestry" 3 "Construction" 4 "Marine" 5 "Reserved" 7 "NotAvailable" ;
VAL_ 2565799678 Function 127 "Reserved" 126 "Reserved" 125 "Reserved" 124 "Reserved" 123 "Reserved" 122 "Reserved" 121 "Reserved" 120 "Reserved" 119 "Reserved" 118 "Reserved" 117 "Reserved" 116 "Reserved" 115 "Reserved" 114 "Reserved" 113 "Reserved" 112 "Reserved" 111 "Reserved" 110 "Reserved" 109 "Reserved" 108 "Reserved" 107 "Reserved" 106 "Reserved" 105 "Reserved" 104 "Reserved" 103 "Reserved" 102 "Reserved" 101 "Reserved" 42 "Water Pump Control" 41 "Lighting - Operator Controls" 40 "Seat Control" 39 "Ignition Control Module" 38 "Tire Pressure Control" 37 "Cab Controller" 36 "Pneumatic - System Controller" 35 "Suspension - System Controller" 34 "Hydraulic Pump Controller" 33 "System Monitor" 32 "Headway Controller" 31 "Propulsion Battery Charger" 30 "Management Computer" 29 "Virtual Terminal (In Cab)" 28 "Off Vehicle Gateway" 27 "Power TakeOff (Secondary or Front)" 26 "Body Controller" 25 "Network Interconnect ECU" 24 "Vehicle Security" 23 "Vehicle Navigation" 22 "Aerodynamic Control" 21 "Cab Climate Control" 20 "Trip Recorder" 19 "Instrument Cluster" 18 "Suspension - Drive Axle" 17 "Suspension - Steer Axle" 16 "Steeting Controller" 15 "Fuel System" 14 "Cruise Control" 13 "Retarder - Driveline" 12 "Retarder - Engine" 11 "Brakes - Drive Axle" 10 "Brakes - Steer Axle" 9 "Brakes - System Controller" 8 "Axle - Drive" 7 "Axle - Steering" 6 "Power TakeOff - (Main or Rear)" 5 "Shift Control/Console" 4 "Battery Pack Monitor" 3 "Transmission" 2 "Electric Propulsion Control" 1 "Auxiliary Power Unit (APU)" 0 "Engine" 100 "Reserved" 99 "Reserved" 98 "Reserved" 97 "Reserved" 96 "Reserved" 95 "Reserved" 94 "Reserved" 93 "Reserved" 92 "Reserved" 91 "Reserved" 90 "Reserved" 89 "Reserved" 88 "Reserved" 87 "Reserved" 86 "Reserved" 85 "Reserved" 84 "Reserved" 83 "Reserved" 82 "Reserved" 81 "Reserved" 80 "Reserved" 79 "Reserved" 78 "Reserved" 77 "Reserved" 76 "Reserved" 75 "Reserved" 74 "Reserved" 73 "Reserved" 72 "Coolant Valve Controller" 71 "Transfer Case Control" 70 "Auxiliary Regeneration Device" 69 "Engine Emission Aftertreatement System" 68 "Aftertreatment system gas measurement" 67 "Electrical System Controller" 66 "I/O Controller" 65 "Gas Flow Measurement" 64 "Endurance Braking" 63 "Engine Valve Controller" 62 "On-Board Diagnostic Unit" 61 "File Server/Printer" 60 "Cab Display" 59 "Starter" 58 "Fan Drive Control" 57 "Steering Column Unit" 56 "Communications Unit, Radio" 55 "Communications Unit, Satellite" 54 "Communications Unit, Cellular" 53 "Alternator/Charging System" 52 "Chassis Controller" 51 "Forward-Looking Collision Warning System" 50 "Auxiliary Heater" 49 "Clutch/Converter Control" 48 "Ramp Control" 47 "Information System Controller" 46 "Oil Sensor Unit" 45 "Vehicle Dynamic Stability Control" 44 "Exhaust Emission Control" 43 "Transmission Display" ;
VAL_ 2565799678 ManufacturerCode 1863 "Thomas G. Faria Co." 1862 "Sanshin" 1861 "Vector North America" 1860 "MMP" 1859 "Kvasar AB" 1858 "Litton" 1857 "Simrad" 1856 "Trimble" 1855 "Furuno USA" 1854 "Northstar Technologies" 1853 "Japan Radio Co." 1852 "Navionics" 1851 "Raymarine" 1850 "Teleflex" 222 "Generac Power Systems, Inc." 221 "SiE" 220 "Beede Electrical Instrument Company, Inc." 219 "Cat OEM Solutions" 218 "Gits Manufacturing Company" 217 "RM Michaelides Software & Elektronik GmbH" 216 "Paneltronics Inc." 215 "Aetna Engineering/Fireboy-Xintex" 214 "MC elettronica Srl" 213 "CNH Belgium N.V." 212 "Sure Power Industries, Inc." 211 "DNA Group" 210 "Iteris, Inc." 209 "Bell Equip. Co. SA (PTY) LTD" 208 "Drew Technologies, Inc." 207 "Otto Engineering" 206 "port GmbH" 205 "SmarTire Systems Inc" 204 "The Morey Corporation" 203 "MILtronik GmbH" 202 "Curtis Instruments, Inc." 201 "Disenos y Tecnologia S.A." 200 "MGM Brakes" 199 "Actia Corp." 198 "Mystic Valley Communications" 197 "Mechron Power Systems" 196 "LEMKEN GmbH & Co. KG" 195 "General Engine Products" 194 "TriMark Corporation" 193 "Jeppesen Marine" 192 "Floscan" 191 "XATA Corporation" 190 "Hella KGaA Hueck & Co." 189 "QUALCOMM" 188 "EMP Corp." 187 "Air-Weigh" 186 "Altronic, Inc." 185 "Beede Electrical Instrument Company" 184 "EIA Electronics" 183 "KDS Controls, Inc." 182 "Vehicle Systems Engineering B.V." 181 "Coretronics, Inc." 180 "Smart Power Systems" 179 "Midwest Technologies Illinois, LLC" 178 "Siemens VDO Automotive AG" 177 "Diagnostic System Associates" 176 "Moritz Aerospace" 175 "Veris Technologies, Inc." 174 "AB Volvo Penta" 173 "Ryeso, Inc." 172 "Yanmar Marine USA" 171 "Wachendorff Elektronik GmbH & Co. KG" 170 "Computronics Corporation Ltd." 169 "Marlin Technologies Inc." 168 "Xantrex" 167 "JLG Industries Inc." 166 "Phoenix International" 165 "CPAC Systems AB" 164 "DaimlerChrysler Off-Highway" 163 "BRP Inc." 162 "Axiomatic Technologies" 161 "Offshore Systems (UK) Limited" 160 "Nido" 159 "NTech Industries Inc." 158 "Firestone Industrial Products Company" 157 "ISSPRO Inc." 156 "ITT Industries - Cannon" 155 "Vetronix Corporation" 154 "Westerbeke Corporation" 153 "Woodward, Industrial Controls Division" 152 "Elobau Elektrobauelemente GmbH & Co. KG" 151 "Raven Industries Inc. - Flow Controls Division" 150 "Fleetguard" 149 "Holset" 148 "Blue Water Data, Inc." 147 "Nautibus Electronic GmbH" 146 "Maxima Technologies" 145 "MurCal Controls" 144 "Mercury Marine" 143 "W. Gmeiner GmbH & Co." 142 "TRW Automotive (Commercial Steering Systems)" 141 "Thales Navigation Ltd." 140 "Lowrance Electronics, Inc." 139 "Caterpillar Trimble Control Technologies (CTCT), LLC" 138 "Georg Fritzmeier GmbH & Co. KG" 137 "Maretron" 136 "Komatsu Ltd." 135 "Airmar Technology Corporation" 134 "Iris Technology Ltd." 133 "Bucher Schoerling GmbH" 132 "Mulag-Fahrzeugwerk" 131 "ITT Industries" 130 "Nido - Universal Machines B.V." 129 "OMNEX Control Systems, Inc." 128 "Gerhard Duecker GmbH & Co. KG" 127 "Holland USA" 126 "Driver Tech" 125 "Nevada Automotive Test Center" 124 "Hydac Electronic" 123 "Basler Electric" 122 "FG Wilson (Engineering) Limited" 121 "HED (Hydro Electronic Devices, Inc.)" 120 "RDS Technology Ltd." 119 "IntegriNautics" 118 "Intron GmbH" 117 "HUSCO International" 116 "BEELINE Technologies" 115 "NACCO Materials Handling Group, Inc." 114 "EControls, Inc." 113 "Stress-Tek, Inc." 112 "MECALAC" 111 "Maschinenfabrik Bernhard Krone GmbH" 110 "EPIQ Sensor-Nite" 109 "LH Technologies ApS" 108 "WTK-Elecktronik GmbH" 107 "Grimme Landmaschinen GmbH & Co. KG" 106 "BAE Systems Controls, Inc." 105 "Kiepe Elektrik GmbH & Co. KG" 104 "Claas Selbstfahrende Erntemaschinen GmbH" 103 "Agrocom GmbH & Co. Agrarsystem KG" 102 "AGCO GmbH & Co." 101 "Sensoria" 100 "VDO Technik AG" 99 "International Transmissions Ltd (ITL)" 98 "Mueller-Elektronik GmbH & Co." 97 "Ag Leader Technology, Inc." 96 "Mech@tronic IT GmbH" 95 "Pacific Insight Electronics Corp." 94 "CNH Global N.V." 93 "Perkins Engines Company Ltd." 92 "Ag-Chem Equipment Co., Inc." 91 "BSG Bodensee Steuergeraete GmbH" 90 "Knorr-Bremse SfN GmbH" 89 "Kverneland Group, Electronics Division" 88 "Satloc Precision GPS" 87 "J.C. Bamford Excavators Ltd (JCB)" 86 "C.E. Niehoff & Company" 85 "Kohler Co." 84 "New Holland UK Limited" 83 "Eaton VORAD Technologies" 82 "Bobcat/Ingersoll-Rand" 81 "Fire Research Corp" 80 "Twin Disc, Inc." 79 "Daimler Benz AG - Engine Division (PBM)" 78 "Frank W. Murphy Manufacturing, Inc." 77 "Deere Power Systems Group" 76 "unused" 75 "Deere & Co. Agricultural Division" 74 "Eaton Axle-Brake Division" 73 "LeTourneau, Inc." 72 "Sisu Corporation" 71 "Vansco Electronics Ltd." 70 "Flex-Coil Limited" 69 "Trimble Navigation" 68 "Scania" 67 "Funk Manufacturing Company" 66 "John Deere Construction Equipment Division" 65 "MAN Nutzfahrzeuge AG" 64 "unused" 63 "ZF Industries Inc." 62 "Wabco" 61 "Volvo Truck Corp." 60 "Volvo Trucks North America Inc." 59 "VES Inc." 58 "SPX Corporation, OTC Division" 57 "Sauer-Danfoss Co." 56 "SAIC" 55 "Ryder System Inc." 54 "Meritor Wabco" 53 "Rockwell Land Transportation" 52 "Meritor Automotive, Inc." 51 "Robert Bosch GmbH" 50 "Robert Bosch Corp" 49 "RE America Inc." 48 "Pollak Alphabet" 47 "Phillips Semiconductor" 46 "Parasoft Computing Solutions" 45 "PACCAR" 44 "Nippondenso Co. Ltd." 43 "International Truck and Engine Corp. Vehicle Electronics" 42 "International Truck and Engine Corp. Engine Electronics" 41 "Motorola Inc." 40 "Motorola AIEG Inc." 39 "Microfirm Inc." 38 "Micro Processor Systems Inc." 37 "Mack Trucks Inc." 36 "Lucas Ltd." 35 "Kenworth Truck Co." 34 "Kelsey Hayes Co." 33 "John Deere" 32 "Jacobs Vehicle Systems" 31 "J Pollak Corp." 30 "Isuzu Motors Ltd." 29 "Hino Motors Ltd." 28 "Grote Ind. Inc." 27 "GMC" 26 "General Motors Corp., Service Technology Group" 25 "Freightliner LLC" 24 "Ford Motor Co., Vehicle Controls" 23 "Ford Motor Co., Heavy Truck" 22 "Ford Motor Co., Electronic Concepts $ Systems" 21 "Echilin Inc., Midland Brake Inc." 20 "Eaton Ltd" 19 "Eaton Corp. Trucking Info Services" 18 "Eaton Corp, Transmission Division" 17 "Eaton Corp. Res & Dev" 16 "Eaton Corp." 15 "Dickey-John Corp." 14 "Detroit Diesel Corporation" 13 "Delco Electronics" 12 "Deere & Company, Precision Farming" 11 "Dearborn Group Inc." 10 "Cummins Engine Co." 9 "Chrysler Corp." 8 "Caterpillar Inc." 7 "Case Corp." 6 "Berifors Electronics AB" 5 "AMP Inc." 4 "Ametek-Dixson" 3 "Ametek, US Gauge Division" 2 "Allison Transmission, GMC" 1 "Allied Signal Inc." 0 "Reserved" ;
VAL_ 2565799678 VehicleSystem 0 "Non-specific System" 127 "Not Available" ;
VAL_ 2565799678 VehicleSystem5 127 "Not Available" 0 "Ind. Process Control Stationary" ;
VAL_ 2565799678 VehicleSystem4 100 "Deck/Cargo/Fishing equip. sys" 90 "Environmental (HVAC) Systems" 80 "Instrumentation/General Systems" 70 "Communications Systems" 60 "Navigation Systems" 50 "Propulsion Systems" 40 "Steering Systems" 30 "Power Mgmt and lighting systems" 25 "Gateway" 20 "Safety Systems" 10 "System Tools" 127 "Not Available" 0 "Non-specific System" ;
VAL_ 2565799678 VehicleSystem3 8 "Grader" 7 "Four Wheel Drive Loader" 6 "Forklift" 5 "Excavator" 4 "Crawler" 3 "Backhoe" 2 "Articulated Dump Truck" 1 "Skid Steer Loader" 127 "Not Available" 0 "Non-specific System" ;
VAL_ 2565799678 VehicleSystem2 16 "Skidder" 15 "Earth Work" 14 "Special Crops" 13 "Powered Auxiliary Device" 12 "Farm Yard Operations" 11 "Transport/Trailer" 10 "Irrigation" 9 "Forage" 8 "Root Harvesters" 7 "Harvesters" 6 "Sprayers" 5 "Fertilizers" 4 "Planters/Seeders" 3 "Secondary Tillage" 2 "Tillage" 1 "Tractor" 127 "Not Available" 0 "Non-specific System" ;
VAL_ 2565799678 VehicleSystem1 2 "Trailer" 1 "Tractor" 127 "Not Available" 0 "Non-specific System" ;
VAL_ 2632384254 VTFunctionVTtoECU 193 "GetSupported WideCharsResponse" 37 "AuxiliaryInputStatusEnableCommand" 190 "ExecuteMacroResponse" 189 "LockUnlockMaskResponse" 35 "AuxiliaryInputMaintenance" 10 "VTControlAudioDeviceTermination" 9 "DisplayActivation" 186 "SelectColourMapResponse" 185 "GetAttributeValueResponse" 184 "GraphicsContextCommandResponse" 183 "ChangePolygonScaleResponse" 182 "ChangePolygonPointResponse" 181 "SetObjectLabelResponse" 0 "SoftKeyActivation" 1 "ButtonActivation" 2 "PointingEvent" 18 "EndOfObjectPoolResponse" 32 "AuxiliaryAssignmentCommand" 146 "ESCResponse" 160 "ShowHideObjectResponse" 161 "EnableDisableObjectResponse" 162 "SelectInputObjectResponse" 163 "ControlAudioDeviceResponse" 164 "SetAudioVolumeResponse" 165 "ChangeChildLocationResponse" 166 "ChangeSizeResponse" 167 "ChangeBackgroundColourResponse" 168 "ChangeNumericValueResponse" 169 "ChangeEndPointResponse" 170 "ChangeFontAttributesResponse" 171 "ChangeLineAttributesResponse" 172 "ChangeFillAttributesResponse" 173 "ChangeActiveMaskResponse" 174 "ChangeSoftKeyMaskResponse" 175 "ChangeAttributeResponse" 176 "ChangePriorityResponse" 177 "ChangeListItemResponse" 178 "DeleteObjectPoolResponse" 192 "GetMemoryResponse" 194 "GetNumberOfSoftKeysResponse" 195 "GetTextFontDataResponse" 199 "GetHardwareResponse" 208 "StoreVersionResponse" 209 "LoadVersionResponse" 210 "DeleteVersionResponse" 224 "GetVersionsResponse" 254 "VTStatusMessage" 33 "AuxiliaryInputStatus" 3 "VTSelectInputObject" 4 "VTESC" 5 "VTChangeNumericValue" 6 "VTChangeActiveMask" 7 "VTChangeSoftKeyMask" 8 "InputStringValue" 196 "GetFillAndLineDataResponse" 240 "VTObjectPoolErrorMessage" 179 "ChangeStringValueResponse" 180 "ChangeChildPositionResponse" 34 "AuxiliaryPreferredAssignmentResponse" ;
VAL_ 2632384254 KeyActivationCode 3 "KeyPressAborted" 0 "KeyHasBeenReleased" 1 "KeyHasBeenPressed" 2 "KeyIsStillPressed" ;
VAL_ 2632384254 KeyObjectID 0 "KeyHasBeenReleased" 1 "KeyHasBeenPressed" 2 "KeyIsStillPressed" ;
VAL_ 2632384254 KeyObjectParentID 0 "KeyHasBeenReleased" 1 "KeyHasBeenPressed" 2 "KeyIsStillPressed" ;
VAL_ 2632384254 SoftKeyCode 0 "AlarmACK" ;
VAL_ 2632384254 ButtonActivationCode 3 "ButtonPressAborted" 0 "ButtonHasBeenUnlatched" 1 "ButtonHasBeenLatched" 2 "ButtonIsStillHeld" ;
VAL_ 2632384254 TouchState 255 "Pressed" 2 "Held" 1 "Pressed" 0 "Released" ;
VAL_ 2632384254 VTSelectInputObjectStatus 0 "ObjectIsDeselected" 1 "ObjectIsSelected" ;
VAL_ 2632384254 VTSelectInputObjectIsEdited 0 "ObjectIsNotEdited" 1 "ObjectIsOpenForEditing" ;
VAL_ 2632384254 ErrorCodeVTEsc1 0 "NoError" 1 "NoInputFieldSelected ESC_Ignored" ;
VAL_ 2632384254 ErrorCodeVTEsc2 0 "NoError" 1 "GeneralError" ;
VAL_ 2632384254 ErrorCodeMissingObjects 0 "NoErrors" 1 "MissingObjects" ;
VAL_ 2632384254 ErrorCodeMaskOrChildObjectError 0 "NoErrors" 1 "MaskOrChildObjectHasErrors" ;
VAL_ 2632384254 ErrorCodeAnyOtherError 0 "NoErrors" 1 "GeneralError" ;
VAL_ 2632384254 ErrorCodePoolDeleted 0 "NoErrors" 1 "PoolBeingDeleted" ;
VAL_ 2632384254 ErrorCodeVTChangeSoftKeyMask1 0 "NoError" 1 "InvalidDataOrAlarmMaskObjectID" ;
VAL_ 2632384254 ErrorCodeVTChangeSoftKeyMask2 0 "NoError" 1 "InvalidSoftKeyMaskObjectID" ;
VAL_ 2632384254 ErrorCodeVTChangeSoftKeyMask3 0 "NoError" 1 "MissingObjects" ;
VAL_ 2632384254 ErrorCodeVTChangeSoftKeyMask4 0 "NoError" 1 "MaskOrChildObjectHasErrors" ;
VAL_ 2632384254 ErrorCodeVTChangeSoftKeyMask5 0 "NoError" 1 "GeneralError" ;
VAL_ 2632384254 ErrorCodeEndOfObjectPool1 1 "ErrorsInTheObjectPool" 0 "NoErrors" ;
VAL_ 2632384254 ErrorCodeEndOfObjectPool2 0 "NoErrors" 1 "VTRanOutOfMemoryDuringTransfer" ;
VAL_ 2632384254 ErrorCodeEndOfObjectPool3 0 "NoErrors" 1 "GeneralError" ;
VAL_ 2632384254 ErrorCodeObjectPool1 0 "NoErrors" 1 "MethodOrAttributeNotSupportedByV" ;
VAL_ 2632384254 ErrorCodeObjectPool2 0 "NoErrors" 1 "UnknownObjectReference" ;
VAL_ 2632384254 ErrorCodeObjectPool3 0 "NoErrors" 1 "GeneralError" ;
VAL_ 2632384254 ErrorCodeObjectPool4 0 "NoErrors" 1 "ObjectPoolWasDeletedFromVolatile" ;
VAL_ 2632384254 ManufacturerCode 1863 "Thomas G. Faria Co." 1862 "Sanshin" 1861 "Vector North America" 1860 "MMP" 1859 "Kvasar AB" 1858 "Litton" 1857 "Simrad" 1856 "Trimble" 1855 "Furuno USA" 1854 "Northstar Technologies" 1853 "Japan Radio Co." 1852 "Navionics" 1851 "Raymarine" 1850 "Teleflex" 222 "Generac Power Systems, Inc." 221 "SiE" 220 "Beede Electrical Instrument Company, Inc." 219 "Cat OEM Solutions" 218 "Gits Manufacturing Company" 217 "RM Michaelides Software & Elektronik GmbH" 216 "Paneltronics Inc." 215 "Aetna Engineering/Fireboy-Xintex" 214 "MC elettronica Srl" 213 "CNH Belgium N.V." 212 "Sure Power Industries, Inc." 211 "DNA Group" 210 "Iteris, Inc." 209 "Bell Equip. Co. SA (PTY) LTD" 208 "Drew Technologies, Inc." 207 "Otto Engineering" 206 "port GmbH" 205 "SmarTire Systems Inc" 204 "The Morey Corporation" 203 "MILtronik GmbH" 202 "Curtis Instruments, Inc." 201 "Disenos y Tecnologia S.A." 200 "MGM Brakes" 199 "Actia Corp." 198 "Mystic Valley Communications" 197 "Mechron Power Systems" 196 "LEMKEN GmbH & Co. KG" 195 "General Engine Products" 194 "TriMark Corporation" 193 "Jeppesen Marine" 192 "Floscan" 191 "XATA Corporation" 190 "Hella KGaA Hueck & Co." 189 "QUALCOMM" 188 "EMP Corp." 187 "Air-Weigh" 186 "Altronic, Inc." 185 "Beede Electrical Instrument Company" 184 "EIA Electronics" 183 "KDS Controls, Inc." 182 "Vehicle Systems Engineering B.V." 181 "Coretronics, Inc." 180 "Smart Power Systems" 179 "Midwest Technologies Illinois, LLC" 178 "Siemens VDO Automotive AG" 177 "Diagnostic System Associates" 176 "Moritz Aerospace" 175 "Veris Technologies, Inc." 174 "AB Volvo Penta" 173 "Ryeso, Inc." 172 "Yanmar Marine USA" 171 "Wachendorff Elektronik GmbH & Co. KG" 170 "Computronics Corporation Ltd." 169 "Marlin Technologies Inc." 168 "Xantrex" 167 "JLG Industries Inc." 166 "Phoenix International" 165 "CPAC Systems AB" 164 "DaimlerChrysler Off-Highway" 163 "BRP Inc." 162 "Axiomatic Technologies" 161 "Offshore Systems (UK) Limited" 160 "Nido" 159 "NTech Industries Inc." 158 "Firestone Industrial Products Company" 157 "ISSPRO Inc." 156 "ITT Industries - Cannon" 155 "Vetronix Corporation" 154 "Westerbeke Corporation" 153 "Woodward, Industrial Controls Division" 152 "Elobau Elektrobauelemente GmbH & Co. KG" 151 "Raven Industries Inc. - Flow Controls Division" 150 "Fleetguard" 149 "Holset" 148 "Blue Water Data, Inc." 147 "Nautibus Electronic GmbH" 146 "Maxima Technologies" 145 "MurCal Controls" 144 "Mercury Marine" 143 "W. Gmeiner GmbH & Co." 142 "TRW Automotive (Commercial Steering Systems)" 141 "Thales Navigation Ltd." 140 "Lowrance Electronics, Inc." 139 "Caterpillar Trimble Control Technologies (CTCT), LLC" 138 "Georg Fritzmeier GmbH & Co. KG" 137 "Maretron" 136 "Komatsu Ltd." 135 "Airmar Technology Corporation" 134 "Iris Technology Ltd." 133 "Bucher Schoerling GmbH" 132 "Mulag-Fahrzeugwerk" 131 "ITT Industries" 130 "Nido - Universal Machines B.V." 129 "OMNEX Control Systems, Inc." 128 "Gerhard Duecker GmbH & Co. KG" 127 "Holland USA" 126 "Driver Tech" 125 "Nevada Automotive Test Center" 124 "Hydac Electronic" 123 "Basler Electric" 122 "FG Wilson (Engineering) Limited" 121 "HED (Hydro Electronic Devices, Inc.)" 120 "RDS Technology Ltd." 119 "IntegriNautics" 118 "Intron GmbH" 117 "HUSCO International" 116 "BEELINE Technologies" 115 "NACCO Materials Handling Group, Inc." 114 "EControls, Inc." 113 "Stress-Tek, Inc." 112 "MECALAC" 111 "Maschinenfabrik Bernhard Krone GmbH" 110 "EPIQ Sensor-Nite" 109 "LH Technologies ApS" 108 "WTK-Elecktronik GmbH" 107 "Grimme Landmaschinen GmbH & Co. KG" 106 "BAE Systems Controls, Inc." 105 "Kiepe Elektrik GmbH & Co. KG" 104 "Claas Selbstfahrende Erntemaschinen GmbH" 103 "Agrocom GmbH & Co. Agrarsystem KG" 102 "AGCO GmbH & Co." 101 "Sensoria" 100 "VDO Technik AG" 99 "International Transmissions Ltd (ITL)" 98 "Mueller-Elektronik GmbH & Co." 97 "Ag Leader Technology, Inc." 96 "Mech@tronic IT GmbH" 95 "Pacific Insight Electronics Corp." 94 "CNH Global N.V." 93 "Perkins Engines Company Ltd." 92 "Ag-Chem Equipment Co., Inc." 91 "BSG Bodensee Steuergeraete GmbH" 90 "Knorr-Bremse SfN GmbH" 89 "Kverneland Group, Electronics Division" 88 "Satloc Precision GPS" 87 "J.C. Bamford Excavators Ltd (JCB)" 86 "C.E. Niehoff & Company" 85 "Kohler Co." 84 "New Holland UK Limited" 83 "Eaton VORAD Technologies" 82 "Bobcat/Ingersoll-Rand" 81 "Fire Research Corp" 80 "Twin Disc, Inc." 79 "Daimler Benz AG - Engine Division (PBM)" 78 "Frank W. Murphy Manufacturing, Inc." 77 "Deere Power Systems Group" 76 "unused" 75 "Deere & Co. Agricultural Division" 74 "Eaton Axle-Brake Division" 73 "LeTourneau, Inc." 72 "Sisu Corporation" 71 "Vansco Electronics Ltd." 70 "Flex-Coil Limited" 69 "Trimble Navigation" 68 "Scania" 67 "Funk Manufacturing Company" 66 "John Deere Construction Equipment Division" 65 "MAN Nutzfahrzeuge AG" 64 "unused" 63 "ZF Industries Inc." 62 "Wabco" 61 "Volvo Truck Corp." 60 "Volvo Trucks North America Inc." 59 "VES Inc." 58 "SPX Corporation, OTC Division" 57 "Sauer-Danfoss Co." 56 "SAIC" 55 "Ryder System Inc." 54 "Meritor Wabco" 53 "Rockwell Land Transportation" 52 "Meritor Automotive, Inc." 51 "Robert Bosch GmbH" 50 "Robert Bosch Corp" 49 "RE America Inc." 48 "Pollak Alphabet" 47 "Phillips Semiconductor" 46 "Parasoft Computing Solutions" 45 "PACCAR" 44 "Nippondenso Co. Ltd." 43 "International Truck and Engine Corp. Vehicle Electronics" 42 "International Truck and Engine Corp. Engine Electronics" 41 "Motorola Inc." 40 "Motorola AIEG Inc." 39 "Microfirm Inc." 38 "Micro Processor Systems Inc." 37 "Mack Trucks Inc." 36 "Lucas Ltd." 35 "Kenworth Truck Co." 34 "Kelsey Hayes Co." 33 "John Deere" 32 "Jacobs Vehicle Systems" 31 "J Pollak Corp." 30 "Isuzu Motors Ltd." 29 "Hino Motors Ltd." 28 "Grote Ind. Inc." 27 "GMC" 26 "General Motors Corp., Service Technology Group" 25 "Freightliner LLC" 24 "Ford Motor Co., Vehicle Controls" 23 "Ford Motor Co., Heavy Truck" 22 "Ford Motor Co., Electronic Concepts $ Systems" 21 "Echilin Inc., Midland Brake Inc." 20 "Eaton Ltd" 19 "Eaton Corp. Trucking Info Services" 18 "Eaton Corp, Transmission Division" 17 "Eaton Corp. Res & Dev" 16 "Eaton Corp." 15 "Dickey-John Corp." 14 "Detroit Diesel Corporation" 13 "Delco Electronics" 12 "Deere & Company, Precision Farming" 11 "Dearborn Group Inc." 10 "Cummins Engine Co." 9 "Chrysler Corp." 8 "Caterpillar Inc." 7 "Case Corp." 6 "Berifors Electronics AB" 5 "AMP Inc." 4 "Ametek-Dixson" 3 "Ametek, US Gauge Division" 2 "Allison Transmission, GMC" 1 "Allied Signal Inc." 0 "Reserved" ;
VAL_ 2632384254 Function 127 "Reserved" 126 "Reserved" 125 "Reserved" 124 "Reserved" 123 "Reserved" 122 "Reserved" 121 "Reserved" 120 "Reserved" 119 "Reserved" 118 "Reserved" 117 "Reserved" 116 "Reserved" 115 "Reserved" 114 "Reserved" 113 "Reserved" 112 "Reserved" 111 "Reserved" 110 "Reserved" 109 "Reserved" 108 "Reserved" 107 "Reserved" 106 "Reserved" 105 "Reserved" 104 "Reserved" 103 "Reserved" 102 "Reserved" 101 "Reserved" 42 "Water Pump Control" 41 "Lighting - Operator Controls" 40 "Seat Control" 39 "Ignition Control Module" 38 "Tire Pressure Control" 37 "Cab Controller" 36 "Pneumatic - System Controller" 35 "Suspension - System Controller" 34 "Hydraulic Pump Controller" 33 "System Monitor" 32 "Headway Controller" 31 "Propulsion Battery Charger" 30 "Management Computer" 29 "Virtual Terminal (In Cab)" 28 "Off Vehicle Gateway" 27 "Power TakeOff (Secondary or Front)" 26 "Body Controller" 25 "Network Interconnect ECU" 24 "Vehicle Security" 23 "Vehicle Navigation" 22 "Aerodynamic Control" 21 "Cab Climate Control" 20 "Trip Recorder" 19 "Instrument Cluster" 18 "Suspension - Drive Axle" 17 "Suspension - Steer Axle" 16 "Steeting Controller" 15 "Fuel System" 14 "Cruise Control" 13 "Retarder - Driveline" 12 "Retarder - Engine" 11 "Brakes - Drive Axle" 10 "Brakes - Steer Axle" 9 "Brakes - System Controller" 8 "Axle - Drive" 7 "Axle - Steering" 6 "Power TakeOff - (Main or Rear)" 5 "Shift Control/Console" 4 "Battery Pack Monitor" 3 "Transmission" 2 "Electric Propulsion Control" 1 "Auxiliary Power Unit (APU)" 0 "Engine" 100 "Reserved" 99 "Reserved" 98 "Reserved" 97 "Reserved" 96 "Reserved" 95 "Reserved" 94 "Reserved" 93 "Reserved" 92 "Reserved" 91 "Reserved" 90 "Reserved" 89 "Reserved" 88 "Reserved" 87 "Reserved" 86 "Reserved" 85 "Reserved" 84 "Reserved" 83 "Reserved" 82 "Reserved" 81 "Reserved" 80 "Reserved" 79 "Reserved" 78 "Reserved" 77 "Reserved" 76 "Reserved" 75 "Reserved" 74 "Reserved" 73 "Reserved" 72 "Coolant Valve Controller" 71 "Transfer Case Control" 70 "Auxiliary Regeneration Device" 69 "Engine Emission Aftertreatement System" 68 "Aftertreatment system gas measurement" 67 "Electrical System Controller" 66 "I/O Controller" 65 "Gas Flow Measurement" 64 "Endurance Braking" 63 "Engine Valve Controller" 62 "On-Board Diagnostic Unit" 61 "File Server/Printer" 60 "Cab Display" 59 "Starter" 58 "Fan Drive Control" 57 "Steering Column Unit" 56 "Communications Unit, Radio" 55 "Communications Unit, Satellite" 54 "Communications Unit, Cellular" 53 "Alternator/Charging System" 52 "Chassis Controller" 51 "Forward-Looking Collision Warning System" 50 "Auxiliary Heater" 49 "Clutch/Converter Control" 48 "Ramp Control" 47 "Information System Controller" 46 "Oil Sensor Unit" 45 "Vehicle Dynamic Stability Control" 44 "Exhaust Emission Control" 43 "Transmission Display" ;
VAL_ 2632384254 IndustryGroup 0 "Global" 1 "OnHighway" 2 "AgriculturalAndForestry" 3 "Construction" 4 "Marine" 5 "Reserved" 7 "NotAvailable" ;
VAL_ 2632384254 AuxPreferredAssignmentRespError1 1 "AuxiliaryInputUnit(s)NotValid" 0 "NoErrors" ;
VAL_ 2632384254 AuxPreferredAssignmentRespError2 1 "FunctionObjectID(s)NotValid" 0 "NoErrors" ;
VAL_ 2632384254 AuxPreferredAssignmentRespError3 1 "InputObjectID(s)NotValid" 0 "NoErrors" ;
VAL_ 2632384254 AuxPreferredAssignmentRespError4 1 "GeneralError" 0 "NoErrors" ;
VAL_ 2632384254 ErrorCodeEscapeObj1 0 "NoErrors" 1 "NoInputFieldSelected" ;
VAL_ 2632384254 ErrorCodeEscapeObj2 0 "NoErrors" 1 "GeneralError" ;
VAL_ 2632384254 ObjectShowStatus 0 "ObjectIsHidden" 1 "ObjectIsShown" ;
VAL_ 2632384254 ErrorCodeHideShowObj1 0 "NoErrors" 1 "ReferencesToMissingObjects" ;
VAL_ 2632384254 ErrorCodeHideShowObj2 0 "NoErrors" 1 "InvalidObjectID" ;
VAL_ 2632384254 ErrorCodeHideShowObj3 0 "NoErrors" 1 "GeneralError" ;
VAL_ 2632384254 ObjectEnableStatus 0 "ObjectIsDisabled" 1 "ObjectIsEnabled" ;
VAL_ 2632384254 ErrorCodeEnableDisableObj1 0 "NoErrors" 1 "InvalidObjectID" ;
VAL_ 2632384254 ErrorCodeEnableDisableObj2 0 "NoErrors" 1 "CommandError" ;
VAL_ 2632384254 ErrorCodeEnableDisableObj3 1 "Could not complete. Operator inp" 0 "NoErrors" ;
VAL_ 2632384254 ErrorCodeEnableDisableObj4 0 "NoErrors" 1 "GeneralError" ;
VAL_ 2632384254 ObjectSelectStatus 2 "ObjectIsOpenedForEdit" 0 "ObjectIsDeselectedOrObjectIDIsNullObject" 1 "ObjectIsSelected" ;
VAL_ 2632384254 ErrorCodeSelectObject1 1 "ObjectIsDisabled" 0 "NoErrors" ;
VAL_ 2632384254 ErrorCodeSelectObject2 0 "NoErrors" 1 "InvalidObjectID" ;
VAL_ 2632384254 ErrorCodeSelectObject3 0 "NoErrors" 1 "ObjectIsNotVisible" ;
VAL_ 2632384254 ErrorCodeSelectObject4 0 "NoErrors" 1 "CouldNotComplete" ;
VAL_ 2632384254 ErrorCodeSelectObject5 0 "NoErrors" 1 "GeneralError" ;
VAL_ 2632384254 ErrorCodeControlAudioDevice1 0 "NoErrors" 1 "AudioDeviceIsBusy" ;
VAL_ 2632384254 ErrorCodeControlAudioDevice2 0 "NoErrors" 1 "GeneralError" ;
VAL_ 2632384254 ErrorCodeAudioVolume1 0 "NoErrors" 1 "AudioDeviceIsBusy" ;
VAL_ 2632384254 ErrorCodeAudioVolume2 0 "NoErrors" 1 "GeneralError" ;
VAL_ 2632384254 ErrorCodeChangeChildLocation1 0 "NoErrors" 1 "InvalidParentObjectID" ;
VAL_ 2632384254 ErrorCodeChangeChildLocation2 0 "NoErrors" 1 "InvalidObjectID" ;
VAL_ 2632384254 ErrorCodeChangeChildLocation5 0 "NoErrors" 1 "GeneralError" ;
VAL_ 2632384254 ErrorCodeObjToSize1 0 "NoErrors" 1 "InvalidObjectID" ;
VAL_ 2632384254 ErrorCodeObjToSize2 0 "NoErrors" 1 "InvalidWidth" ;
VAL_ 2632384254 ErrorCodeObjToSize3 0 "NoErrors" 1 "InvalidHeight" ;
VAL_ 2632384254 ErrorCodeObjToSize4 0 "NoErrors" 1 "GeneralError" ;
VAL_ 2632384254 ErrorCodeChangeColour1 0 "NoErrors" 1 "InvalidObjectID" ;
VAL_ 2632384254 ErrorCodeChangeColour2 0 "NoErrors" 1 "InvalidColourCode" ;
VAL_ 2632384254 ErrorCodeChangeColour3 0 "NoErrors" 1 "GeneralError" ;
VAL_ 2632384254 ErrorCodeChangeNumValue1 0 "NoErrors" 1 "InvalidObjectID" ;
VAL_ 2632384254 ErrorCodeChangeNumValue2 0 "NoErrors" 1 "InvalidValue" ;
VAL_ 2632384254 ErrorCodeChangeNumValue3 0 "NoErrors" 1 "GeneralError" ;
VAL_ 2632384254 ErrorCodeChangeEditPoint1 0 "NoErrors" 1 "InvalidObjectID" ;
VAL_ 2632384254 ErrorCodeChangeEditPoint2 0 "NoErrors" 1 "InvalidLineDirection" ;
VAL_ 2632384254 ErrorCodeChangeEditPoint3 0 "NoErrors" 1 "GeneralError" ;
VAL_ 2632384254 ErrorCodeChangeFont1 0 "NoErrors" 1 "InvalidObjectID" ;
VAL_ 2632384254 ErrorCodeChangeFont2 0 "NoErrors" 1 "InvalidColour" ;
VAL_ 2632384254 ErrorCodeChangeFont4 0 "NoErrors" 1 "InvalidType" ;
VAL_ 2632384254 ErrorCodeChangeFont3 0 "NoErrors" 1 "InvalidSize" ;
VAL_ 2632384254 ErrorCodeChangeFont5 0 "NoErrors" 1 "InvalidStyle" ;
VAL_ 2632384254 ErrorCodeChangeFont6 0 "NoErrors" 1 "GeneralError" ;
VAL_ 2632384254 ErrorCodeChangeLineAttribute1 0 "NoErrors" 1 "InvalidObjectID" ;
VAL_ 2632384254 ErrorCodeChangeLineAttribute2 0 "NoErrors" 1 "InvalidObjectColour" ;
VAL_ 2632384254 ErrorCodeChangeLineAttribute3 0 "NoErrors" 1 "InvalidWidth" ;
VAL_ 2632384254 ErrorCodeChangeLineAttribute4 0 "NoErrors" 1 "GeneralError" ;
VAL_ 2632384254 ErrorCodeChangeFillAttributes1 0 "NoErrors" 1 "InvalidObjectID" ;
VAL_ 2632384254 ErrorCodeChangeFillAttributes2 0 "NoErrors" 1 "InvalidType" ;
VAL_ 2632384254 ErrorCodeChangeFillAttributes3 0 "NoErrors" 1 "InvalidColour" ;
VAL_ 2632384254 ErrorCodeChangeFillAttributes4 0 "NoErrors" 1 "InvalidPatternObjectID" ;
VAL_ 2632384254 ErrorCodeChangeFillAttributes5 0 "NoErrors" 1 "GeneralError" ;
VAL_ 2632384254 ErrorCodeChangeActiveMask1 0 "NoErrors" 1 "InvalidWorkingSetObject" ;
VAL_ 2632384254 ErrorCodeChangeActiveMask2 0 "NoErrors" 1 "InvalidMaskObjectID" ;
VAL_ 2632384254 ErrorCodeChangeActiveMask3 0 "NoErrors" 1 "MissingObjects" ;
VAL_ 2632384254 ErrorCodeChangeActiveMask4 0 "NoErrors" 1 "MaskOrChildObjectHasErrors" ;
VAL_ 2632384254 ErrorCodeChangeActiveMask5 0 "NoErrors" 1 "GeneralError" ;
VAL_ 2632384254 ErrorCodeChangeSoftKeyMask1 0 "NoErrors" 1 "InvalidDataOrAlarmMaskObjectID" ;
VAL_ 2632384254 ErrorCodeChangeSoftKeyMask2 0 "NoErrors" 1 "InvalidSoftKeyMaskObjectID" ;
VAL_ 2632384254 ErrorCodeChangeSoftKeyMask3 0 "NoErrors" 1 "Missing Objects" ;
VAL_ 2632384254 ErrorCodeChangeSoftKeyMask4 0 "NoErrors" 1 "Mask or child object has errors" ;
VAL_ 2632384254 ErrorCodeChangeSoftKeyMask5 0 "NoErrors" 1 "GeneralError" ;
VAL_ 2632384254 ErrorCodeChangeAttribute1 0 "NoErrors" 1 "InvalidObjectID" ;
VAL_ 2632384254 ErrorCodeChangeAttribute2 0 "NoErrors" 1 "InvalidAttributeID" ;
VAL_ 2632384254 ErrorCodeChangeAttribute3 0 "NoErrors" 1 "InvalidValue" ;
VAL_ 2632384254 ErrorCodeChangeAttribute4 0 "NoErrors" 1 "GeneralError" ;
VAL_ 2632384254 ErrorCodeChangePriority1 0 "NoErrors" 1 "InvalidObjectID" ;
VAL_ 2632384254 ErrorCodeChangePriority2 0 "NoErrors" 1 "InvalidPriority" ;
VAL_ 2632384254 ErrorCodeChangePriority3 0 "NoErrors" 1 "GeneralError" ;
VAL_ 2632384254 ErrorCodeChangeListItem1 0 "NoErrors" 1 "InvalidListObjectID" ;
VAL_ 2632384254 ErrorCodeChangeListItem2 0 "NoErrors" 1 "InvalidListIndex" ;
VAL_ 2632384254 ErrorCodeChangeListItem3 0 "NoErrors" 1 "InvalidNewListItemObjectID" ;
VAL_ 2632384254 ErrorCodeChangeListItem4 0 "NoErrors" 1 "GeneralError" ;
VAL_ 2632384254 ErrorCodeDeleteObjectPool1 0 "NoErrors" 1 "DeletionError" ;
VAL_ 2632384254 ErrorCodeDeleteObjectPool2 0 "NoErrors" 1 "GeneralError" ;
VAL_ 2632384254 ErrorCodeChangeStrObjectID 0 "NoErrors" 1 "InvalidObjectID" ;
VAL_ 2632384254 ErrorCodeChangeStrTooLong 0 "NoErrors" 1 "StringTooLong" ;
VAL_ 2632384254 ErrorCodeChangeStrError 0 "NoErrors" 1 "GeneralError" ;
VAL_ 2632384254 ErrorCodeChangePosInvalidParent 0 "NoErrors" 1 "InvalidParentObjectID" ;
VAL_ 2632384254 ErrorCodeChangePosInvalidObject 0 "NoErrors" 1 "InvalidObjectID" ;
VAL_ 2632384254 ErrorCodeChangePosInvalidError 0 "NoErrors" 1 "GeneralError" ;
VAL_ 2632384254 ErrorCodeSetObjectLabel1 1 "InvalidObjectId" 0 "NoError" ;
VAL_ 2632384254 ErrorCodeSetObjectLabel2 1 "InvalidStringVariableObjectId" 0 "NoError" ;
VAL_ 2632384254 ErrorCodeSetObjectLabel3 1 "InvalidFontType" 0 "NoError" ;
VAL_ 2632384254 ErrorCodeSetObjectLabel4 1 "InvalidDesignatorObjectReference" 0 "NoError" ;
VAL_ 2632384254 ErrorCodeSetObjectLabel5 1 "DesignatorReferencesInvalidObjects" 0 "NoError" ;
VAL_ 2632384254 ErrorCodeSetObjectLabel6 1 "GeneralError" 0 "NoError" ;
VAL_ 2632384254 ErrorCodeChangePoygonPoint1 1 "InvalidObjectId" 0 "NoError" ;
VAL_ 2632384254 ErrorCodeChangePoygonPoint2 1 "InvalidPointIndex" 0 "NoError" ;
VAL_ 2632384254 ErrorCodeChangePoygonPoint3 1 "GeneralError" 0 "NoError" ;
VAL_ 2632384254 ErrorCodeChangePolygonScale1 1 "InvalidObjectId" 0 "NoError" ;
VAL_ 2632384254 ErrorCodeChangePolygonScale5 1 "GeneralError" 0 "NoError" ;
VAL_ 2632384254 ErrorCodeGraphicsContextCmd1 1 "InvalidObjectID" 0 "NoError" ;
VAL_ 2632384254 ErrorCodeGraphicsContextCmd2 1 "InvalidCommandID" 0 "NoError" ;
VAL_ 2632384254 ErrorCodeGraphicsContextCmd3 1 "InvalidParameter" 0 "NoError" ;
VAL_ 2632384254 ErrorCodeGraphicsContextCmd4 1 "CommandWillProduceInvalidResults" 0 "NoError" ;
VAL_ 2632384254 ErrorCodeGraphicsContextCmd5 1 "GeneralError" 0 "NoError" ;
VAL_ 2632384254 ErrorCodeSelectColourMap2 1 "GeneralError" 0 "NoError" ;
VAL_ 2632384254 ErrorCodeSelectColourMap1 1 "InvalidObjectID" 0 "NoError" ;
VAL_ 2632384254 ErrorCodeLockUnlockMask9 1 "GeneralError" 0 "NoError" ;
VAL_ 2632384254 ErrorCodeLockUnlockMask8 1 "UnsolicitedUnlock_OperatorInduced" 0 "NoError" ;
VAL_ 2632384254 ErrorCodeLockUnlockMask7 1 "UnsolicitedUnlock_MaskChanged" 0 "NoError" ;
VAL_ 2632384254 ErrorCodeLockUnlockMask6 1 "UnsolicitedUnlock_TimeoutOccured" 0 "NoError" ;
VAL_ 2632384254 ErrorCodeLockUnlockMask5 1 "AlarmMaskIsActive" 0 "NoError" ;
VAL_ 2632384254 ErrorCodeLockUnlockMask4 1 "MaskNotLocked" 0 "NoError" ;
VAL_ 2632384254 ErrorCodeLockUnlockMask3 1 "MaskAlreadyLocked" 0 "NoError" ;
VAL_ 2632384254 ErrorCodeLockUnlockMask2 1 "MaskNotVisibleOrInvalidObjectId" 0 "NoError" ;
VAL_ 2632384254 ErrorCodeLockUnlockMask1 1 "WorkingSetNotActive" 0 "NoError" ;
VAL_ 2632384254 ErrorCodeExecuteMacro1 1 "ObjectIdNotExist" 0 "NoError" ;
VAL_ 2632384254 ErrorCodeExecuteMacro2 1 "ObjectIdIsNoMacro" 0 "NoError" ;
VAL_ 2632384254 ErrorCodeExecuteMacro3 1 "GeneralError" 0 "NoError" ;
VAL_ 2632384254 VersionNumberISO11783Part6 0 "Hannover Agritechnica 2001 limit" 1 "FDIS_Version" 2 "VersionOfThe1PublishedEdition" 3 "VersionOfThe2PublishedEdition" 4 "VersionOfThe3PublishedEdition" 5 "VersionOfThe4PublishedEdition" 6 "VersionOfThe5PublishedEdition" 7 "VersionOfThe6PublishedEdition" 8 "VersionOfThe7PublishedEdition" 9 "VersionOfThe8PublishedEdition" 10 "VersionOfThe9PublishedEdition" 11 "VersionOfThe10PublishedEdition" 12 "VersionOfThe11PublishedEdition" 13 "VersionOfThe12PublishedEdition" 14 "VersionOfThe13PublishedEdition" 15 "VersionOfThe14PublishedEdition" 16 "VersionOfThe15PublishedEdition" 17 "VersionOfThe16PublishedEdition" 18 "VersionOfThe17PublishedEdition" 19 "VersionOfThe18PublishedEdition" 20 "VersionOfThe19PublishedEdition" 21 "VersionOfThe20PublishedEdition" 22 "VersionOfThe21PublishedEdition" 23 "VersionOfThe22PublishedEdition" 24 "VersionOfThe23PublishedEdition" 25 "VersionOfThe24PublishedEdition" 26 "VersionOfThe25PublishedEdition" 27 "VersionOfThe26PublishedEdition" 28 "VersionOfThe27PublishedEdition" 29 "VersionOfThe28PublishedEdition" 30 "VersionOfThe29PublishedEdition" 31 "VersionOfThe30PublishedEdition" 32 "VersionOfThe31PublishedEdition" 33 "VersionOfThe32PublishedEdition" 34 "VersionOfThe33PublishedEdition" 35 "VersionOfThe34PublishedEdition" 36 "VersionOfThe35PublishedEdition" 37 "VersionOfThe36PublishedEdition" 38 "VersionOfThe37PublishedEdition" 39 "VersionOfThe38PublishedEdition" 40 "VersionOfThe39PublishedEdition" 41 "VersionOfThe40PublishedEdition" 42 "VersionOfThe41PublishedEdition" 43 "VersionOfThe42PublishedEdition" 44 "VersionOfThe43PublishedEdition" 45 "VersionOfThe44PublishedEdition" 46 "VersionOfThe45PublishedEdition" 47 "VersionOfThe46PublishedEdition" 48 "VersionOfThe47PublishedEdition" 49 "VersionOfThe48PublishedEdition" 50 "VersionOfThe50PublishedEdition" ;
VAL_ 2632384254 MemoryStatus 0 "EnoughMemoryMayBeAvailable" 1 "NotEnoughMemoryAvailable" ;
VAL_ 2632384254 ErrorCodeGetSupportedWideChars2 1 "GeneralError" 0 "NoError" ;
VAL_ 2632384254 ErrorCodeGetSupportedWideChars1 1 "TooManyRanges" 0 "NoError" ;
VAL_ 2632384254 FontSize_8x8 0 "NotSupported" 1 "Supported" ;
VAL_ 2632384254 FontSize_8x12 0 "NotSupported" 1 "Supported" ;
VAL_ 2632384254 FontSize_12x16 0 "NotSupported" 1 "Supported" ;
VAL_ 2632384254 FontSize_16x16 0 "NotSupported" 1 "Supported" ;
VAL_ 2632384254 FontSize_16x24 0 "NotSupported" 1 "Supported" ;
VAL_ 2632384254 FontSize_24x32 0 "NotSupported" 1 "Supported" ;
VAL_ 2632384254 FontSize_32x32 0 "NotSupported" 1 "Supported" ;
VAL_ 2632384254 FontSize_32x48 0 "NotSupported" 1 "Supported" ;
VAL_ 2632384254 FontSize_48x64 0 "NotSupported" 1 "Supported" ;
VAL_ 2632384254 FontSize_64x64 0 "NotSupported" 1 "Supported" ;
VAL_ 2632384254 FontSize_64x96 0 "NotSupported" 1 "Supported" ;
VAL_ 2632384254 FontSize_96x128 0 "NotSupported" 1 "Supported" ;
VAL_ 2632384254 FontSize_128x128 0 "NotSupported" 1 "Supported" ;
VAL_ 2632384254 FontSize_128x192 0 "NotSupported" 1 "Supported" ;
VAL_ 2632384254 FontType_BoldText 0 "NotSupported" 1 "Supported" ;
VAL_ 2632384254 FontType_CrossedOutText 0 "NotSupported" 1 "Supported" ;
VAL_ 2632384254 FontType_UnderlinedText 0 "NotSupported" 1 "Supported" ;
VAL_ 2632384254 FontType_ItalicsText 0 "NotSupported" 1 "Supported" ;
VAL_ 2632384254 FontType_InvertedText 0 "NotSupported" 1 "Supported" ;
VAL_ 2632384254 FontType_FlashInverted 0 "NotSupported" 1 "Supported" ;
VAL_ 2632384254 FontType_FlashHidden 0 "NotSupported" 1 "Supported" ;
VAL_ 2632384254 FontType_ProportionalFont 0 "NotSupported" 1 "Supported" ;
VAL_ 2632384254 LineArts 0 "LineArtIsNotSupported" 1 "LineArtIsSupported" ;
VAL_ 2632384254 FillTypes 0 "FillPaternIsNotSupported" 1 "FillPaternIsSupported" ;
VAL_ 2632384254 ShapeFillTypes 0 "FillOfEllipseAndPolygonNotSup" 1 "FillEllipseSupAndFillPolygNotSup" 2 "FillEllipseNotSupAndFillPolygSup" 3 "FillOfEllipseAndPolygonSup" ;
VAL_ 2632384254 SupportedGrapicMode 0 "Monocrome" 1 "Colour16" 2 "Colour256" ;
VAL_ 2632384254 Hardware1 0 "VT has no touch screen and no pointing device" 1 "VT has a touch screen or pointing device" ;
VAL_ 2632384254 Hardware2 0 "VT does not report drag operation" 1 "VT reports drag operation" ;
VAL_ 2632384254 Hardware3 0 "VT has no multiple frequency audio output" 1 "VT has multiple frequency audio output" ;
VAL_ 2632384254 Hardware4 0 "VT has no adjustable volume audio output" 1 "VT has adjustable volume audio output" ;
VAL_ 2632384254 Hardware5 0 "VT does not support simultaneous activations of softkeys" 1 "VT supports simultaneous activations of softkeys" ;
VAL_ 2632384254 Hardware6 0 "VT does not support intermediate coordinates during a drag operation" 1 "VT supports intermediate coordinates during a drag operation" ;
VAL_ 2632384254 AcknowledgmentStoreVersion 0 "SuccessfullyStored" 2 "VersionLabelIsNotCorrect" 4 "InsufficientMemoryAvailable" 8 "GeneralError" ;
VAL_ 2632384254 AcknowledgmentLoadVersion 0 "SuccessfullyLoaded" 2 "VersionLabelNotCorrectOrUnknown" 4 "InsufficientMemoryAvailable" 8 "GeneralError" ;
VAL_ 2632384254 AcknowledgmentDeleteVersion 0 "SuccessfullyDeleted" 2 "VersionLabelIsNotCorrect" 4 "NA" 8 "GeneralError" ;
VAL_ 2632384254 ErrorCodeVtObjPoolError1 0 "NoErrors" 1 "UnsupportedMethodOrAttribute" ;
VAL_ 2632384254 ErrorCodeVtObjPoolError2 0 "NoErrors" 1 "UnknownObjectReference" ;
VAL_ 2632384254 ErrorCodeVtObjPoolError3 0 "NoErrors" 1 "RecursiveObjectReference" ;
VAL_ 2632384254 ErrorCodeVtObjPoolError4 0 "NoErrors" 1 "OtherError" ;
VAL_ 2632384254 VTBusyCode1 1 "VTIsBusyUpdatingVisibleMask" ;
VAL_ 2632384254 VTBusyCode2 1 "VTIsBusySavingDataToNonVolMemory" ;
VAL_ 2632384254 VTBusyCode3 1 "VTIsBusyExecutingCommand" ;
VAL_ 2632384254 VTBusyCode4 1 "VTIsBusyExecutingMacro" ;
VAL_ 2632384254 VTBusyCode5 1 "VTIsBusyParsingAnObjectPool" ;
VAL_ 2632384254 VTBusyCode8 1 "VTIsOutOfMemory" ;
VAL_ 2565340926 VTFunctionECUtoVT 193 "GetSupported WideChars" 37 "AuxiliaryInputStatusEnableCommandResponse" 35 "AuxiliaryInputMaintenance" 190 "ExecuteMacro" 189 "LockUnlockMask" 34 "AuxiliaryPreferredAssignment" 9 "DisplayActivationResponse" 186 "SelectColourMap" 185 "GetAttribute" 184 "GraphicsContextCommand" 183 "ChangePolygonScale" 182 "ChangePolygonPoint" 181 "SetObjectLabel" 0 "SoftKeyActivationResponse" 1 "ButtonActivationResponse" 2 "PointingEventResponse" 18 "EndOfObjectPool" 32 "AuxiliaryAssignmentResponse" 146 "ESC" 160 "ShowHideObject" 161 "EnableDisableObject" 162 "SelectInputObject" 163 "ControlAudioDevice" 164 "SetAudioVolume" 165 "ChangeChildLocation" 166 "ChangeSize" 167 "ChangeBackgroundColour" 168 "ChangeNumericValue" 169 "ChangeEndPoint" 170 "ChangeFontAttributes" 171 "ChangeLineAttributes" 172 "ChangeFillAttributes" 173 "ChangeActiveMask" 174 "ChangeSoftKeyMask" 175 "ChangeAttribute" 176 "ChangePriority" 177 "ChangeListItem" 178 "DeleteObjectPool" 192 "GetMemory" 194 "GetNumberOfSoftKeys" 195 "GetTextFontData" 199 "GetHardware" 208 "StoreVersion" 209 "LoadVersion" 210 "DeleteVersion" 223 "GetVersions" 255 "WorkingSetMaintenance" 179 "ChangeStringValue" 3 "VTSelectInputObjectResponse" 4 "VTESCResponse" 5 "VTChangeNumericValueResponse" 6 "VTChangeActiveMaskResponse" 7 "VTChangeSoftKeyMaskResponse" 196 "GetFillAndLineData" 17 "ObjectPoolTransfer" 180 "ChangeChildPosition" 8 "InputStringValueResponse" ;
VAL_ 2565340926 KeyActivationCode 3 "KeyPressAborted" 0 "KeyHasBeenReleased" 1 "KeyHasBeenPressed" 2 "KeyIsStillHeld" ;
VAL_ 2565340926 KeyObjectParentID 0 "KeyHasBeenReleased" 1 "KeyHasBeenPressed" 2 "KeyIsStillHeld" ;
VAL_ 2565340926 KeyObjectID 0 "KeyHasBeenReleased" 1 "KeyHasBeenPressed" 2 "KeyIsStillHeld" ;
VAL_ 2565340926 ButtonActivationCode 3 "ButtonPressAborted" 0 "ButtonHasBeenUnlatched" 1 "ButtonHasBeenLatched" 2 "ButtonsStillHeld" ;
VAL_ 2565340926 AssignmentErrorNotAccepted 0 "AssignmentAccepted" 1 "Rejected_InputAlreadyAssigned" ;
VAL_ 2565340926 IsEnabled 0 "Disabled" 1 "Enabled" 255 "InputTypeIsAnalog" ;
VAL_ 2565340926 ShowOrHide 0 "Hide" 1 "Show" ;
VAL_ 2565340926 EnableOrDisable 0 "Disable" 1 "Enable" ;
VAL_ 2565340926 MaskType 1 "Data" 2 "Alarm" ;
VAL_ 2565537534 RqstedPGN 255 "NotAvailable" ;
VAL_ 2566787070 TimeFormatCmd 0 "Hour24" 1 "Hour12" 3 "NoAction" ;
VAL_ 2566787070 DecimalSymbolCmd 0 "CommaIsUsed" 1 "PointIsUsed" 3 "NoAction" ;
VAL_ 2566787070 DateFormatCmd 0 "ddmmyyyy" 1 "ddyyyymm" 2 "mmyyyydd" 3 "mmddyyyy" 4 "yyyymmdd" 5 "yyyyddmm" ;
VAL_ 2566787070 MassUnitCmd 0 "Metric" 1 "Imperial" 2 "TonsPounds" 3 "NoAction" ;
VAL_ 2566787070 VolumeUnitCmd 0 "Metric" 1 "Imperial" 2 "US" 3 "NoAction" ;
VAL_ 2566787070 AreaUnitCmd 0 "Metric" 1 "Imperial" 3 "NoAction" ;
VAL_ 2566787070 DistanceUnitCmd 0 "Metric" 1 "Imperial" 3 "NoAction" ;
VAL_ 2566787070 UnitsSystem 0 "Metric" 1 "Imperial" 2 "US" 3 "NoAction" ;
VAL_ 2566787070 ForceUnits 0 "Metric" 1 "Imperial" 2 "Reserved" 3 "NoAction" ;
VAL_ 2566787070 PressureUnits 0 "Metric" 1 "Imperial" 2 "Reserved" 3 "NoAction" ;
VAL_ 2566787070 TemperatureUnits 0 "Metric" 1 "Imperial" 2 "Reserved" 3 "NoAction" ;
VAL_ 2563309310 ConnectionAbortReason 7 "AnyOtherError" 6 "DuplicateSequenceNumber" 5 "BadSequenceNumber" 4 "UnexpectedDataTransferPacket" 3 "Timeout_CloseSession" 2 "NoFreeSystemResources" 1 "AlreadyConnManagedSession" ;
VAL_ 2563309310 ControlByte 23 "EEoMA" 22 "EDPO" 21 "ECTS" 20 "ERTS" 255 "EAbort" ;
VAL_ 2563309310 PGNumber 255 "NotAvailable" ;
